VERSION ""

NS_ :

BS_:

BU_: Turbocharger OnBoardDataLogger OffBoardDiagnosticTool2 OffBoardDiagnosticTool1 FileServer ParkingBrakeController SeatControl2 FanDriveController SteeringColumnUnit CommunicationUnitRadio CommunicationUnitSatellite CommunicationUnitCellular PropulsionBatteryCharger ChassisController2 ChassisController1 EngineValveControl AuxiliaryHeater2 AuxiliaryHeater1 ClutchUnit RampControl InformationSystem1 SuspensionSystemController2 OilSensor VehicleDynamicStability ExhaustEmissionController TransmissionDisplay2 TransmissionDisplay1 ClimateControl2 WaterPumpController RearAxleSteeringController LightingOperatorControl SeatController1 IgnitionController2 IgnitionController1 TirePressureController CabController2 CabController1 PneumaticSystemController SuspensionSystemController1 HydraulicPumpController EnduranceBrakingSystem RetarderExhaustEngine2 OnBoardDiagnosticUnit HeadwayController RetarderExhaustEngine1 CabDisplay1 ManagementComputer VirtualTerminal OffVehicleGateway PowerTakeOffFront HitchControl AuxiliaryValveControl BodyController TractorTrailerBridge1 StarterSystem ElectricalSystem VehicleSecurity VehicleNavigation AerodynamicControl ElectricalChargingSystem ClimateControl1 TripRecorder InstrumentCluster SuspensionDriveAxle2 SuspensionDriveAxle1 SuspensionSteerAxle SteeringController FuelSystem CruiseControl RetarderDriveline RetarderEngine BrakesDriveAxle2 BrakesDriveAxle1 BrakesSystemController BrakesSteerAxle AxleDrive2 AxleDrive1 AxleSteering PowerTakeOff ShiftConsoleSecondary ShiftConsolePrimary Transmission2 Transmission1 Engine2 Engine1

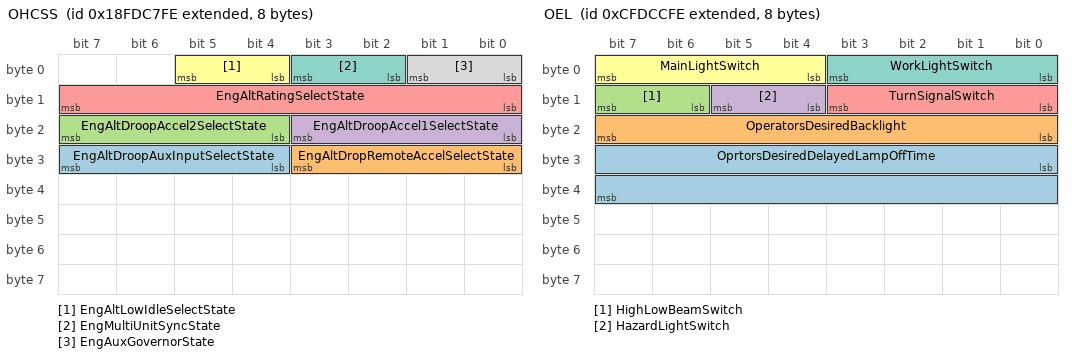
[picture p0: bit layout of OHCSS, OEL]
BO_ 2566768638 OHCSS: 8 Vector__XXX
 SG_ EngAltDroopAuxInputSelectState : 28|4@1+ (1,0) [0|15] "" Vector__XXX
 SG_ EngAltDropRemoteAccelSelectState : 24|4@1+ (1,0) [0|15] "" Vector__XXX
 SG_ EngAltDroopAccel2SelectState : 20|4@1+ (1,0) [0|15] "" Vector__XXX
 SG_ EngAltDroopAccel1SelectState : 16|4@1+ (1,0) [0|15] "" Vector__XXX
 SG_ EngAltRatingSelectState : 8|8@1+ (1,0) [0|255] "" Vector__XXX
 SG_ EngAltLowIdleSelectState : 4|2@1+ (1,0) [0|3] "" Vector__XXX
 SG_ EngMultiUnitSyncState : 2|2@1+ (1,0) [0|3] "" Vector__XXX
 SG_ EngAuxGovernorState : 0|2@1+ (1,0) [0|3] "" Vector__XXX

BO_ 2365443326 OEL: 8 Vector__XXX
 SG_ OprtorsDesiredDelayedLampOffTime : 24|16@1+ (1,0) [0|64255] "s" Vector__XXX
 SG_ OperatorsDesiredBacklight : 16|8@1+ (0.4,0) [0|100] "%" Vector__XXX
 SG_ HighLowBeamSwitch : 14|2@1+ (1,0) [0|3] "" Vector__XXX
 SG_ HazardLightSwitch : 12|2@1+ (1,0) [0|3] "" Vector__XXX
 SG_ TurnSignalSwitch : 8|4@1+ (1,0) [0|15] "" Vector__XXX
 SG_ MainLightSwitch : 4|4@1+ (1,0) [0|15] "" Vector__XXX
 SG_ WorkLightSwitch : 0|4@1+ (1,0) [0|15] "" Vector__XXX

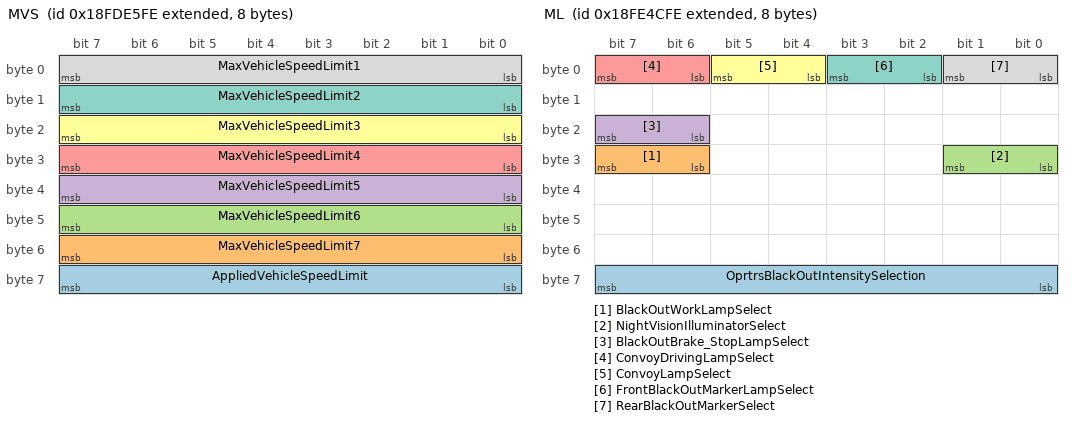
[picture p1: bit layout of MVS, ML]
BO_ 2566776318 MVS: 8 Vector__XXX
 SG_ AppliedVehicleSpeedLimit : 56|8@1+ (1,0) [0|250] "km/h" Vector__XXX
 SG_ MaxVehicleSpeedLimit7 : 48|8@1+ (1,0) [0|250] "km/h" Vector__XXX
 SG_ MaxVehicleSpeedLimit6 : 40|8@1+ (1,0) [0|250] "km/h" Vector__XXX
 SG_ MaxVehicleSpeedLimit5 : 32|8@1+ (1,0) [0|250] "km/h" Vector__XXX
 SG_ MaxVehicleSpeedLimit4 : 24|8@1+ (1,0) [0|250] "km/h" Vector__XXX
 SG_ MaxVehicleSpeedLimit3 : 16|8@1+ (1,0) [0|250] "km/h" Vector__XXX
 SG_ MaxVehicleSpeedLimit2 : 8|8@1+ (1,0) [0|250] "km/h" Vector__XXX
 SG_ MaxVehicleSpeedLimit1 : 0|8@1+ (1,0) [0|250] "km/h" Vector__XXX

BO_ 2566802686 ML: 8 Vector__XXX
 SG_ OprtrsBlackOutIntensitySelection : 56|8@1+ (1,0) [0|100] "%" Vector__XXX
 SG_ BlackOutWorkLampSelect : 30|2@1+ (1,0) [0|3] "" Vector__XXX
 SG_ NightVisionIlluminatorSelect : 24|2@1+ (1,0) [0|3] "" Vector__XXX
 SG_ BlackOutBrake_StopLampSelect : 22|2@1+ (1,0) [0|3] "" Vector__XXX
 SG_ ConvoyDrivingLampSelect : 6|2@1+ (1,0) [0|3] "" Vector__XXX
 SG_ ConvoyLampSelect : 4|2@1+ (1,0) [0|3] "" Vector__XXX
 SG_ FrontBlackOutMarkerLampSelect : 2|2@1+ (1,0) [0|3] "" Vector__XXX
 SG_ RearBlackOutMarkerSelect : 0|2@1+ (1,0) [0|3] "" Vector__XXX

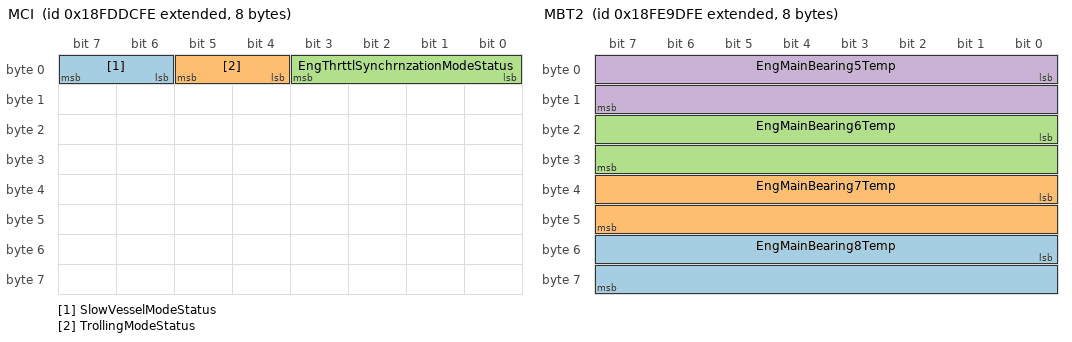
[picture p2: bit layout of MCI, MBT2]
BO_ 2566774014 MCI: 8 Vector__XXX
 SG_ SlowVesselModeStatus : 6|2@1+ (1,0) [0|3] "" Vector__XXX
 SG_ TrollingModeStatus : 4|2@1+ (1,0) [0|3] "" Vector__XXX
 SG_ EngThrttlSynchrnzationModeStatus : 0|4@1+ (1,0) [0|15] "" Vector__XXX

BO_ 2566823166 MBT3: 8 Vector__XXX
 SG_ EngMainBearing11Temp : 32|16@1+ (0.03125,-273) [-273|1734.96875] "deg C" Vector__XXX
 SG_ EngMainBearing10Temp : 16|16@1+ (0.03125,-273) [-273|1734.96875] "deg C" Vector__XXX
 SG_ EngMainBearing9Temp : 0|16@1+ (0.03125,-273) [-273|1734.96875] "deg C" Vector__XXX

BO_ 2566823422 MBT2: 8 Vector__XXX
 SG_ EngMainBearing8Temp : 48|16@1+ (0.03125,-273) [-273|1734.96875] "deg C" Vector__XXX
 SG_ EngMainBearing7Temp : 32|16@1+ (0.03125,-273) [-273|1734.96875] "deg C" Vector__XXX
 SG_ EngMainBearing6Temp : 16|16@1+ (0.03125,-273) [-273|1734.96875] "deg C" Vector__XXX
 SG_ EngMainBearing5Temp : 0|16@1+ (0.03125,-273) [-273|1734.96875] "deg C" Vector__XXX

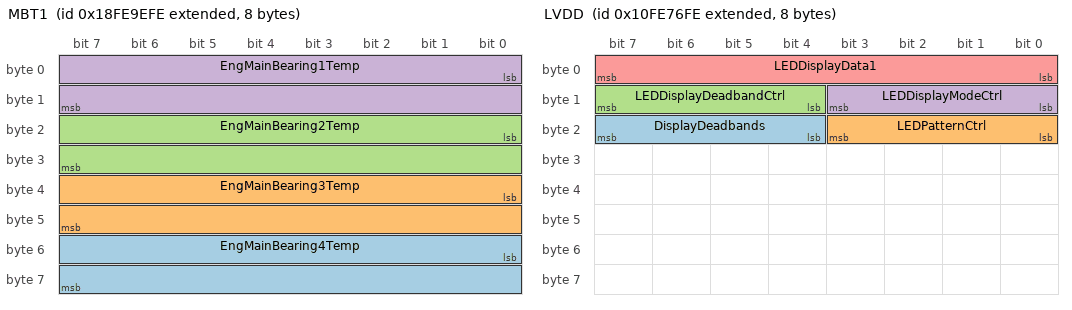
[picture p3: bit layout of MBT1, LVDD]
BO_ 2566823678 MBT1: 8 Vector__XXX
 SG_ EngMainBearing4Temp : 48|16@1+ (0.03125,-273) [-273|1734.96875] "deg C" Vector__XXX
 SG_ EngMainBearing3Temp : 32|16@1+ (0.03125,-273) [-273|1734.96875] "deg C" Vector__XXX
 SG_ EngMainBearing2Temp : 16|16@1+ (0.03125,-273) [-273|1734.96875] "deg C" Vector__XXX
 SG_ EngMainBearing1Temp : 0|16@1+ (0.03125,-273) [-273|1734.96875] "deg C" Vector__XXX

BO_ 2432595710 LVDD: 8 Vector__XXX
 SG_ DisplayDeadbands : 20|4@1+ (1,0) [0|15] "" Vector__XXX
 SG_ LEDPatternCtrl : 16|4@1+ (1,0) [0|15] "" Vector__XXX
 SG_ LEDDisplayDeadbandCtrl : 12|4@1+ (1,0) [0|15] "" Vector__XXX
 SG_ LEDDisplayModeCtrl : 8|4@1+ (1,0) [0|15] "" Vector__XXX
 SG_ LEDDisplayData1 : 0|8@1+ (1,0) [0|255] "" Vector__XXX

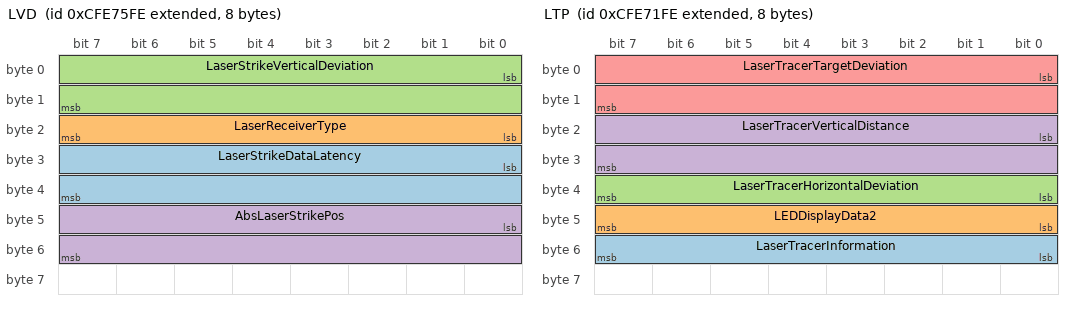
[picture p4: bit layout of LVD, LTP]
BO_ 2365486590 LVD: 8 Vector__XXX
 SG_ LaserStrikeDataLatency : 24|16@1+ (5.12E-005,0) [0|3.289856] "s" Vector__XXX
 SG_ LaserReceiverType : 16|8@1+ (1,0) [0|250] "" Vector__XXX
 SG_ LaserStrikeVerticalDeviation : 0|16@1+ (0.1,-3200) [-3200|3225.5] "mm" Vector__XXX
 SG_ AbsLaserStrikePos : 40|16@1+ (0.1,0) [0|6425.5] "mm" Vector__XXX

BO_ 2365485566 LTP: 8 Vector__XXX
 SG_ LaserTracerInformation : 48|8@1+ (1,0) [0|255] "" Vector__XXX
 SG_ LEDDisplayData2 : 40|8@1+ (1,0) [0|255] "" Vector__XXX
 SG_ LaserTracerHorizontalDeviation : 32|8@1+ (1,0) [0|250] "%" Vector__XXX
 SG_ LaserTracerVerticalDistance : 16|16@1+ (0.1,0) [0|6425.5] "mm" Vector__XXX
 SG_ LaserTracerTargetDeviation : 0|16@1+ (0.1,-3200) [-3200|3225.5] "mm" Vector__XXX

BO_ 2633939454 LTFI: 22 Vector__XXX
 SG_ TripCruiseFuelUsed : 128|32@1+ (0.5,0) [0|2105540607.5] "L" Vector__XXX
 SG_ TripVehicleIdleFuelUsed : 96|32@1+ (0.5,0) [0|2105540607.5] "L" Vector__XXX
 SG_ TripDriveFuelUsed : 0|32@1+ (0.5,0) [0|2105540607.5] "L" Vector__XXX
 SG_ TripPTOGovernorNonmovingFuelUsed : 64|32@1+ (0.5,0) [0|2105540607.5] "L" Vector__XXX
 SG_ TripPTOGovernorMovingFuelUsed : 32|32@1+ (0.5,0) [0|2105540607.5] "L" Vector__XXX
 SG_ TripDriveFuelEconomy : 160|16@1+ (0.0019531553964672,0) [0|125.5] "km/L" Vector__XXX

BO_ 2365486334 LSP: 8 Vector__XXX
 SG_ BldeHeightSetPointHighResolution : 16|32@1+ (1E-007,-209.7152) [-209.7152|211.3929215] "m" Vector__XXX
 SG_ ModifyLevelingSystemSetPoint : 0|16@1+ (0.1,-3200) [-3200|3225.5] "mm" Vector__XXX

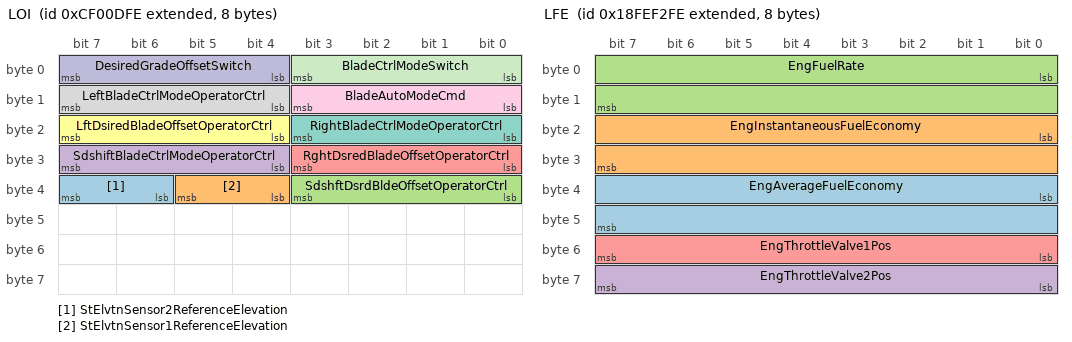
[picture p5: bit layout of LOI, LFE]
BO_ 2364542462 LOI: 8 Vector__XXX
 SG_ StElvtnSensor2ReferenceElevation : 38|2@1+ (1,0) [0|3] "" Vector__XXX
 SG_ StElvtnSensor1ReferenceElevation : 36|2@1+ (1,0) [0|3] "" Vector__XXX
 SG_ SdshftDsrdBldeOffsetOperatorCtrl : 32|4@1+ (1,0) [0|15] "" Vector__XXX
 SG_ SdshiftBladeCtrlModeOperatorCtrl : 28|4@1+ (1,0) [0|15] "" Vector__XXX
 SG_ RghtDsredBladeOffsetOperatorCtrl : 24|4@1+ (1,0) [0|15] "" Vector__XXX
 SG_ LftDsiredBladeOffsetOperatorCtrl : 20|4@1+ (1,0) [0|15] "" Vector__XXX
 SG_ RightBladeCtrlModeOperatorCtrl : 16|4@1+ (1,0) [0|15] "" Vector__XXX
 SG_ LeftBladeCtrlModeOperatorCtrl : 12|4@1+ (1,0) [0|15] "" Vector__XXX
 SG_ BladeAutoModeCmd : 8|4@1+ (1,0) [0|15] "" Vector__XXX
 SG_ DesiredGradeOffsetSwitch : 4|4@1+ (1,0) [0|15] "" Vector__XXX
 SG_ BladeCtrlModeSwitch : 0|4@1+ (1,0) [0|0] "" Vector__XXX

BO_ 2365486078 LMP: 8 Vector__XXX
 SG_ MastPos : 0|16@1+ (0.1,-3200) [-3200|3225.5] "mm" Vector__XXX

BO_ 2633937918 LFI: 8 Vector__XXX
 SG_ FlexibleFuelPercentage : 48|10@1+ (1,0) [0|102] "%" Vector__XXX
 SG_ TripAverageFuelRate : 32|16@1+ (0.05,0) [0|3212.75] "L/h" Vector__XXX
 SG_ TotalEngPTOGovernorFuelUsed : 0|32@1+ (0.5,0) [0|2105540607.5] "L" Vector__XXX

BO_ 2566845182 LFE: 8 Vector__XXX
 SG_ EngAverageFuelEconomy : 32|16@1+ (0.0019531553964672,0) [0|125.5] "km/L" Vector__XXX
 SG_ EngInstantaneousFuelEconomy : 16|16@1+ (0.0019531553964672,0) [0|125.5] "km/L" Vector__XXX
 SG_ EngFuelRate : 0|16@1+ (0.05,0) [0|3212.75] "L/h" Vector__XXX
 SG_ EngThrottleValve2Pos : 56|8@1+ (0.4,0) [0|100] "%" Vector__XXX
 SG_ EngThrottleValve1Pos : 48|8@1+ (0.4,0) [0|100] "%" Vector__XXX

BO_ 2566842878 LFC: 8 Vector__XXX
 SG_ EngTotalFuelUsed : 32|32@1+ (0.5,0) [0|2105540607.5] "L" Vector__XXX
 SG_ EngTripFuel : 0|32@1+ (0.5,0) [0|2105540607.5] "L" Vector__XXX

BO_ 2633883646 FWD: 8 Vector__XXX
 SG_ FrontWheelDriveActuatorStatus : 0|2@1+ (1,0) [0|3] "" Vector__XXX

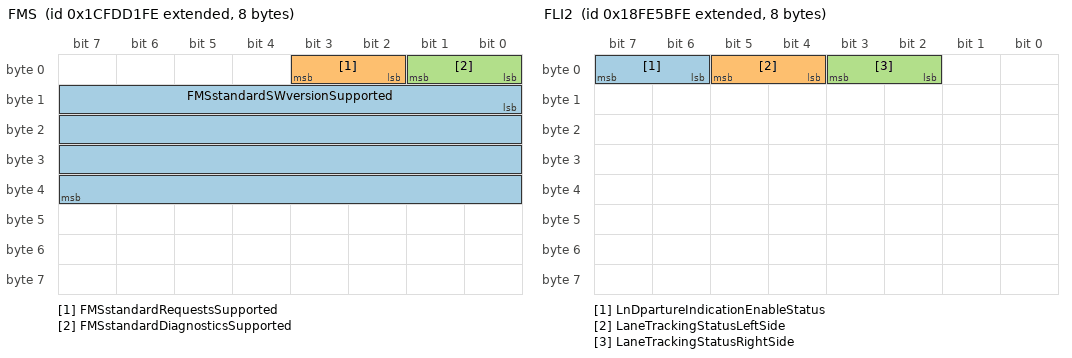
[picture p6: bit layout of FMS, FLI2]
BO_ 2633880062 FMS: 8 Vector__XXX
 SG_ FMSstandardSWversionSupported : 8|32@1+ (6.0554519606908E-008,0) [0|255] "per byte" Vector__XXX
 SG_ FMSstandardRequestsSupported : 2|2@1+ (1,0) [0|3] "" Vector__XXX
 SG_ FMSstandardDiagnosticsSupported : 0|2@1+ (1,0) [0|3] "" Vector__XXX

BO_ 2566806526 FLI2: 8 Vector__XXX
 SG_ LnDpartureIndicationEnableStatus : 6|2@1+ (1,0) [0|3] "" Vector__XXX
 SG_ LaneTrackingStatusLeftSide : 4|2@1+ (1,0) [0|3] "" Vector__XXX
 SG_ LaneTrackingStatusRightSide : 2|2@1+ (1,0) [0|3] "" Vector__XXX

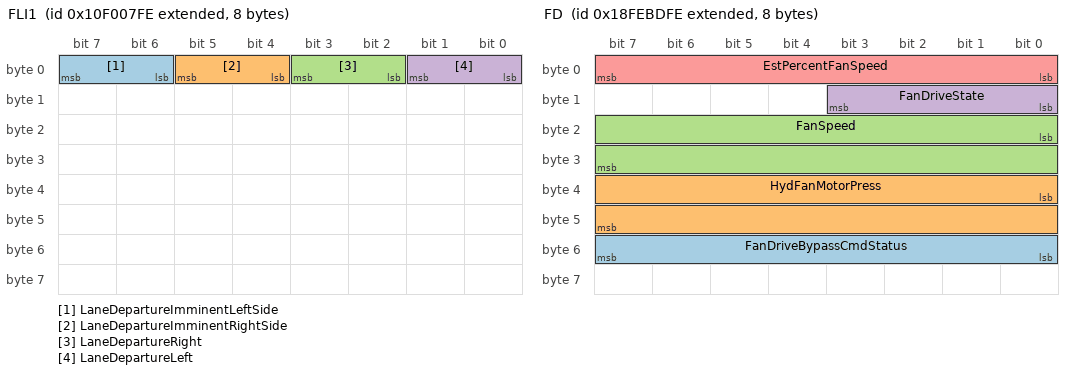
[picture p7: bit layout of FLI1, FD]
BO_ 2431649790 FLI1: 8 Vector__XXX
 SG_ LaneDepartureImminentLeftSide : 6|2@1+ (1,0) [0|3] "" Vector__XXX
 SG_ LaneDepartureImminentRightSide : 4|2@1+ (1,0) [0|3] "" Vector__XXX
 SG_ LaneDepartureRight : 2|2@1+ (1,0) [0|3] "" Vector__XXX
 SG_ LaneDepartureLeft : 0|2@1+ (1,0) [0|3] "" Vector__XXX

BO_ 2633929214 FL: 8 Vector__XXX
 SG_ EngFuelLeakage2 : 2|2@1+ (1,0) [0|3] "" Vector__XXX
 SG_ EngFuelLeakage1 : 0|2@1+ (1,0) [0|3] "" Vector__XXX

BO_ 2566831614 FD: 8 Vector__XXX
 SG_ FanDriveBypassCmdStatus : 48|8@1+ (1,0) [0|100] "%" Vector__XXX
 SG_ HydFanMotorPress : 32|16@1+ (0.5,0) [0|32127.5] "kPa" Vector__XXX
 SG_ FanSpeed : 16|16@1+ (0.125,0) [0|8031.875] "rpm" Vector__XXX
 SG_ FanDriveState : 8|4@1+ (1,0) [0|15] "" Vector__XXX
 SG_ EstPercentFanSpeed : 0|8@1+ (1,0) [0|100] "%" Vector__XXX

BO_ 2566820094 ETH: 8 Vector__XXX
 SG_ EngTorqueLimit6AxleInput : 248|16@1+ (2,0) [0|128510] "Nm" Vector__XXX
 SG_ EngTorqueLimit5Switch : 232|16@1+ (1,0) [0|64255] "Nm" Vector__XXX
 SG_ EngTorqueLimit4Trans : 216|16@1+ (1,0) [0|64255] "Nm" Vector__XXX
 SG_ EngTorqueLimit3Trans : 200|16@1+ (1,0) [0|64255] "Nm" Vector__XXX
 SG_ TransGearRatio3 : 184|16@1+ (0.01,0) [0|642.55] "" Vector__XXX
 SG_ EngTorqueLimit2Trans : 168|16@1+ (1,0) [0|64255] "Nm" Vector__XXX
 SG_ TransGearRatio2 : 152|16@1+ (0.01,0) [0|642.55] "" Vector__XXX
 SG_ EngTorqueLimit1Trans : 136|16@1+ (1,0) [0|64255] "Nm" Vector__XXX
 SG_ TransGearRatio1 : 120|16@1+ (0.01,0) [0|642.55] "" Vector__XXX
 SG_ EngTorqueLimitFeature : 114|3@1+ (1,0) [0|7] "" Vector__XXX
 SG_ TorqueLimitingFeatureStatus : 112|2@1+ (1,0) [0|3] "" Vector__XXX
 SG_ CalibRecordDurationTime : 80|32@1+ (0.05,0) [0|210554060.75] "hr" Vector__XXX
 SG_ CalibRecordStartYear : 72|8@1+ (1,1985) [1985|2235] "years" Vector__XXX
 SG_ CalibRecordStartDay : 64|8@1+ (0.25,0) [0|62.5] "days" Vector__XXX
 SG_ CalibRecordStartMonth : 56|8@1+ (1,0) [0|250] "months" Vector__XXX
 SG_ EngPeakTorque2 : 40|16@1+ (1,0) [0|64255] "Nm" Vector__XXX
 SG_ EngPeakTorque1 : 24|16@1+ (1,0) [0|64255] "Nm" Vector__XXX
 SG_ EngPower : 8|16@1+ (0.5,0) [0|32127.5] "kW" Vector__XXX
 SG_ NumberOfEngTorqueHistoryRecords : 0|8@1+ (1,0) [0|250] "records" Vector__XXX

BO_ 2364542206 ETC8: 8 Vector__XXX
 SG_ TransClutch_ConverterInputSpeed : 16|16@1+ (0.125,0) [0|8031.875] "rpm" Vector__XXX
 SG_ TransTorqueConverterRatio : 0|16@1+ (0.001,0) [0|64.255] "" Vector__XXX

BO_ 2566802174 ETC7: 8 Vector__XXX
 SG_ TrnsRverseGearShiftInhibitStatus : 40|2@1+ (1,0) [0|3] "" Vector__XXX
 SG_ TrnsCrrentRangeDisplayBlankState : 0|2@1+ (1,0) [0|3] "" Vector__XXX
 SG_ TransWarningIndicator : 42|2@1+ (1,0) [0|3] "" Vector__XXX
 SG_ TransMode8Indicator : 38|2@1+ (1,0) [0|3] "" Vector__XXX
 SG_ TransMode7Indicator : 36|2@1+ (1,0) [0|3] "" Vector__XXX
 SG_ TransMode6Indicator : 34|2@1+ (1,0) [0|3] "" Vector__XXX
 SG_ TransMode5Indicator : 32|2@1+ (1,0) [0|3] "" Vector__XXX
 SG_ TransRequestedGearFeedback : 24|8@1+ (1,-125) [-125|125] "" Vector__XXX
 SG_ TransMode1Indicator : 22|2@1+ (1,0) [0|3] "" Vector__XXX
 SG_ TransMode2Indicator : 20|2@1+ (1,0) [0|3] "" Vector__XXX
 SG_ TransMode3Indicator : 18|2@1+ (1,0) [0|3] "" Vector__XXX
 SG_ TransMode4Indicator : 16|2@1+ (1,0) [0|3] "" Vector__XXX
 SG_ TransShiftInhibitIndicator : 14|2@1+ (1,0) [0|3] "" Vector__XXX
 SG_ TransEngCrankEnable : 12|2@1+ (1,0) [0|3] "" Vector__XXX
 SG_ ActiveShiftConsoleIndicator : 10|2@1+ (1,0) [0|3] "" Vector__XXX
 SG_ TransReadyForBrakeRelease : 8|2@1+ (1,0) [0|3] "" Vector__XXX
 SG_ TrnsRqstedRangeDisplayFlashState : 6|2@1+ (1,0) [0|3] "" Vector__XXX
 SG_ TrnsRqstedRangeDisplayBlankState : 4|2@1+ (1,0) [0|3] "" Vector__XXX
 SG_ TransServiceIndicator : 2|2@1+ (1,0) [0|3] "" Vector__XXX

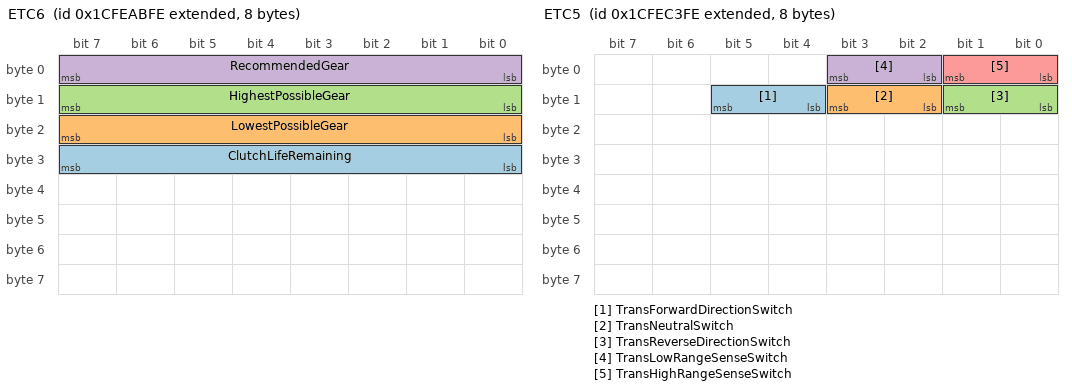
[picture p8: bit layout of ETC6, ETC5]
BO_ 2633935870 ETC6: 8 Vector__XXX
 SG_ ClutchLifeRemaining : 24|8@1+ (0.4,0) [0|100] "%" Vector__XXX
 SG_ LowestPossibleGear : 16|8@1+ (1,-125) [-125|125] "" Vector__XXX
 SG_ HighestPossibleGear : 8|8@1+ (1,-125) [-125|125] "" Vector__XXX
 SG_ RecommendedGear : 0|8@1+ (1,-125) [-125|125] "" Vector__XXX

BO_ 2633942014 ETC5: 8 Vector__XXX
 SG_ TransForwardDirectionSwitch : 12|2@1+ (1,0) [0|3] "" Vector__XXX
 SG_ TransNeutralSwitch : 10|2@1+ (1,0) [0|3] "" Vector__XXX
 SG_ TransReverseDirectionSwitch : 8|2@1+ (1,0) [0|3] "" Vector__XXX
 SG_ TransLowRangeSenseSwitch : 2|2@1+ (1,0) [0|3] "" Vector__XXX
 SG_ TransHighRangeSenseSwitch : 0|2@1+ (1,0) [0|3] "" Vector__XXX

BO_ 2633942526 ETC4: 8 Vector__XXX
 SG_ TransSynchronizerBrakeValue : 8|8@1+ (0.4,0) [0|100] "%" Vector__XXX
 SG_ TransSynchronizerClutchValue : 0|8@1+ (0.4,0) [0|100] "%" Vector__XXX

BO_ 2633943038 ETC3: 8 Vector__XXX
 SG_ TransInertiaBrakeActuator : 46|2@1+ (1,0) [0|3] "" Vector__XXX
 SG_ TransDefuelActuator : 44|2@1+ (1,0) [0|3] "" Vector__XXX
 SG_ TransLockupClutchActuator : 42|2@1+ (1,0) [0|3] "" Vector__XXX
 SG_ TransClutchActuator : 40|2@1+ (1,0) [0|3] "" Vector__XXX
 SG_ TransSplitterIndirectActuator : 38|2@1+ (1,0) [0|3] "" Vector__XXX
 SG_ TransSplitterDirectActuator : 36|2@1+ (1,0) [0|3] "" Vector__XXX
 SG_ TransRangeLowActuator : 34|2@1+ (1,0) [0|3] "" Vector__XXX
 SG_ TransRangeHighActuator : 32|2@1+ (1,0) [0|3] "" Vector__XXX
 SG_ TransShiftFingerGearActuator2 : 30|2@1+ (1,0) [0|3] "" Vector__XXX
 SG_ TransShiftFingerRailActuator2 : 28|2@1+ (1,0) [0|3] "" Vector__XXX
 SG_ TransShiftFingerGearActuator1 : 26|2@1+ (1,0) [0|3] "" Vector__XXX
 SG_ TransShiftFingerRailActuator1 : 24|2@1+ (1,0) [0|3] "" Vector__XXX
 SG_ TrnsShftFngerCenterRailIndicator : 20|2@1+ (1,0) [0|3] "" Vector__XXX
 SG_ TrnsShftFngerEngagementIndicator : 18|2@1+ (1,0) [0|3] "" Vector__XXX
 SG_ TransShiftFingerNeutralIndicator : 16|2@1+ (1,0) [0|3] "" Vector__XXX
 SG_ TransShiftFingerRailPos : 8|8@1+ (0.4,0) [0|100] "%" Vector__XXX
 SG_ TransShiftFingerGearPos : 0|8@1+ (0.4,0) [0|100] "%" Vector__XXX

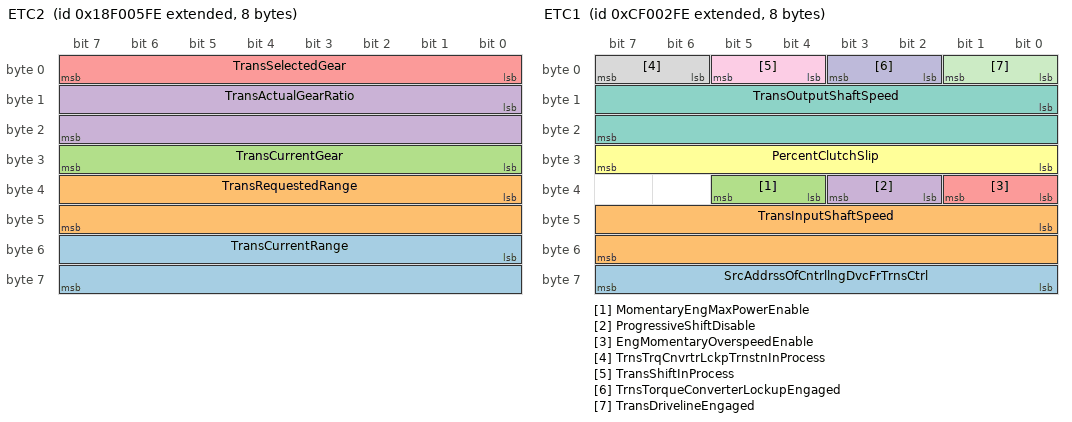
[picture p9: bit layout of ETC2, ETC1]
BO_ 2565867006 ETC2: 8 Vector__XXX
 SG_ TransCurrentRange : 48|16@1+ (1,0) [0|255] "per byte" Vector__XXX
 SG_ TransRequestedRange : 32|16@1+ (1,0) [0|255] "per byte" Vector__XXX
 SG_ TransCurrentGear : 24|8@1+ (1,-125) [-125|125] "" Vector__XXX
 SG_ TransActualGearRatio : 8|16@1+ (0.001,0) [0|64.255] "" Vector__XXX
 SG_ TransSelectedGear : 0|8@1+ (1,-125) [-125|125] "" Vector__XXX

BO_ 2364539646 ETC1: 8 Vector__XXX
 SG_ SrcAddrssOfCntrllngDvcFrTrnsCtrl : 56|8@1+ (1,0) [0|255] "" Vector__XXX
 SG_ TransInputShaftSpeed : 40|16@1+ (0.125,0) [0|8031.875] "rpm" Vector__XXX
 SG_ MomentaryEngMaxPowerEnable : 36|2@1+ (1,0) [0|3] "" Vector__XXX
 SG_ ProgressiveShiftDisable : 34|2@1+ (1,0) [0|3] "" Vector__XXX
 SG_ EngMomentaryOverspeedEnable : 32|2@1+ (1,0) [0|3] "" Vector__XXX
 SG_ PercentClutchSlip : 24|8@1+ (0.4,0) [0|100] "%" Vector__XXX
 SG_ TransOutputShaftSpeed : 8|16@1+ (0.125,0) [0|8031.875] "rpm" Vector__XXX
 SG_ TrnsTrqCnvrtrLckpTrnstnInProcess : 6|2@1+ (1,0) [0|3] "" Vector__XXX
 SG_ TransShiftInProcess : 4|2@1+ (1,0) [0|3] "" Vector__XXX
 SG_ TrnsTorqueConverterLockupEngaged : 2|2@1+ (1,0) [0|3] "" Vector__XXX
 SG_ TransDrivelineEngaged : 0|2@1+ (1,0) [0|3] "" Vector__XXX

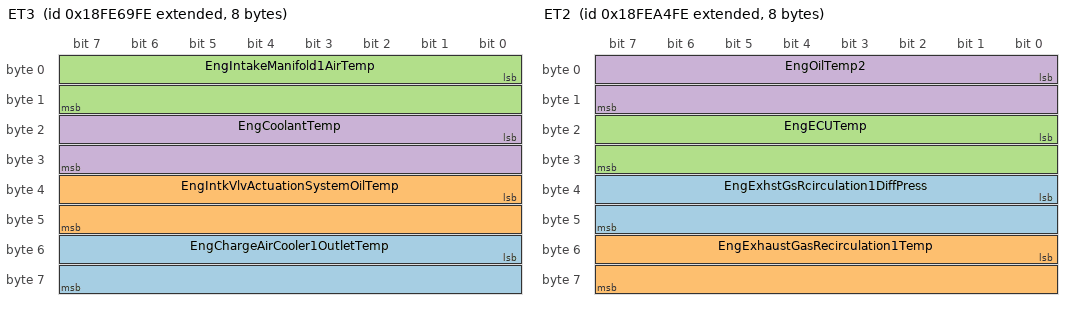
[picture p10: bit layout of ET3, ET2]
BO_ 2566810110 ET3: 8 Vector__XXX
 SG_ EngChargeAirCooler1OutletTemp : 48|16@1+ (0.03125,-273) [-273|1734.96875] "deg C" Vector__XXX
 SG_ EngIntkVlvActuationSystemOilTemp : 32|16@1+ (0.03125,-273) [-273|1734.96875] "deg C" Vector__XXX
 SG_ EngIntakeManifold1AirTemp : 0|16@1+ (0.03125,-273) [-273|1734.96875] "deg C" Vector__XXX
 SG_ EngCoolantTemp : 16|16@1+ (0.03125,-273) [-273|1734.96875] "deg C" Vector__XXX

BO_ 2566825214 ET2: 8 Vector__XXX
 SG_ EngExhstGsRcirculation1DiffPress : 32|16@1+ (0.0078124659559567,-250) [-250|251.99] "kPa" Vector__XXX
 SG_ EngExhaustGasRecirculation1Temp : 48|16@1+ (0.03125,-273) [-273|1734.96875] "deg C" Vector__XXX
 SG_ EngECUTemp : 16|16@1+ (0.03125,-273) [-273|1734.96875] "deg C" Vector__XXX
 SG_ EngOilTemp2 : 0|16@1+ (0.03125,-273) [-273|1734.96875] "deg C" Vector__XXX

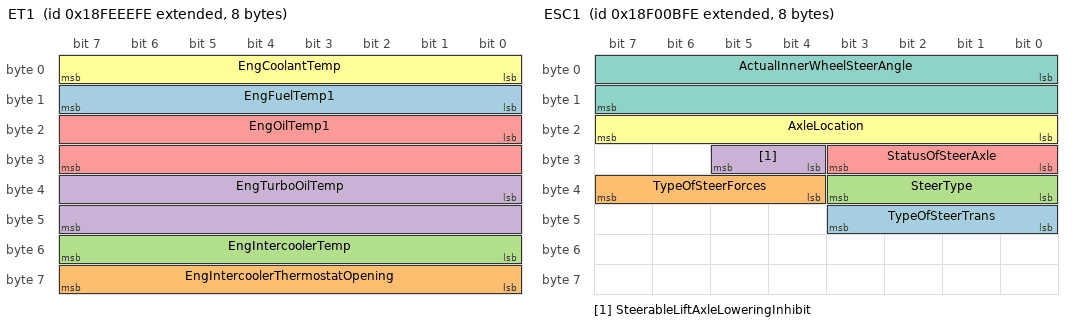
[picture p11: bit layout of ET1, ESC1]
BO_ 2566844158 ET1: 8 Vector__XXX
 SG_ EngFuelTemp1 : 8|8@1+ (1,-40) [-40|210] "deg C" Vector__XXX
 SG_ EngIntercoolerThermostatOpening : 56|8@1+ (0.4,0) [0|100] "%" Vector__XXX
 SG_ EngIntercoolerTemp : 48|8@1+ (1,-40) [-40|210] "deg C" Vector__XXX
 SG_ EngTurboOilTemp : 32|16@1+ (0.03125,-273) [-273|1734.96875] "deg C" Vector__XXX
 SG_ EngOilTemp1 : 16|16@1+ (0.03125,-273) [-273|1734.96875] "deg C" Vector__XXX
 SG_ EngCoolantTemp : 0|8@1+ (1,-40) [-40|210] "deg C" Vector__XXX

BO_ 2566785022 ET: 8 Vector__XXX
 SG_ EngExhaustGasTempLeftManifold : 16|16@1+ (0.03125,-273) [-273|1734.96875] "deg C" Vector__XXX
 SG_ EngExhaustGasTempRightManifold : 0|16@1+ (0.03125,-273) [-273|1734.96875] "deg C" Vector__XXX

BO_ 2565868542 ESC1: 8 Vector__XXX
 SG_ TypeOfSteerTrans : 40|4@1+ (1,0) [0|15] "" Vector__XXX
 SG_ TypeOfSteerForces : 36|4@1+ (1,0) [0|15] "" Vector__XXX
 SG_ SteerType : 32|4@1+ (1,0) [0|15] "" Vector__XXX
 SG_ SteerableLiftAxleLoweringInhibit : 28|2@1+ (1,0) [0|3] "" Vector__XXX
 SG_ StatusOfSteerAxle : 24|4@1+ (1,0) [0|15] "" Vector__XXX
 SG_ AxleLocation : 16|8@1+ (1.02,0) [0|255] "" Vector__XXX
 SG_ ActualInnerWheelSteerAngle : 0|16@1+ (0.0038907478017275,-125) [-125|125] "deg" Vector__XXX

BO_ 2633941758 ERC2: 8 Vector__XXX
 SG_ TransOutputRetarder : 0|2@1+ (1,0) [0|3] "" Vector__XXX

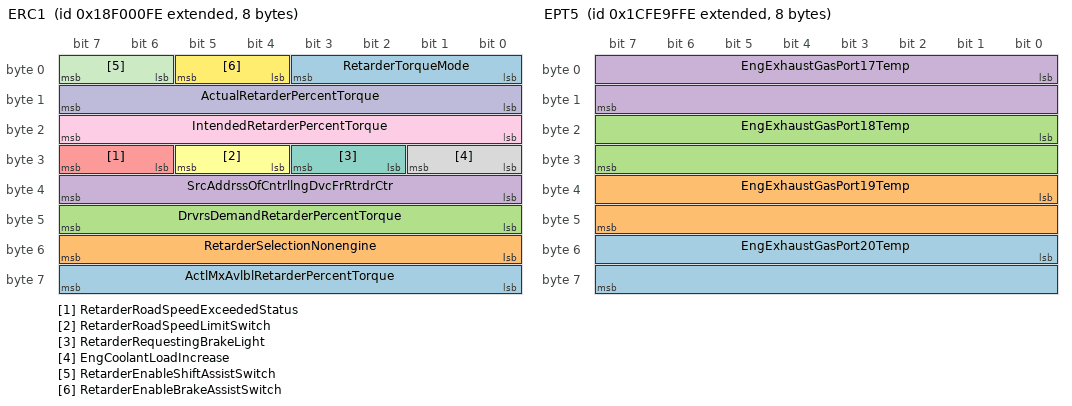
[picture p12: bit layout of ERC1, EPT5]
BO_ 2565865726 ERC1: 8 Vector__XXX
 SG_ ActlMxAvlblRetarderPercentTorque : 56|8@1+ (1,-125) [-125|125] "%" Vector__XXX
 SG_ RetarderSelectionNonengine : 48|8@1+ (0.4,0) [0|100] "%" Vector__XXX
 SG_ DrvrsDemandRetarderPercentTorque : 40|8@1+ (1,-125) [-125|125] "%" Vector__XXX
 SG_ SrcAddrssOfCntrllngDvcFrRtrdrCtr : 32|8@1+ (1,0) [0|255] "" Vector__XXX
 SG_ RetarderRoadSpeedExceededStatus : 30|2@1+ (1,0) [0|3] "" Vector__XXX
 SG_ RetarderRoadSpeedLimitSwitch : 28|2@1+ (1,0) [0|3] "" Vector__XXX
 SG_ RetarderRequestingBrakeLight : 26|2@1+ (1,0) [0|3] "" Vector__XXX
 SG_ EngCoolantLoadIncrease : 24|2@1+ (1,0) [0|3] "" Vector__XXX
 SG_ IntendedRetarderPercentTorque : 16|8@1+ (1,-125) [-125|125] "%" Vector__XXX
 SG_ ActualRetarderPercentTorque : 8|8@1+ (1,-125) [-125|125] "%" Vector__XXX
 SG_ RetarderEnableShiftAssistSwitch : 6|2@1+ (1,0) [0|3] "" Vector__XXX
 SG_ RetarderEnableBrakeAssistSwitch : 4|2@1+ (1,0) [0|3] "" Vector__XXX
 SG_ RetarderTorqueMode : 0|4@1+ (1,0) [0|15] "" Vector__XXX

BO_ 2633932798 EPT5: 8 Vector__XXX
 SG_ EngExhaustGasPort20Temp : 48|16@1+ (0.03125,-273) [-273|1734.96875] "deg C" Vector__XXX
 SG_ EngExhaustGasPort19Temp : 32|16@1+ (0.03125,-273) [-273|1734.96875] "deg C" Vector__XXX
 SG_ EngExhaustGasPort18Temp : 16|16@1+ (0.03125,-273) [-273|1734.96875] "deg C" Vector__XXX
 SG_ EngExhaustGasPort17Temp : 0|16@1+ (0.03125,-273) [-273|1734.96875] "deg C" Vector__XXX

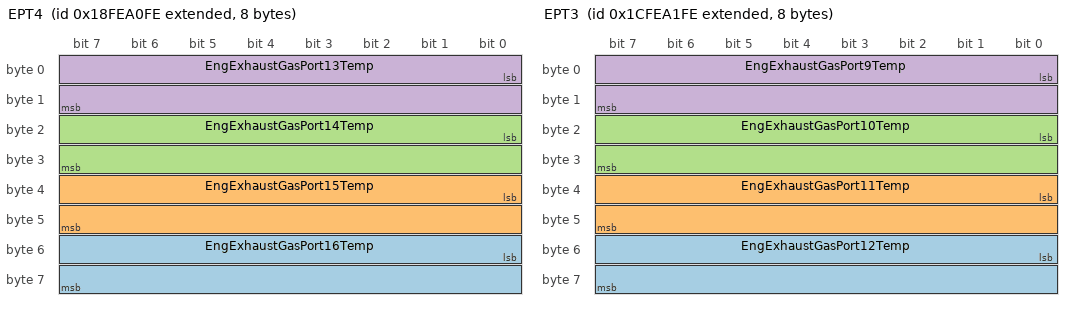
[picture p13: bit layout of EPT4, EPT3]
BO_ 2566824190 EPT4: 8 Vector__XXX
 SG_ EngExhaustGasPort16Temp : 48|16@1+ (0.03125,-273) [-273|1734.96875] "deg C" Vector__XXX
 SG_ EngExhaustGasPort15Temp : 32|16@1+ (0.03125,-273) [-273|1734.96875] "deg C" Vector__XXX
 SG_ EngExhaustGasPort14Temp : 16|16@1+ (0.03125,-273) [-273|1734.96875] "deg C" Vector__XXX
 SG_ EngExhaustGasPort13Temp : 0|16@1+ (0.03125,-273) [-273|1734.96875] "deg C" Vector__XXX

BO_ 2633933310 EPT3: 8 Vector__XXX
 SG_ EngExhaustGasPort12Temp : 48|16@1+ (0.03125,-273) [-273|1734.96875] "deg C" Vector__XXX
 SG_ EngExhaustGasPort11Temp : 32|16@1+ (0.03125,-273) [-273|1734.96875] "deg C" Vector__XXX
 SG_ EngExhaustGasPort10Temp : 16|16@1+ (0.03125,-273) [-273|1734.96875] "deg C" Vector__XXX
 SG_ EngExhaustGasPort9Temp : 0|16@1+ (0.03125,-273) [-273|1734.96875] "deg C" Vector__XXX

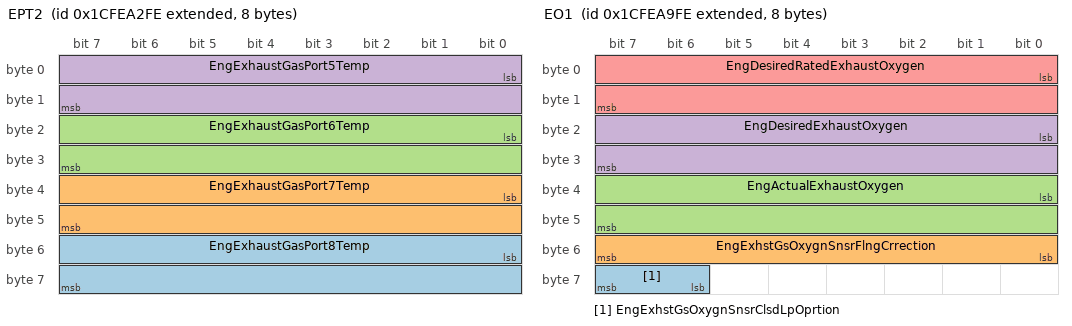
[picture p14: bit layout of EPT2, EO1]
BO_ 2633933566 EPT2: 8 Vector__XXX
 SG_ EngExhaustGasPort8Temp : 48|16@1+ (0.03125,-273) [-273|1734.96875] "deg C" Vector__XXX
 SG_ EngExhaustGasPort7Temp : 32|16@1+ (0.03125,-273) [-273|1734.96875] "deg C" Vector__XXX
 SG_ EngExhaustGasPort6Temp : 16|16@1+ (0.03125,-273) [-273|1734.96875] "deg C" Vector__XXX
 SG_ EngExhaustGasPort5Temp : 0|16@1+ (0.03125,-273) [-273|1734.96875] "deg C" Vector__XXX

BO_ 2633933822 EPT1: 8 Vector__XXX
 SG_ EngExhaustGasPort4Temp : 48|16@1+ (0.03125,-273) [-273|1734.96875] "deg C" Vector__XXX
 SG_ EngExhaustGasPort3Temp : 32|16@1+ (0.03125,-273) [-273|1734.96875] "deg C" Vector__XXX
 SG_ EngExhaustGasPort2Temp : 16|16@1+ (0.03125,-273) [-273|1734.96875] "deg C" Vector__XXX
 SG_ EngExhaustGasPort1Temp : 0|16@1+ (0.03125,-273) [-273|1734.96875] "deg C" Vector__XXX

BO_ 2566776062 EPD: 8 Vector__XXX
 SG_ PayloadPercentage : 0|8@1+ (1,0) [0|250] "%" Vector__XXX

BO_ 2566771454 EP: 8 Vector__XXX
 SG_ DataMemoryUsage : 16|8@1+ (0.4,0) [0|100] "%" Vector__XXX
 SG_ KeepAliveBatteryConsumption : 0|16@1+ (1,0) [0|64255] "mAhr" Vector__XXX

BO_ 2566775806 EOAC: 8 Vector__XXX
 SG_ TravelVelocityCtrlPos : 0|8@1+ (1,-125) [-125|125] "%" Vector__XXX

BO_ 2633935358 EO1: 8 Vector__XXX
 SG_ EngExhstGsOxygnSnsrClsdLpOprtion : 62|2@1+ (1,0) [0|3] "" Vector__XXX
 SG_ EngExhstGsOxygnSnsrFlngCrrection : 48|8@1+ (1,-125) [-125|125] "%" Vector__XXX
 SG_ EngActualExhaustOxygen : 32|16@1+ (0.0025,0) [0|160.6375] "%" Vector__XXX
 SG_ EngDesiredExhaustOxygen : 16|16@1+ (0.0025,0) [0|160.6375] "%" Vector__XXX
 SG_ EngDesiredRatedExhaustOxygen : 0|16@1+ (0.0025,0) [0|160.6375] "%" Vector__XXX

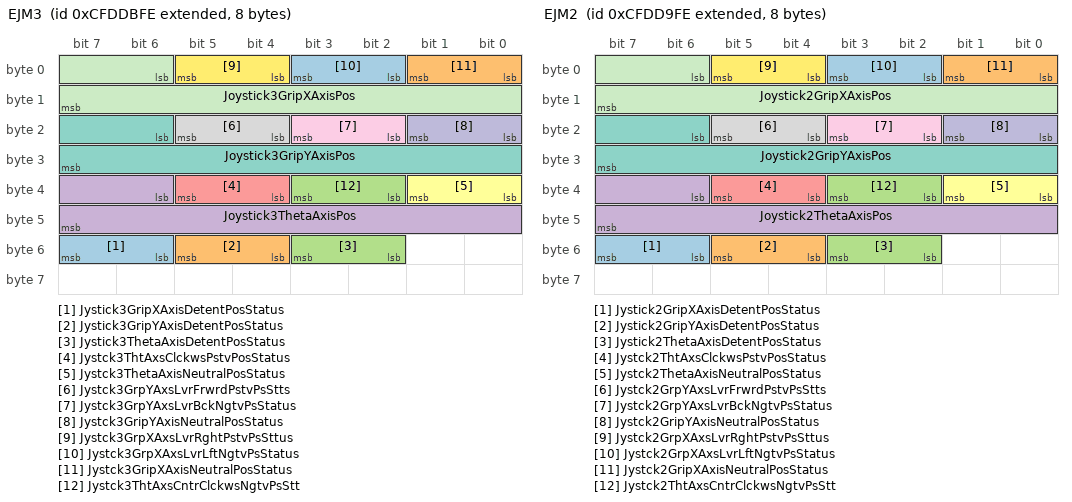
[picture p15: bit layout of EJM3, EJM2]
BO_ 2365447166 EJM3: 8 Vector__XXX
 SG_ Jystick3GripXAxisDetentPosStatus : 54|2@1+ (1,0) [0|3] "" Vector__XXX
 SG_ Jystick3GripYAxisDetentPosStatus : 52|2@1+ (1,0) [0|3] "" Vector__XXX
 SG_ Jystick3ThetaAxisDetentPosStatus : 50|2@1+ (1,0) [0|3] "" Vector__XXX
 SG_ Joystick3ThetaAxisPos : 38|10@1+ (1,0) [0|102] "%" Vector__XXX
 SG_ Jystck3ThtAxsClckwsPstvPosStatus : 36|2@1+ (1,0) [0|3] "" Vector__XXX
 SG_ Jystck3ThetaAxisNeutralPosStatus : 32|2@1+ (1,0) [0|3] "" Vector__XXX
 SG_ Joystick3GripYAxisPos : 22|10@1+ (1,0) [0|102] "%" Vector__XXX
 SG_ Jystck3GrpYAxsLvrFrwrdPstvPsStts : 20|2@1+ (1,0) [0|3] "" Vector__XXX
 SG_ Jystck3GrpYAxsLvrBckNgtvPsStatus : 18|2@1+ (1,0) [0|3] "" Vector__XXX
 SG_ Jystck3GripYAxisNeutralPosStatus : 16|2@1+ (1,0) [0|3] "" Vector__XXX
 SG_ Joystick3GripXAxisPos : 6|10@1+ (1,0) [0|102] "%" Vector__XXX
 SG_ Jystck3GrpXAxsLvrRghtPstvPsSttus : 4|2@1+ (1,0) [0|3] "" Vector__XXX
 SG_ Jystck3GrpXAxsLvrLftNgtvPsStatus : 2|2@1+ (1,0) [0|3] "" Vector__XXX
 SG_ Jystck3GripXAxisNeutralPosStatus : 0|2@1+ (1,0) [0|3] "" Vector__XXX
 SG_ Jystck3ThtAxsCntrClckwsNgtvPsStt : 34|2@1+ (1,0) [0|3] "" Vector__XXX

BO_ 2365446654 EJM2: 8 Vector__XXX
 SG_ Jystick2GripXAxisDetentPosStatus : 54|2@1+ (1,0) [0|3] "" Vector__XXX
 SG_ Jystick2GripYAxisDetentPosStatus : 52|2@1+ (1,0) [0|3] "" Vector__XXX
 SG_ Jystick2ThetaAxisDetentPosStatus : 50|2@1+ (1,0) [0|3] "" Vector__XXX
 SG_ Joystick2ThetaAxisPos : 38|10@1+ (1,0) [0|102] "%" Vector__XXX
 SG_ Jystck2ThtAxsClckwsPstvPosStatus : 36|2@1+ (1,0) [0|3] "" Vector__XXX
 SG_ Jystck2ThetaAxisNeutralPosStatus : 32|2@1+ (1,0) [0|3] "" Vector__XXX
 SG_ Joystick2GripYAxisPos : 22|10@1+ (1,0) [0|102] "%" Vector__XXX
 SG_ Jystck2GrpYAxsLvrFrwrdPstvPsStts : 20|2@1+ (1,0) [0|3] "" Vector__XXX
 SG_ Jystck2GrpYAxsLvrBckNgtvPsStatus : 18|2@1+ (1,0) [0|3] "" Vector__XXX
 SG_ Jystck2GripYAxisNeutralPosStatus : 16|2@1+ (1,0) [0|3] "" Vector__XXX
 SG_ Joystick2GripXAxisPos : 6|10@1+ (1,0) [0|102] "%" Vector__XXX
 SG_ Jystck2GrpXAxsLvrRghtPstvPsSttus : 4|2@1+ (1,0) [0|3] "" Vector__XXX
 SG_ Jystck2GrpXAxsLvrLftNgtvPsStatus : 2|2@1+ (1,0) [0|3] "" Vector__XXX
 SG_ Jystck2GripXAxisNeutralPosStatus : 0|2@1+ (1,0) [0|3] "" Vector__XXX
 SG_ Jystck2ThtAxsCntrClckwsNgtvPsStt : 34|2@1+ (1,0) [0|3] "" Vector__XXX

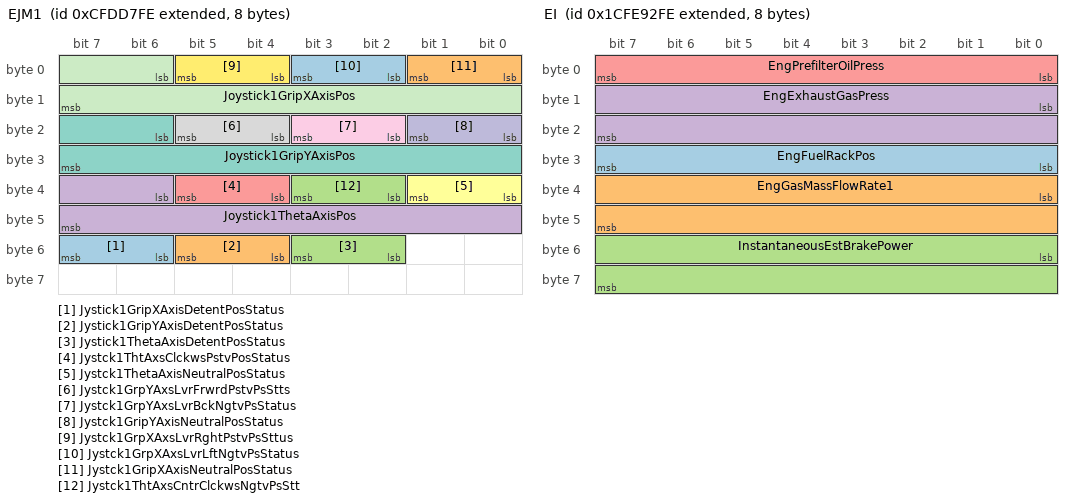
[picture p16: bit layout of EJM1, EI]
BO_ 2365446142 EJM1: 8 Vector__XXX
 SG_ Jystick1GripXAxisDetentPosStatus : 54|2@1+ (1,0) [0|3] "" Vector__XXX
 SG_ Jystick1GripYAxisDetentPosStatus : 52|2@1+ (1,0) [0|3] "" Vector__XXX
 SG_ Jystick1ThetaAxisDetentPosStatus : 50|2@1+ (1,0) [0|3] "" Vector__XXX
 SG_ Joystick1ThetaAxisPos : 38|10@1+ (1,0) [0|102] "%" Vector__XXX
 SG_ Jystck1ThtAxsClckwsPstvPosStatus : 36|2@1+ (1,0) [0|3] "" Vector__XXX
 SG_ Jystck1ThetaAxisNeutralPosStatus : 32|2@1+ (1,0) [0|3] "" Vector__XXX
 SG_ Joystick1GripYAxisPos : 22|10@1+ (1,0) [0|102] "%" Vector__XXX
 SG_ Jystck1GrpYAxsLvrFrwrdPstvPsStts : 20|2@1+ (1,0) [0|3] "" Vector__XXX
 SG_ Jystck1GrpYAxsLvrBckNgtvPsStatus : 18|2@1+ (1,0) [0|3] "" Vector__XXX
 SG_ Jystck1GripYAxisNeutralPosStatus : 16|2@1+ (1,0) [0|3] "" Vector__XXX
 SG_ Joystick1GripXAxisPos : 6|10@1+ (1,0) [0|102] "%" Vector__XXX
 SG_ Jystck1GrpXAxsLvrRghtPstvPsSttus : 4|2@1+ (1,0) [0|3] "" Vector__XXX
 SG_ Jystck1GrpXAxsLvrLftNgtvPsStatus : 2|2@1+ (1,0) [0|3] "" Vector__XXX
 SG_ Jystck1GripXAxisNeutralPosStatus : 0|2@1+ (1,0) [0|3] "" Vector__XXX
 SG_ Jystck1ThtAxsCntrClckwsNgtvPsStt : 34|2@1+ (1,0) [0|3] "" Vector__XXX

BO_ 2633929470 EI: 8 Vector__XXX
 SG_ EngFuelRackPos : 24|8@1+ (0.4,0) [0|100] "%" Vector__XXX
 SG_ EngGasMassFlowRate1 : 32|16@1+ (0.05,0) [0|3212.75] "kg/h" Vector__XXX
 SG_ InstantaneousEstBrakePower : 48|16@1+ (0.5,0) [0|32127.5] "kW" Vector__XXX
 SG_ EngExhaustGasPress : 8|16@1+ (0.0078124659559567,-250) [-250|251.99] "kPa" Vector__XXX
 SG_ EngPrefilterOilPress : 0|8@1+ (4,0) [0|1000] "kPa" Vector__XXX

BO_ 2633937406 EH: 8 Vector__XXX
 SG_ TotalECURunTime : 32|32@1+ (0.05,0) [0|210554060.75] "hr" Vector__XXX
 SG_ TotalECUDistance : 0|32@1+ (0.12500000000594,0) [0|526385151.9] "km" Vector__XXX

BO_ 2364541694 EGF1: 8 Vector__XXX
 SG_ EngExhstGsRcrcltion2MassFlowRate : 32|16@1+ (0.05,0) [0|3212.75] "kg/h" Vector__XXX
 SG_ EngIntakeAirMassFlowRate : 16|16@1+ (0.05,0) [0|3212.75] "kg/h" Vector__XXX
 SG_ EngExhstGsRcrcltion1MassFlowRate : 0|16@1+ (0.05,0) [0|3212.75] "kg/h" Vector__XXX

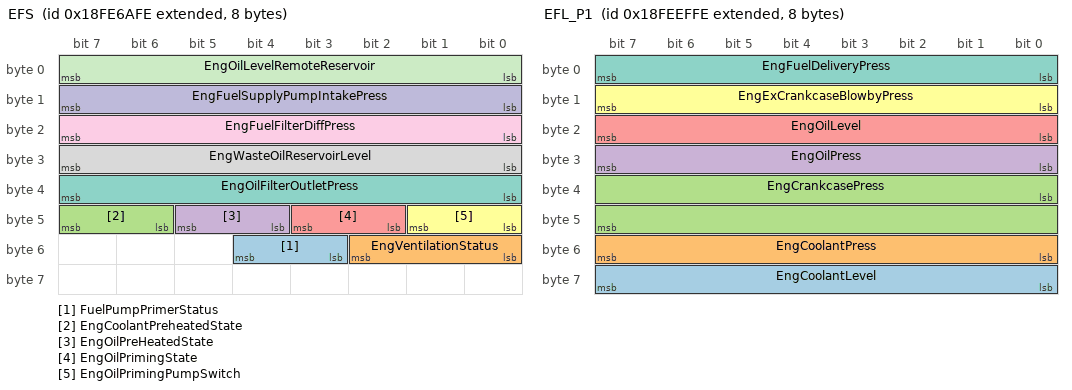
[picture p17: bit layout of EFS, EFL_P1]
BO_ 2566810366 EFS: 8 Vector__XXX
 SG_ FuelPumpPrimerStatus : 51|2@1+ (1,0) [0|3] "" Vector__XXX
 SG_ EngVentilationStatus : 48|3@1+ (1,0) [0|7] "" Vector__XXX
 SG_ EngCoolantPreheatedState : 46|2@1+ (1,0) [0|3] "" Vector__XXX
 SG_ EngOilPreHeatedState : 44|2@1+ (1,0) [0|3] "" Vector__XXX
 SG_ EngOilPrimingState : 42|2@1+ (1,0) [0|3] "" Vector__XXX
 SG_ EngOilPrimingPumpSwitch : 40|2@1+ (1,0) [0|3] "" Vector__XXX
 SG_ EngOilFilterOutletPress : 32|8@1+ (4,0) [0|1000] "kPa" Vector__XXX
 SG_ EngWasteOilReservoirLevel : 24|8@1+ (0.4,0) [0|100] "%" Vector__XXX
 SG_ EngFuelFilterDiffPress : 16|8@1+ (2,0) [0|500] "kPa" Vector__XXX
 SG_ EngFuelSupplyPumpIntakePress : 8|8@1+ (2,0) [0|500] "kPa" Vector__XXX
 SG_ EngOilLevelRemoteReservoir : 0|8@1+ (0.4,0) [0|100] "%" Vector__XXX

BO_ 2566767102 EFL_P3: 8 Vector__XXX
 SG_ EngExhstGsRcrclation1OutletPress : 40|8@1+ (2,0) [0|500] "kPa" Vector__XXX
 SG_ EngExhstVlvActtionSystemOilPress : 24|16@1+ (0.0039063107929344,0) [0|251] "MPa" Vector__XXX
 SG_ EngExhstGsRcrclation1IntakePress : 16|8@1+ (2,0) [0|500] "kPa" Vector__XXX
 SG_ EngIntkVlvActationSystemOilPress : 0|16@1+ (0.0039063107929344,0) [0|251] "MPa" Vector__XXX

BO_ 2566839294 EFL_P2: 8 Vector__XXX
 SG_ EngInjectorMeteringRail2Press : 48|16@1+ (0.0039063107929344,0) [0|251] "MPa" Vector__XXX
 SG_ EngInjectorTimingRail1Press : 32|16@1+ (0.0039063107929344,0) [0|251] "MPa" Vector__XXX
 SG_ EngInjectorMeteringRail1Press : 16|16@1+ (0.0039063107929344,0) [0|251] "MPa" Vector__XXX
 SG_ EngInjectionCtrlPress : 0|16@1+ (0.0039063107929344,0) [0|251] "MPa" Vector__XXX

BO_ 2566844414 EFL_P1: 8 Vector__XXX
 SG_ EngCoolantLevel : 56|8@1+ (0.4,0) [0|100] "%" Vector__XXX
 SG_ EngCoolantPress : 48|8@1+ (2,0) [0|500] "kPa" Vector__XXX
 SG_ EngCrankcasePress : 32|16@1+ (0.0078124659559567,-250) [-250|251.99] "kPa" Vector__XXX
 SG_ EngOilPress : 24|8@1+ (4,0) [0|1000] "kPa" Vector__XXX
 SG_ EngOilLevel : 16|8@1+ (0.4,0) [0|100] "%" Vector__XXX
 SG_ EngExCrankcaseBlowbyPress : 8|8@1+ (0.05,0) [0|12.5] "kPa" Vector__XXX
 SG_ EngFuelDeliveryPress : 0|8@1+ (4,0) [0|1000] "kPa" Vector__XXX

BO_ 2633929726 EES: 8 Vector__XXX
 SG_ SafetyWireStatus : 16|2@1+ (1,0) [0|3] "" Vector__XXX
 SG_ ElectricalLoad : 0|16@1+ (0.5,0) [0|32127.5] "kW" Vector__XXX

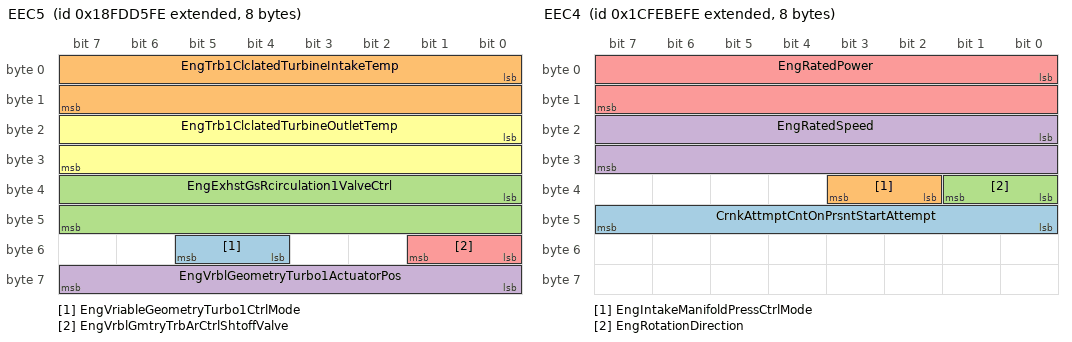
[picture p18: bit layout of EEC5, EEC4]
BO_ 2566772222 EEC5: 8 Vector__XXX
 SG_ EngVriableGeometryTurbo1CtrlMode : 52|2@1+ (1,0) [0|3] "" Vector__XXX
 SG_ EngTrb1ClclatedTurbineIntakeTemp : 0|16@1+ (1,-273) [-273|1734.96875] "deg C" Vector__XXX
 SG_ EngExhstGsRcirculation1ValveCtrl : 32|16@1+ (1,0) [0|160.6375] "%" Vector__XXX
 SG_ EngVrblGeometryTurbo1ActuatorPos : 56|8@1+ (0.4,0) [0|100] "%" Vector__XXX
 SG_ EngVrblGmtryTrbArCtrlShtoffValve : 48|2@1+ (1,0) [0|3] "" Vector__XXX
 SG_ EngTrb1ClclatedTurbineOutletTemp : 16|16@1+ (1,-273) [-273|1734.96875] "deg C" Vector__XXX

BO_ 2633940734 EEC4: 8 Vector__XXX
 SG_ CrnkAttmptCntOnPrsntStartAttempt : 40|8@1+ (1,0) [0|250] "" Vector__XXX
 SG_ EngIntakeManifoldPressCtrlMode : 34|2@1+ (1,0) [0|3] "" Vector__XXX
 SG_ EngRotationDirection : 32|2@1+ (1,0) [0|3] "" Vector__XXX
 SG_ EngRatedSpeed : 16|16@1+ (0.125,0) [0|8031.875] "rpm" Vector__XXX
 SG_ EngRatedPower : 0|16@1+ (0.5,0) [0|32127.5] "kW" Vector__XXX

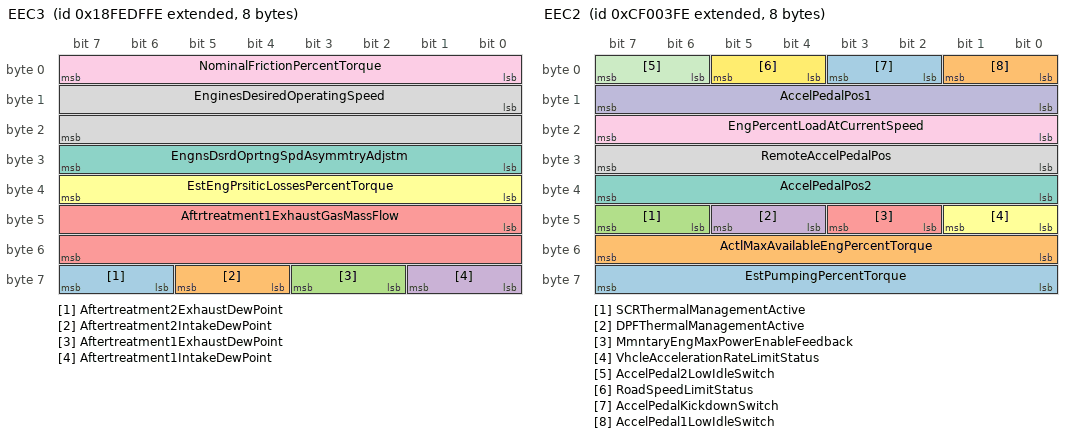
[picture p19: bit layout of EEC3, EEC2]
BO_ 2566840318 EEC3: 8 Vector__XXX
 SG_ Aftertreatment2ExhaustDewPoint : 62|2@1+ (1,0) [0|3] "" Vector__XXX
 SG_ Aftertreatment2IntakeDewPoint : 60|2@1+ (1,0) [0|3] "" Vector__XXX
 SG_ Aftertreatment1ExhaustDewPoint : 58|2@1+ (1,0) [0|3] "" Vector__XXX
 SG_ Aftertreatment1IntakeDewPoint : 56|2@1+ (1,0) [0|3] "" Vector__XXX
 SG_ Aftrtreatment1ExhaustGasMassFlow : 40|16@1+ (0.2,0) [0|12851] "kg/h per bit" Vector__XXX
 SG_ EstEngPrsiticLossesPercentTorque : 32|8@1+ (1,-125) [-125|125] "%" Vector__XXX
 SG_ EngnsDsrdOprtngSpdAsymmtryAdjstm : 24|8@1+ (1,0) [0|250] "" Vector__XXX
 SG_ EnginesDesiredOperatingSpeed : 8|16@1+ (1,0) [0|8031.875] "rpm" Vector__XXX
 SG_ NominalFrictionPercentTorque : 0|8@1+ (1,-125) [-125|125] "%" Vector__XXX

BO_ 2364539902 EEC2: 8 Vector__XXX
 SG_ EstPumpingPercentTorque : 56|8@1+ (1,-125) [-125|125] "%" Vector__XXX
 SG_ ActlMaxAvailableEngPercentTorque : 48|8@1+ (0.4,0) [0|100] "%" Vector__XXX
 SG_ SCRThermalManagementActive : 46|2@1+ (1,0) [0|3] "" Vector__XXX
 SG_ DPFThermalManagementActive : 44|2@1+ (1,0) [0|3] "" Vector__XXX
 SG_ MmntaryEngMaxPowerEnableFeedback : 42|2@1+ (1,0) [0|3] "" Vector__XXX
 SG_ VhcleAccelerationRateLimitStatus : 40|2@1+ (1,0) [0|3] "" Vector__XXX
 SG_ AccelPedalPos2 : 32|8@1+ (0.4,0) [0|100] "%" Vector__XXX
 SG_ RemoteAccelPedalPos : 24|8@1+ (0.4,0) [0|100] "%" Vector__XXX
 SG_ EngPercentLoadAtCurrentSpeed : 16|8@1+ (1,0) [0|250] "%" Vector__XXX
 SG_ AccelPedalPos1 : 8|8@1+ (0.4,0) [0|100] "%" Vector__XXX
 SG_ AccelPedal2LowIdleSwitch : 6|2@1+ (1,0) [0|3] "" Vector__XXX
 SG_ RoadSpeedLimitStatus : 4|2@1+ (1,0) [0|3] "" Vector__XXX
 SG_ AccelPedalKickdownSwitch : 2|2@1+ (1,0) [0|3] "" Vector__XXX
 SG_ AccelPedal1LowIdleSwitch : 0|2@1+ (1,0) [0|3] "" Vector__XXX

CM_ BO_ 2566768638 "Reports the states of off-highway engine control modes, as they apply to different modes of engine operation which may";
CM_ SG_ 2566768638 EngAltDroopAuxInputSelectState "In some off-highway applications it may be desirable to have multiple droop settings available across the range of engine";
CM_ SG_ 2566768638 EngAltDropRemoteAccelSelectState "In some off-highway applications it may be desirable to have multiple droop settings available across the range of engine";
CM_ SG_ 2566768638 EngAltDroopAccel2SelectState "In some off-highway applications it may be desirable to have multiple droop settings available across the range of engine";
CM_ SG_ 2566768638 EngAltDroopAccel1SelectState "In some off-highway applications it may be desirable to have multiple droop settings available across the range of engine";
CM_ SG_ 2566768638 EngAltRatingSelectState "In some off-highway applications it may be desirable to have multiple engine ratings available for selection by the";
CM_ SG_ 2566768638 EngAltLowIdleSelectState "In many applications, it is desirable that an alternate low idle speed setting be made available via switch input. The normal";
CM_ SG_ 2566768638 EngMultiUnitSyncState "This feature is widely used in Industry to operate multiple engines from a single command source. A master engine will";
CM_ SG_ 2566768638 EngAuxGovernorState "This is the Engine Auxiliary Governor feature. This feature is used to allow engine speed to be controlled by an auxiliary";
CM_ BO_ 2365443326 "The message containing the information about the position of the operator's external light control switch(s). Including";
CM_ SG_ 2365443326 OprtorsDesiredDelayedLampOffTime "A 16 bit parameter to be associated with Delayed Off position (1000 binary) of the Main Light Switch. This parameter";
CM_ SG_ 2365443326 OperatorsDesiredBacklight "A 8 bit parameter to indicate the level of back lighting the operator has selected for displays. This is to be differentiated";
CM_ SG_ 2365443326 HighLowBeamSwitch "A 2 bit parameter to indicate the selected position of the operator's high/low beam select switch.";
CM_ SG_ 2365443326 HazardLightSwitch "A 2 bit parameter to indicate the selected position of the operator's hazard light switch.";
CM_ SG_ 2365443326 TurnSignalSwitch "A 4 bit parameter to indicate the selected position of the operator's turn signal switch.";
CM_ SG_ 2365443326 MainLightSwitch "A 4 bit parameter to indicate the selected position of the operator's main light switch.";
CM_ SG_ 2365443326 WorkLightSwitch "A 4 bit parameter to indicate the selected position of the operator's work light switch. In Ag applications the work lights are";
CM_ BO_ 2566776318 "Reports the possible maximum vehicle speed limits, one through seven, and the applied maximum vehicle speed limit.";
CM_ SG_ 2566776318 AppliedVehicleSpeedLimit "The vehicle speed limit in effect.";
CM_ SG_ 2566776318 MaxVehicleSpeedLimit7 "The highest of the seven lowest vehicle speed limits";
CM_ SG_ 2566776318 MaxVehicleSpeedLimit6 "The highest of the six lowest vehicle speed limits";
CM_ SG_ 2566776318 MaxVehicleSpeedLimit5 "The highest of the five lowest vehicle speed limits";
CM_ SG_ 2566776318 MaxVehicleSpeedLimit4 "The highest of the four lowest vehicle speed limits";
CM_ SG_ 2566776318 MaxVehicleSpeedLimit3 "The highest of the three lowest vehicle speed limits";
CM_ SG_ 2566776318 MaxVehicleSpeedLimit2 "The highest of the two lowest vehicle speed limits";
CM_ SG_ 2566776318 MaxVehicleSpeedLimit1 "The lowest Maximum Vehicle Speed Limit. This value is the similar to SPN 74. However, SPN 74 was not specifically";
CM_ BO_ 2566802686 "The message contains parameters that control military specific lights.";
CM_ SG_ 2566802686 OprtrsBlackOutIntensitySelection "Operators Selection of lamp intensity in black out mode. This parameter provides the operators selected illumination";
CM_ SG_ 2566802686 BlackOutWorkLampSelect "Black Out Work Lamp Selection";
CM_ SG_ 2566802686 NightVisionIlluminatorSelect "Night Vision Illuminator Selection";
CM_ SG_ 2566802686 BlackOutBrake_StopLampSelect "Black Out Brake/Stop Lamp Selection";
CM_ SG_ 2566802686 ConvoyDrivingLampSelect "Black Out Convoy Driving Lamp Selection";
CM_ SG_ 2566802686 ConvoyLampSelect "Black Out Convoy Lamp Selection";
CM_ SG_ 2566802686 FrontBlackOutMarkerLampSelect "Front Black Out Marker Lamp Selection";
CM_ SG_ 2566802686 RearBlackOutMarkerSelect "Rear Black Out Marker Selection";
CM_ BO_ 2566774014 "This messages contains marine vessel control information for the engine";
CM_ SG_ 2566774014 SlowVesselModeStatus "The status of the Slow Vessel Mode. Slow Vessel Mode puts the engine in a lower-than-normal low idle speed during";
CM_ SG_ 2566774014 TrollingModeStatus "The status of the Trolling Mode. Trolling mode limits the top speed. Full range travel of the throttle level spans from low";
CM_ SG_ 2566774014 EngThrttlSynchrnzationModeStatus "The status of the Throttle Synchronization Mode. Throttle Synchronization Mode is used to indicate which throttle, if any,";
CM_ BO_ 2566823166 "Main Bearing Temperature 3";
CM_ SG_ 2566823166 EngMainBearing11Temp "Temperature of the main bearing which supports the crankshaft of the engine.";
CM_ SG_ 2566823166 EngMainBearing10Temp "Temperature of the main bearing which supports the crankshaft of the engine.";
CM_ SG_ 2566823166 EngMainBearing9Temp "Temperature of the main bearing which supports the crankshaft of the engine.";
CM_ BO_ 2566823422 "Main Bearing Temperature 2";
CM_ SG_ 2566823422 EngMainBearing8Temp "Temperature of the main bearing which supports the crankshaft of the engine.";
CM_ SG_ 2566823422 EngMainBearing7Temp "Temperature of the main bearing which supports the crankshaft of the engine.";
CM_ SG_ 2566823422 EngMainBearing6Temp "Temperature of the main bearing which supports the crankshaft of the engine.";
CM_ SG_ 2566823422 EngMainBearing5Temp "Temperature of the main bearing which supports the crankshaft of the engine.";
CM_ BO_ 2566823678 "Main Bearing Temperature 1";
CM_ SG_ 2566823678 EngMainBearing4Temp "Temperature of the main bearing which supports the crankshaft of the engine.";
CM_ SG_ 2566823678 EngMainBearing3Temp "Temperature of the main bearing which supports the crankshaft of the engine.";
CM_ SG_ 2566823678 EngMainBearing2Temp "Temperature of the main bearing which supports the crankshaft of the engine.";
CM_ SG_ 2566823678 EngMainBearing1Temp "Temperature of the main bearing which supports the crankshaft of the engine.";
CM_ SG_ 2432595710 DisplayDeadbands "Sets Display Deadbands mode.";
CM_ SG_ 2432595710 LEDPatternCtrl "Sets LED Pattern control mode on laser leveling systems.";
CM_ SG_ 2432595710 LEDDisplayDeadbandCtrl "This parameter informs the system what the selected Display deadband will be.";
CM_ SG_ 2432595710 LEDDisplayModeCtrl "This parameter informs the system what the selected Display mode will be.";
CM_ SG_ 2432595710 LEDDisplayData1 "Informs display devices how to display the current vertical position.";
CM_ SG_ 2365486590 LaserStrikeDataLatency "Time from laser strike to CAN message transmission. This parameter will be reported by survey receiver type devices";
CM_ SG_ 2365486590 LaserReceiverType "Identifies which type of Laser Receiver transmitted the message.";
CM_ SG_ 2365486590 LaserStrikeVerticalDeviation "The calculated distance from the laser strike position to the current land leveling system reference point.";
CM_ SG_ 2365486590 AbsLaserStrikePos "Laser Strike location on the survey type laser receiver.";
CM_ SG_ 2365485566 LaserTracerInformation "Provides the status of the laser tracer to the operator.";
CM_ SG_ 2365485566 LEDDisplayData2 "Informs display devices how to display the current position of the laser tracer.";
CM_ SG_ 2365485566 LaserTracerHorizontalDeviation "The calculated percent deviation between the target distance and the center of the laser tracer.";
CM_ SG_ 2365485566 LaserTracerVerticalDistance "The elevation of the laser tracer sensor in a laser leveling system.";
CM_ SG_ 2365485566 LaserTracerTargetDeviation "The calculated distance for the laser target to the current laser tracer reference point.";
CM_ BO_ 2633939454 "Trip Fuel Information (Liquid)";
CM_ SG_ 2633939454 TripCruiseFuelUsed "Total fuel consumed while the engine is in the cruise hold state since the last trip reset. If both cruise control and VSL";
CM_ SG_ 2633939454 TripVehicleIdleFuelUsed "Total fuel consumed while neither the PTO or remote PTO governor is in the hold state, the engine speed is greater than";
CM_ SG_ 2633939454 TripDriveFuelUsed "Total fuel consumed while the engine speed is greater than zero, vehicle speed is greater than or equal to 2 km/h, and";
CM_ SG_ 2633939454 TripPTOGovernorNonmovingFuelUsed "Total fuel consumed while either the PTO or remote PTO governors are in the hold state, the engine speed is greater";
CM_ SG_ 2633939454 TripPTOGovernorMovingFuelUsed "Total fuel consumed while either the PTO or remote PTO governors are in the hold state, the engine speed is greater";
CM_ SG_ 2633939454 TripDriveFuelEconomy "Trip drive fuel economy is equal to the distance traveled by vehicle in the drive state (engine speed greater than zero,";
CM_ SG_ 2365486334 BldeHeightSetPointHighResolution "High resolution for the laser guided blade set point. The high resolution required for more accurate control and 'accurate'";
CM_ SG_ 2365486334 ModifyLevelingSystemSetPoint "Used to control and coordinate the set point for the leveling system.";
CM_ BO_ 2364542462 "Group of operational parameters associated with the Land Leveling System, such as switch states. This is provided to";
CM_ SG_ 2364542462 StElvtnSensor2ReferenceElevation "Command from a display or other external device (i.e. remote switch) to the land leveling system controller instructing the";
CM_ SG_ 2364542462 StElvtnSensor1ReferenceElevation "Command from a display or other external device (i.e. remote switch) to the land leveling system controller instructing the";
CM_ SG_ 2364542462 SdshftDsrdBldeOffsetOperatorCtrl "This parameter indicates the side-shift blade control mode operator control state the user has set for the land leveling";
CM_ SG_ 2364542462 SdshiftBladeCtrlModeOperatorCtrl "This parameter indicates the side-shift offset operator control state the user has set for the land leveling system. When an";
CM_ SG_ 2364542462 RghtDsredBladeOffsetOperatorCtrl "This parameter indicates the right blade offset operator control state the user has set for the land leveling system. The";
CM_ SG_ 2364542462 LftDsiredBladeOffsetOperatorCtrl "This parameter indicates the left blade offset operator control state the user has set for the land leveling system. The left";
CM_ SG_ 2364542462 RightBladeCtrlModeOperatorCtrl "This parameter indicates the right blade control mode operator control state the user has set for the land leveling system.";
CM_ SG_ 2364542462 LeftBladeCtrlModeOperatorCtrl "This parameter indicates the left blade control mode operator control state the user has set for the land leveling system.";
CM_ SG_ 2364542462 BladeAutoModeCmd "Allows other controllers to command to the primary control system what they think is the appropriate auto control mode to";
CM_ SG_ 2364542462 DesiredGradeOffsetSwitch "This parameter indicates the grade offset switch state the user has set for the land leveling system. The desired grade";
CM_ SG_ 2364542462 BladeCtrlModeSwitch "This parameter indicates the blade control mode switch state the user has set for the land leveling system. The switch";
CM_ SG_ 2365486078 MastPos "Used to monitor the position of the sensor attached to the land leveling mast.";
CM_ SG_ 2633937918 FlexibleFuelPercentage "Measured signal that indicates the percentage of alcohol in the fuel currently being used. 0% means no alcohol in fuel,";
CM_ SG_ 2633937918 TripAverageFuelRate "Average fuel rate, equal to trip fuel divided by trip time while the engine speed is above zero, since the last trip reset. This";
CM_ SG_ 2633937918 TotalEngPTOGovernorFuelUsed "Total fuel used while the PTO or remote PTO governors are in the hold state and engine speed is above zero, over the";
CM_ SG_ 2566845182 EngAverageFuelEconomy "Average of instantaneous fuel economy for that segment of vehicle operation of interest.";
CM_ SG_ 2566845182 EngInstantaneousFuelEconomy "Current fuel economy at current vehicle velocity.";
CM_ SG_ 2566845182 EngFuelRate "Amount of fuel consumed by engine per unit of time.";
CM_ SG_ 2566845182 EngThrottleValve2Pos "The sensed position feedback of the valve, coming from a second electrical actuator for a second throttle plate, used to";
CM_ SG_ 2566845182 EngThrottleValve1Pos "The position of the valve used to regulate the supply of a fluid, usually air or fuel/air mixture, to an engine. 0% represents";
CM_ BO_ 2566842878 "Engine fuel consumption accumulators. See PGN 64777 for alternate resolution.";
CM_ SG_ 2566842878 EngTotalFuelUsed "Accumulated amount of fuel used during vehicle operation. See SPN 5054 for alternate resolution.";
CM_ SG_ 2566842878 EngTripFuel "Fuel consumed during all or part of a journey. See SPN 5053 for alternate resolution.";
CM_ BO_ 2633883646 "Front wheel drive ECU information";
CM_ SG_ 2633883646 FrontWheelDriveActuatorStatus "Feedback on the front wheel drive actuator.";
CM_ BO_ 2633880062 "Information which specifies the capabilities of the Fleet Management System (FMS) - standard interface device. This";
CM_ SG_ 2633880062 FMSstandardSWversionSupported "Information that identifies which issue level of the FMS-standard document the software included in the FMS gateway";
CM_ SG_ 2633880062 FMSstandardRequestsSupported "Status signal which indicates if the FMS Vehicle Interface (FMS Gateway) will respond to requests from the FMS device";
CM_ SG_ 2633880062 FMSstandardDiagnosticsSupported "Status signal which indicates if the FMS Vehicle Interface (FMS Gateway) supports the handling of diagnostic messages";
CM_ SG_ 2566806526 LnDpartureIndicationEnableStatus "Indicates whether lane departure indication is active.";
CM_ SG_ 2566806526 LaneTrackingStatusLeftSide "Indicates whether the left side is tracking lane.";
CM_ SG_ 2566806526 LaneTrackingStatusRightSide "Indicates whether right side is tracking lane.";
CM_ BO_ 2431649790 "Tr";
CM_ SG_ 2431649790 LaneDepartureImminentLeftSide "Indicates departure imminent on left side of lane.";
CM_ SG_ 2431649790 LaneDepartureImminentRightSide "Indicates departure imminent on right side of lane.";
CM_ SG_ 2431649790 LaneDepartureRight "Indicates that the middle of vehicle departs the lane on the right side. The parameter indicates that the vehicle is changing";
CM_ SG_ 2431649790 LaneDepartureLeft "Indicates that the middle of vehicle departs the lane on the left side. The parameter indicates that the vehicle is changing";
CM_ SG_ 2633929214 EngFuelLeakage2 "Status signal which indicates fuel leakage in the fuel rail of the engine. Location can be either before or after the fuel";
CM_ SG_ 2633929214 EngFuelLeakage1 "Status signal which indicates fuel leakage in the fuel rail of the engine. Location can be either before or after the fuel";
CM_ SG_ 2566831614 FanDriveBypassCmdStatus "Status of the Fan Drive Bypass Command as being commanded by the ECU. The fan drive bypass diverts pump";
CM_ SG_ 2566831614 HydFanMotorPress "The hydraulic pressure used to drive the fan system, sensed before the hydraulic fan motor.";
CM_ SG_ 2566831614 FanSpeed "The speed of the fan associated with engine coolant system.";
CM_ SG_ 2566831614 FanDriveState "This parameter is used to indicate the current state or mode of operation by the fan drive.";
CM_ SG_ 2566831614 EstPercentFanSpeed "Estimated fan speed as a ratio of the fan drive (current speed) to the fully engaged fan drive (maximum fan speed). A two";
CM_ BO_ 2566820094 "NOTE -The torque history PGN is variable in length and may contain up to 125 torque history records. Each torque";
CM_ SG_ 2566820094 EngTorqueLimit6AxleInput "Limit applied to the engine output torque based on the maximum allowable axle input torque. Axle input torque is";
CM_ SG_ 2566820094 EngTorqueLimit5Switch "Limit applied to the engine output torque based on activation of an ECU switch input.";
CM_ SG_ 2566820094 EngTorqueLimit4Trans "Limit applied to the engine output torque during vehicle operation in transmission gear ratios numerically less than or";
CM_ SG_ 2566820094 EngTorqueLimit3Trans "Limit applied to the engine output torque during vehicle operation in transmission gear ratios numerically less than or";
CM_ SG_ 2566820094 TransGearRatio3 "Gear ratio value stored in the ECU that is used to define a range of transmission gears for which a limit is applied to the";
CM_ SG_ 2566820094 EngTorqueLimit2Trans "Limit applied to the engine output torque during vehicle operation in transmission gear ratios numerically less than or";
CM_ SG_ 2566820094 TransGearRatio2 "Gear ratio value stored in the ECU that is used to define a range of transmission gears for which a limit is applied to the";
CM_ SG_ 2566820094 EngTorqueLimit1Trans "Limit applied to the engine output torque during vehicle operation in transmission gear ratios numerically greater than";
CM_ SG_ 2566820094 TransGearRatio1 "Gear ratio value stored in the ECU that is used to define a range of transmission gears for which a limit is applied to the";
CM_ SG_ 2566820094 EngTorqueLimitFeature "Torque limit rating described in the current record.";
CM_ SG_ 2566820094 TorqueLimitingFeatureStatus "Status of an ECU feature which limits the torque output of the engine.";
CM_ SG_ 2566820094 CalibRecordDurationTime "Duration in hours for which the engine operated in the conditions captured in the current record.";
CM_ SG_ 2566820094 CalibRecordStartYear "Calendar year timestamp when an ECU record was established.";
CM_ SG_ 2566820094 CalibRecordStartDay "Calendar day timestamp when an ECU record was established.";
CM_ SG_ 2566820094 CalibRecordStartMonth "Calendar month timestamp when an ECU record was established.";
CM_ SG_ 2566820094 EngPeakTorque2 "Maximum torque output of the current ECU calibration when the engine operates on torque curve 2. For calibrations that";
CM_ SG_ 2566820094 EngPeakTorque1 "Maximum torque output of the current ECU calibration when the engine operates on torque curve 1. For calibrations that";
CM_ SG_ 2566820094 EngPower "Advertised engine power capability. Advertised power is what a customer will find on a sales sheet for an engine with a";
CM_ SG_ 2566820094 NumberOfEngTorqueHistoryRecords "Number of torque history records contained in the engine torque history PGN. A value of 0 is broadcast if no torque";
CM_ BO_ 2364542206 "Electronic Transmission Controller #8";
CM_ SG_ 2364542206 TransClutch_ConverterInputSpeed "Rotational velocity of the input to a transmission's master clutch or torque converter. In most cases the rotational velocity";
CM_ SG_ 2364542206 TransTorqueConverterRatio "Ratio of the transmissions torque converter output torque to torque converter input torque at current speed.";
CM_ BO_ 2566802174 "Electronic Transmission Controller 7";
CM_ SG_ 2566802174 TrnsRverseGearShiftInhibitStatus "Reflects the status of transmission reverse inhibit activity in response to requests via SPN 4242 - Transmission Reverse";
CM_ SG_ 2566802174 TrnsCrrentRangeDisplayBlankState "State signal indicating a transmission request for the display of the Transmission Current Range parameter (SPN 163) to";
CM_ SG_ 2566802174 TransWarningIndicator "Signal from transmission indicating that some aspect of its operation is not functioning correctly, and as a result,";
CM_ SG_ 2566802174 TransMode8Indicator "Indicates whether transmission mode 8 is enabled. Modes are manufacturer specific and are not necessarily mutually";
CM_ SG_ 2566802174 TransMode7Indicator "Indicates whether transmission mode 7 is enabled. Modes are manufacturer specific and are not necessarily mutually";
CM_ SG_ 2566802174 TransMode6Indicator "Indicates whether transmission mode 6 is enabled. Modes are manufacturer specific and are not necessarily mutually";
CM_ SG_ 2566802174 TransMode5Indicator "Indicates whether transmission mode 5 is enabled. Modes are manufacturer specific and are not necessarily mutually";
CM_ SG_ 2566802174 TransRequestedGearFeedback "Feedback of the SPN 525 Transmission Requested Gear input as received from the shift selector, ABS or engine via";
CM_ SG_ 2566802174 TransMode1Indicator "This state signal is the transmission’s indication that it is operating under transmission mode 1 (SPN 1852) as";
CM_ SG_ 2566802174 TransMode2Indicator "This state signal is the transmission’s indication that it is operating under transmission mode 2 (SPN 1853) as";
CM_ SG_ 2566802174 TransMode3Indicator "This state signal is the transmission’s indication that it is operating under transmission mode 3 (SPN 1854) as";
CM_ SG_ 2566802174 TransMode4Indicator "This state signal is the transmission’s indication that it is operating under transmission mode 4 (SPN 1855) as";
CM_ SG_ 2566802174 TransShiftInhibitIndicator "State signal indicating a transmission request for the Shift Inhibit Indicator to be active or inactive. The shift inhibit";
CM_ SG_ 2566802174 TransEngCrankEnable "State signal from the transmission indicating if the transmission’s status is such that engine cranking is allowed (i.e. at a";
CM_ SG_ 2566802174 ActiveShiftConsoleIndicator "Signal from transmission control unit indicating which shift console (primary or secondary) it currently considers as the";
CM_ SG_ 2566802174 TransReadyForBrakeRelease "This parameter indicates that enough torque / motive force is available at the transmission output shaft to release all the";
CM_ SG_ 2566802174 TrnsRqstedRangeDisplayFlashState "State signal indicating a transmission request for the display of the Transmission Requested Range parameter (SPN 162)";
CM_ SG_ 2566802174 TrnsRqstedRangeDisplayBlankState "State signal indicating a transmission request for the display of the Transmission Requested Range parameter (SPN162)";
CM_ SG_ 2566802174 TransServiceIndicator "Signal from transmission indicating that some aspect of the gearbox requires servicing, such as the oil, filter, clutch(es) or";
CM_ SG_ 2633935870 ClutchLifeRemaining "Signal which indicates the actual clutch life remaining in percent. One hundred percent means the clutch is brand new";
CM_ SG_ 2633935870 LowestPossibleGear "The transmission calculates this gear continuously. Together with the highest possible gear (see SPN 1115), it enables a";
CM_ SG_ 2633935870 HighestPossibleGear "The transmission calculates this gear continuously. Together with the lowest possible gear (see SPN 1114), it enables a";
CM_ SG_ 2633935870 RecommendedGear "The transmission calculates this gear continuously. In dangerous situations this gear may be selected to gain back";
CM_ BO_ 2633942014 "Electronic Transmission Controller 5";
CM_ SG_ 2633942014 TransForwardDirectionSwitch "Identifies the status of the switch that indicates forward direction.";
CM_ SG_ 2633942014 TransNeutralSwitch "Identifies the status of the switch that indicates neutral.";
CM_ SG_ 2633942014 TransReverseDirectionSwitch "Identifies the status of the switch that indicates reverse direction.";
CM_ SG_ 2633942014 TransLowRangeSenseSwitch "Identifies the status of the switch that represents low range.";
CM_ SG_ 2633942014 TransHighRangeSenseSwitch "Identifies the status of the switch that represents high range.";
CM_ SG_ 2633942526 TransSynchronizerBrakeValue "The current modulated value for the air supply to the synchronizer brake.";
CM_ SG_ 2633942526 TransSynchronizerClutchValue "The current modulated value for the air supply to the synchronizer clutch.";
CM_ SG_ 2633943038 TransInertiaBrakeActuator "Identifies the status of the actuator that controls the inertia brake.";
CM_ SG_ 2633943038 TransDefuelActuator "Identifies the status of the actuator that controls the engine defuel mechanism.";
CM_ SG_ 2633943038 TransLockupClutchActuator "Identifies the status of the actuator that controls the lockup clutch.";
CM_ SG_ 2633943038 TransClutchActuator "Identifies the status of the actuator that controls the clutch.";
CM_ SG_ 2633943038 TransSplitterIndirectActuator "Identifies the status of the splitter indirect actuator in the auxiliary unit.";
CM_ SG_ 2633943038 TransSplitterDirectActuator "Identifies the status of the splitter direct actuator in the auxiliary unit.";
CM_ SG_ 2633943038 TransRangeLowActuator "Identifies the status of the range low actuator in the auxiliary unit.";
CM_ SG_ 2633943038 TransRangeHighActuator "Identifies the status of the range high actuator in the auxiliary unit.";
CM_ SG_ 2633943038 TransShiftFingerGearActuator2 "Identifies the status of the actuator that moves the shift finger identified as gear actuator #2.";
CM_ SG_ 2633943038 TransShiftFingerRailActuator2 "Identifies the status of the actuator that moves the shift finger identified as rail actuator #2.";
CM_ SG_ 2633943038 TransShiftFingerGearActuator1 "Identifies the status of the actuator that moves the shift finger identified as gear actuator #1.";
CM_ SG_ 2633943038 TransShiftFingerRailActuator1 "Identifies the status of the actuator that moves the shift finger identified as rail actuator #1.";
CM_ SG_ 2633943038 TrnsShftFngerCenterRailIndicator "Identifies the status of the shift finger in the center rail position.";
CM_ SG_ 2633943038 TrnsShftFngerEngagementIndicator "Identifies the status of the shift finger in the engagement position.";
CM_ SG_ 2633943038 TransShiftFingerNeutralIndicator "Indicates the status of the shift finger in the neutral position.";
CM_ SG_ 2633943038 TransShiftFingerRailPos "The current position of the shift finger in the rail direction.";
CM_ SG_ 2633943038 TransShiftFingerGearPos "The current position of the shift finger in the gear direction.";
CM_ SG_ 2565867006 TransCurrentRange "Range currently being commanded by the transmission control system. Characters may include P, Rx, Rx-1...R2, R1, R,";
CM_ SG_ 2565867006 TransRequestedRange "Range selected by the operator. Characters may include P, Rx, Rx-1...R2, R1, R, Nx, Nx-1...N2, N1, N, D, D1, D2..., Dx,";
CM_ SG_ 2565867006 TransCurrentGear "The gear currently engaged in the transmission or the last gear engaged while the transmission is in the process of";
CM_ SG_ 2565867006 TransActualGearRatio "Actual ratio of input shaft speed to output shaft speed.";
CM_ SG_ 2565867006 TransSelectedGear "The gear that the transmission will attempt to achieve during the current shift if a shift is in progress, or the next shift if one";
CM_ SG_ 2364539646 SrcAddrssOfCntrllngDvcFrTrnsCtrl "The source address of the SAE J1939 device currently controlling the transmission. Its value may be the source address";
CM_ SG_ 2364539646 TransInputShaftSpeed "Rotational velocity of the primary shaft transferring power into the transmission. When a torque converter is present, it is";
CM_ SG_ 2364539646 MomentaryEngMaxPowerEnable "Momentarily Requesting highest torque map from the engine control";
CM_ SG_ 2364539646 ProgressiveShiftDisable "Command signal used to indicate that progressive shifting by the engine should be disallowed.";
CM_ SG_ 2364539646 EngMomentaryOverspeedEnable "Command signal used to indicate that the engine speed may be boosted up to the maximum engine overspeed value to";
CM_ SG_ 2364539646 PercentClutchSlip "Parameter which represents the ratio of input shaft speed to current engine speed (in percent).";
CM_ SG_ 2364539646 TransOutputShaftSpeed "Calculated speed of the transmission output shaft.";
CM_ SG_ 2364539646 TrnsTrqCnvrtrLckpTrnstnInProcess "State signal indicating whether or not the transmission torque converter lock up clutch is transitioning between being";
CM_ SG_ 2364539646 TransShiftInProcess "Indicates that the transmission is in process of shifting from the current gear to the selected gear. This state is generally";
CM_ SG_ 2364539646 TrnsTorqueConverterLockupEngaged "State signal which indicates whether the torque converter lockup is engaged.";
CM_ SG_ 2364539646 TransDrivelineEngaged "Driveline engaged indicates the transmission controlled portion of the driveline is engaged sufficiently to allow a transfer";
CM_ BO_ 2566810110 "This parameter group is used to transmit high resolution engine temperatures for control purposes.";
CM_ SG_ 2566810110 EngChargeAirCooler1OutletTemp "Temperature of combustion air after it exits from the Charge Air Cooler 1 but before any mixing of recirculated exhaust";
CM_ SG_ 2566810110 EngIntkVlvActuationSystemOilTemp "The temperature of the oil in the hydraulic system that powers the intake valve actuation system.";
CM_ SG_ 2566810110 EngIntakeManifold1AirTemp "Temperature of pre-combustion air found in intake manifold of engine air supply system. The higher resolution is required";
CM_ SG_ 2566810110 EngCoolantTemp "Temperature of liquid found in engine cooling system. The higher resolution is required for control purposes.";
CM_ BO_ 2566825214 "Engine Temperature 2";
CM_ SG_ 2566825214 EngExhstGsRcirculation1DiffPress "Differential pressure across the Exhaust Gas Recirculation (EGR) system";
CM_ SG_ 2566825214 EngExhaustGasRecirculation1Temp "Temperature of Recirculated Exhaust Gas. This should not be used for Exhaust Gas Recirculation Mixer Intake";
CM_ SG_ 2566825214 EngECUTemp "Temperature of the engine electronic control unit.";
CM_ SG_ 2566825214 EngOilTemp2 "Temperature of the engine lubricant.";
CM_ BO_ 2566844158 "Engine Temperature 1";
CM_ SG_ 2566844158 EngFuelTemp1 "Temperature of fuel (or gas) passing through the first fuel control system. See SPN 3468 for the second control system";
CM_ SG_ 2566844158 EngIntercoolerThermostatOpening "The current position of the thermostat used to regulate the temperature of the engine intercooler. A value of 0%";
CM_ SG_ 2566844158 EngIntercoolerTemp "Temperature of liquid found in the intercooler located after the turbocharger.";
CM_ SG_ 2566844158 EngTurboOilTemp "Temperature of the turbocharger lubricant.";
CM_ SG_ 2566844158 EngOilTemp1 "Temperature of the engine lubricant.";
CM_ SG_ 2566844158 EngCoolantTemp "Temperature of liquid found in engine cooling system.";
CM_ SG_ 2566785022 EngExhaustGasTempLeftManifold "Temperature of combustion byproducts within the left engine exhaust manifold. Single manifold engines should use";
CM_ SG_ 2566785022 EngExhaustGasTempRightManifold "Temperature of combustion byproducts within the right engine exhaust manifold. Single manifold engines should use";
CM_ BO_ 2565868542 "PGN which indicates the actual angle and the status of a steerable axle";
CM_ SG_ 2565868542 TypeOfSteerTrans "Type of Steering Transmission (Ref. ECE Regulation 79 paragraph 2.6)";
CM_ SG_ 2565868542 TypeOfSteerForces "Type of Steering Forces (Ref. ECE Regulation 79 paragraph 2.5)";
CM_ SG_ 2565868542 SteerType "Indicates the different types of steering systems (ref. ECE Regulation 79 paragraph 2.5)";
CM_ SG_ 2565868542 SteerableLiftAxleLoweringInhibit "A signal which indicates if lowering of lifted axle is allowed or inhibited.";
CM_ SG_ 2565868542 StatusOfSteerAxle "A signal which indicates different states of the steering axle";
CM_ SG_ 2565868542 AxleLocation "To identify to which of several similar devices (such as tires or fuel tanks) the information applies.";
CM_ SG_ 2565868542 ActualInnerWheelSteerAngle "Signal which indicates the actual inner wheel steering angle. See Figure SPN2927_A for explanation of positive and";
CM_ BO_ 2633941758 "Electronic Retarder Controller 2";
CM_ SG_ 2633941758 TransOutputRetarder "Identifies the status of the transmission output retarder.";
CM_ BO_ 2565865726 "NOTE- This message will be transmitted by several types of retarding devices such as engine compression release";
CM_ SG_ 2565865726 ActlMxAvlblRetarderPercentTorque "This is the maximum amount of torque that the retarder can immediately deliver. It is the same as the maximum torque";
CM_ SG_ 2565865726 RetarderSelectionNonengine "The “Retarder Selection, non-engine” is the position of the driver’s selector for retarders that are not part of the engine";
CM_ SG_ 2565865726 DrvrsDemandRetarderPercentTorque "The Drivers demand retarder – percent torque is the maximum torque selected by the driver when one or more modes";
CM_ SG_ 2565865726 SrcAddrssOfCntrllngDvcFrRtrdrCtr "The source address of the SAE J1939 device currently controlling the retarder. It is used to expand the torque mode";
CM_ SG_ 2565865726 RetarderRoadSpeedExceededStatus "Retarder Road Speed Exceeded Status:";
CM_ SG_ 2565865726 RetarderRoadSpeedLimitSwitch "Retarder road speed limit switch states:";
CM_ SG_ 2565865726 RetarderRequestingBrakeLight "Indicates that whether the retarder is requesting that the brake lights are illuminated.";
CM_ SG_ 2565865726 EngCoolantLoadIncrease "Status of an event, external to the engine, that may increase the nominal temperature of the engine coolant liquid.";
CM_ SG_ 2565865726 IntendedRetarderPercentTorque "Braking torque of retarder that the retarder is currently trying to achieve. This value takes into account all static";
CM_ SG_ 2565865726 ActualRetarderPercentTorque "Actual braking torque of the retarder as a percent of retarder configuration reference torque SPN 556.";
CM_ SG_ 2565865726 RetarderEnableShiftAssistSwitch "Switch signal which indicates whether the operator wishes the retarder to be enabled for transmission shift assist. The";
CM_ SG_ 2565865726 RetarderEnableBrakeAssistSwitch "Switch signal which indicates whether the operator wishes the retarder to be enabled for vehicle braking assist. The";
CM_ SG_ 2565865726 RetarderTorqueMode "State signal which indicates which retarder torque mode is currently generating, limiting, or controlling the torque. Note";
CM_ BO_ 2633932798 "Exhaust Port Temperature 5";
CM_ SG_ 2633932798 EngExhaustGasPort20Temp "Temperature at the cylinder exhaust port of the engine.";
CM_ SG_ 2633932798 EngExhaustGasPort19Temp "Temperature at the cylinder exhaust port of the engine.";
CM_ SG_ 2633932798 EngExhaustGasPort18Temp "Temperature at the cylinder exhaust port of the engine.";
CM_ SG_ 2633932798 EngExhaustGasPort17Temp "Temperature at the cylinder exhaust port of the engine.";
CM_ BO_ 2566824190 "Exhaust Port Temperature 4";
CM_ SG_ 2566824190 EngExhaustGasPort16Temp "Temperature at the cylinder exhaust port of the engine.";
CM_ SG_ 2566824190 EngExhaustGasPort15Temp "Temperature at the cylinder exhaust port of the engine.";
CM_ SG_ 2566824190 EngExhaustGasPort14Temp "Temperature at the cylinder exhaust port of the engine.";
CM_ SG_ 2566824190 EngExhaustGasPort13Temp "Temperature at the cylinder exhaust port of the engine.";
CM_ BO_ 2633933310 "Exhaust Port Temperature 3";
CM_ SG_ 2633933310 EngExhaustGasPort12Temp "Temperature at the cylinder exhaust port of the engine.";
CM_ SG_ 2633933310 EngExhaustGasPort11Temp "Temperature at the cylinder exhaust port of the engine.";
CM_ SG_ 2633933310 EngExhaustGasPort10Temp "Temperature at the cylinder exhaust port of the engine.";
CM_ SG_ 2633933310 EngExhaustGasPort9Temp "Temperature at the cylinder exhaust port of the engine.";
CM_ BO_ 2633933566 "Exhaust Port Temperature 2";
CM_ SG_ 2633933566 EngExhaustGasPort8Temp "Temperature at the cylinder exhaust port of the engine.";
CM_ SG_ 2633933566 EngExhaustGasPort7Temp "Temperature at the cylinder exhaust port of the engine.";
CM_ SG_ 2633933566 EngExhaustGasPort6Temp "Temperature at the cylinder exhaust port of the engine.";
CM_ SG_ 2633933566 EngExhaustGasPort5Temp "Temperature at the cylinder exhaust port of the engine.";
CM_ BO_ 2633933822 "Exhaust Port Temperature 1";
CM_ SG_ 2633933822 EngExhaustGasPort4Temp "Temperature at the cylinder exhaust port of the engine.";
CM_ SG_ 2633933822 EngExhaustGasPort3Temp "Temperature at the cylinder exhaust port of the engine.";
CM_ SG_ 2633933822 EngExhaustGasPort2Temp "Temperature at the cylinder exhaust port of the engine.";
CM_ SG_ 2633933822 EngExhaustGasPort1Temp "Temperature at the cylinder exhaust port of the engine.";
CM_ BO_ 2566776062 "Equipment Performance Data";
CM_ SG_ 2566776062 PayloadPercentage "The current payload of the equipment, reported as a percentage of the equipment's rated payload limit.";
CM_ BO_ 2566771454 "Message used to transfer ECU performance parameters.";
CM_ SG_ 2566771454 DataMemoryUsage "The used storage capacity of the data buffer memory internal to an ECU, such as a data logger.";
CM_ SG_ 2566771454 KeepAliveBatteryConsumption "The capacity consumed from the direct battery connection since the key was last turned off. This value is maintained and";
CM_ BO_ 2566775806 "Parameters related to the operation and controls for equipment";
CM_ SG_ 2566775806 TravelVelocityCtrlPos "The position of the travel velocity control component reported as a percentage of the control's full displacement in each";
CM_ SG_ 2633935358 EngExhstGsOxygnSnsrClsdLpOprtion "Indicates whether the engine is using the Exhaust Gas Oxygen sensor to control the air/fuel ratio.";
CM_ SG_ 2633935358 EngExhstGsOxygnSnsrFlngCrrection "The amount of fueling change required by the system based on the measured Exhaust Oxygen value compared to the";
CM_ SG_ 2633935358 EngActualExhaustOxygen "The actual amount of oxygen in the exhaust represented as a percentage by volume with respect to the total volume of";
CM_ SG_ 2633935358 EngDesiredExhaustOxygen "The desired amount of oxygen in the exhaust represented as a percentage by volume with respect to the total volume of";
CM_ SG_ 2633935358 EngDesiredRatedExhaustOxygen "The desired amount of oxygen in the exhaust at rated conditions represented as a percentage by volume with respect to";
CM_ BO_ 2365447166 "Extended Joystick Message 3";
CM_ SG_ 2365447166 Jystick3GripXAxisDetentPosStatus "Reports when the current joystick grip position is in the detent position for that axis of travel.";
CM_ SG_ 2365447166 Jystick3GripYAxisDetentPosStatus "Reports when the current joystick grip position is in the detent position for that axis of travel.";
CM_ SG_ 2365447166 Jystick3ThetaAxisDetentPosStatus "Reports when the current joystick position is in the detent position for that axis of travel.";
CM_ SG_ 2365447166 Joystick3ThetaAxisPos "The position of the joystick in the relative motion of travel from the neutral position. Position value of 0 is Neutral and";
CM_ SG_ 2365447166 Jystck3ThtAxsClckwsPstvPosStatus "Reports when the current joystick position is on the positive travel side (forward, right, clockwise, up) relative to the";
CM_ SG_ 2365447166 Jystck3ThetaAxisNeutralPosStatus "Reports when the current joystick position is in the neutral position for that axis of travel. The neutral position";
CM_ SG_ 2365447166 Joystick3GripYAxisPos "The position of the joystick grip in the relative motion of travel from the neutral position. Position value of 0 is Neutral and";
CM_ SG_ 2365447166 Jystck3GrpYAxsLvrFrwrdPstvPsStts "Reports when the current joystick grip position is on the positive travel side (forward, right, clockwise, up) relative to the";
CM_ SG_ 2365447166 Jystck3GrpYAxsLvrBckNgtvPsStatus "Reports when the current joystick grip position is on the negative travel side (back, left, counterclockwise, down) relative";
CM_ SG_ 2365447166 Jystck3GripYAxisNeutralPosStatus "Reports when the current joystick grip position is in the neutral position for that axis of travel. The neutral position";
CM_ SG_ 2365447166 Joystick3GripXAxisPos "The position of the joystick grip in the relative motion of travel from the neutral position. Position value of 0 is Neutral and";
CM_ SG_ 2365447166 Jystck3GrpXAxsLvrRghtPstvPsSttus "Reports when the current joystick grip position is on the positive travel side (forward, right, clockwise, up) relative to the";
CM_ SG_ 2365447166 Jystck3GrpXAxsLvrLftNgtvPsStatus "Reports when the current joystick grip position is on the negative travel side (back, left, counterclockwise, down) relative";
CM_ SG_ 2365447166 Jystck3GripXAxisNeutralPosStatus "Reports when the current joystick grip position is in the neutral position for that axis of travel. The neutral position";
CM_ SG_ 2365447166 Jystck3ThtAxsCntrClckwsNgtvPsStt "Reports when the current joystick position is on the negative travel side (back, left, counterclockwise, down) relative to the";
CM_ BO_ 2365446654 "Extended Joystick Message 2";
CM_ SG_ 2365446654 Jystick2GripXAxisDetentPosStatus "Reports when the current joystick grip position is in the detent position for that axis of travel.";
CM_ SG_ 2365446654 Jystick2GripYAxisDetentPosStatus "Reports when the current joystick grip position is in the detent position for that axis of travel.";
CM_ SG_ 2365446654 Jystick2ThetaAxisDetentPosStatus "Reports when the current joystick position is in the detent position for that axis of travel.";
CM_ SG_ 2365446654 Joystick2ThetaAxisPos "The position of the joystick in the relative motion of travel from the neutral position. Position value of 0 is Neutral and";
CM_ SG_ 2365446654 Jystck2ThtAxsClckwsPstvPosStatus "Reports when the current joystick position is on the positive travel side (forward, right, clockwise, up) relative to the";
CM_ SG_ 2365446654 Jystck2ThetaAxisNeutralPosStatus "Reports when the current joystick position is in the neutral position for that axis of travel. The neutral position";
CM_ SG_ 2365446654 Joystick2GripYAxisPos "The position of the joystick grip in the relative motion of travel from the neutral position. Position value of 0 is Neutral and";
CM_ SG_ 2365446654 Jystck2GrpYAxsLvrFrwrdPstvPsStts "Reports when the current joystick grip position is on the positive travel side (forward, right, clockwise, up) relative to the";
CM_ SG_ 2365446654 Jystck2GrpYAxsLvrBckNgtvPsStatus "Reports when the current joystick grip position is on the negative travel side (back, left, counterclockwise, down) relative";
CM_ SG_ 2365446654 Jystck2GripYAxisNeutralPosStatus "Reports when the current joystick grip position is in the neutral position for that axis of travel. The neutral position";
CM_ SG_ 2365446654 Joystick2GripXAxisPos "The position of the joystick grip in the relative motion of travel from the neutral position. Position value of 0 is Neutral and";
CM_ SG_ 2365446654 Jystck2GrpXAxsLvrRghtPstvPsSttus "Reports when the current joystick grip position is on the positive travel side (forward, right, clockwise, up) relative to the";
CM_ SG_ 2365446654 Jystck2GrpXAxsLvrLftNgtvPsStatus "Reports when the current joystick grip position is on the negative travel side (back, left, counterclockwise, down) relative";
CM_ SG_ 2365446654 Jystck2GripXAxisNeutralPosStatus "Reports when the current joystick grip position is in the neutral position for that axis of travel. The neutral position";
CM_ SG_ 2365446654 Jystck2ThtAxsCntrClckwsNgtvPsStt "Reports when the current joystick position is on the negative travel side (back, left, counterclockwise, down) relative to the";
CM_ BO_ 2365446142 "Extended Joystick Message 1";
CM_ SG_ 2365446142 Jystick1GripXAxisDetentPosStatus "Reports when the current joystick grip position is in the detent position for that axis of travel.";
CM_ SG_ 2365446142 Jystick1GripYAxisDetentPosStatus "Reports when the current joystick grip position is in the detent position for that axis of travel.";
CM_ SG_ 2365446142 Jystick1ThetaAxisDetentPosStatus "Reports when the current joystick position is in the detent position for that axis of travel.";
CM_ SG_ 2365446142 Joystick1ThetaAxisPos "The position of the joystick in the relative motion of travel from the neutral position. Position value of 0 is Neutral and";
CM_ SG_ 2365446142 Jystck1ThtAxsClckwsPstvPosStatus "Reports when the current joystick position is on the positive travel side (forward, right, clockwise, up) relative to the";
CM_ SG_ 2365446142 Jystck1ThetaAxisNeutralPosStatus "Reports when the current joystick position is in the neutral position for that axis of travel. The neutral position";
CM_ SG_ 2365446142 Joystick1GripYAxisPos "The position of the joystick grip in the relative motion of travel from the neutral position. Position value of 0 is Neutral and";
CM_ SG_ 2365446142 Jystck1GrpYAxsLvrFrwrdPstvPsStts "Reports when the current joystick grip position is on the positive travel side (forward, right, clockwise, up) relative to the";
CM_ SG_ 2365446142 Jystck1GrpYAxsLvrBckNgtvPsStatus "Reports when the current joystick grip position is on the negative travel side (back, left, counterclockwise, down) relative";
CM_ SG_ 2365446142 Jystck1GripYAxisNeutralPosStatus "Reports when the current joystick grip position is in the neutral position for that axis of travel. The neutral position";
CM_ SG_ 2365446142 Joystick1GripXAxisPos "The position of the joystick grip in the relative motion of travel from the neutral position. Position value of 0 is Neutral and";
CM_ SG_ 2365446142 Jystck1GrpXAxsLvrRghtPstvPsSttus "Reports when the current joystick grip position is on the positive travel side (forward, right, clockwise, up) relative to the";
CM_ SG_ 2365446142 Jystck1GrpXAxsLvrLftNgtvPsStatus "Reports when the current joystick grip position is on the negative travel side (back, left, counterclockwise, down) relative";
CM_ SG_ 2365446142 Jystck1GripXAxisNeutralPosStatus "Reports when the current joystick grip position is in the neutral position for that axis of travel. The neutral position";
CM_ SG_ 2365446142 Jystck1ThtAxsCntrClckwsNgtvPsStt "Reports when the current joystick position is on the negative travel side (back, left, counterclockwise, down) relative to the";
CM_ SG_ 2633929470 EngFuelRackPos "Measured position of the engine fuel rack. A value of 0% rack represents no fueling and a value of 100% rack represents";
CM_ SG_ 2633929470 EngGasMassFlowRate1 "Gas mass flow rate delivered to an engine through its first fuel control system. See SPN 3467 for the second fuel control";
CM_ SG_ 2633929470 InstantaneousEstBrakePower "Estimate of the power developed by the engine.";
CM_ SG_ 2633929470 EngExhaustGasPress "Gage pressure of the exhaust gasses as measured at the turbine intake of the turbocharger.";
CM_ SG_ 2633929470 EngPrefilterOilPress "Gage pressure of the engine oil before the oil reaches the oil filter.";
CM_ SG_ 2633937406 TotalECURunTime "Total time accumulated over the life of the ECU, from ignition switch ON to ignition switch OFF. When the ECU is";
CM_ SG_ 2633937406 TotalECUDistance "Total distance accumulated over the life of the ECU. When the ECU is replaced this value shall be reset.";
CM_ BO_ 2364541694 "Flow rates of Air and mixed gasses into the engine cylinders.";
CM_ SG_ 2364541694 EngExhstGsRcrcltion2MassFlowRate "Flow rate of gas through the second EGR system. Flow rate of the exhaust gas being recirculated from the 2nd EGR";
CM_ SG_ 2364541694 EngIntakeAirMassFlowRate "Mass flow rate of fresh air entering the engine air intake, before any EGR mixer, if used. Flow rate of fresh air conducted";
CM_ SG_ 2364541694 EngExhstGsRcrcltion1MassFlowRate "Flow rate of gas through the EGR system. Flow rate of the exhaust gas being recirculated into the combustion air.";
CM_ SG_ 2566810366 FuelPumpPrimerStatus "Parameter used to transmit the actual status of the fuel priming system. The fuel priming system is a system that purges";
CM_ SG_ 2566810366 EngVentilationStatus "Engine ventilation control states.";
CM_ SG_ 2566810366 EngCoolantPreheatedState "Indicates whether the engine coolant is pre-heated sufficiently for starting purposes.";
CM_ SG_ 2566810366 EngOilPreHeatedState "Indicates whether the engine oil pre-heated sufficiently for starting purposes.";
CM_ SG_ 2566810366 EngOilPrimingState "Determination of whether or not the engine is (or has recently been) sufficiently lubricated for starting purposes.";
CM_ SG_ 2566810366 EngOilPrimingPumpSwitch "Switch input for activating the engine oil priming pump.";
CM_ SG_ 2566810366 EngOilFilterOutletPress "Oil pressure (gauge) measured just downstream of oil filter.Used in conjunction with SPN1208 (pre-filter oil pressure) to";
CM_ SG_ 2566810366 EngWasteOilReservoirLevel "Level of crankcase blowby emulsion collected by a container. Normalized to percent, 0% represents completely empty";
CM_ SG_ 2566810366 EngFuelFilterDiffPress "Differential pressure measured across the fuel filter located between the fuel tank and the supply pump. See Figures";
CM_ SG_ 2566810366 EngFuelSupplyPumpIntakePress "Absolute pressure of fuel at the fuel supply pump intake. See Figures SPN16_A & SPN16_B";
CM_ SG_ 2566810366 EngOilLevelRemoteReservoir "Ratio of current volume of engine oil in a remote reservoir to the maximum required volume. If a single switch (on/off) is";
CM_ BO_ 2566767102 "3rd PGN which identifies parameters that are either measuring various pressures within the engine or identifying engine";
CM_ SG_ 2566767102 EngExhstGsRcrclation1OutletPress "EGR outlet pressure is measured immediately after the EGR valve.";
CM_ SG_ 2566767102 EngExhstVlvActtionSystemOilPress "The absolute pressure of the oil in the hydraulic system that powers the engine exhaust valve actuation system";
CM_ SG_ 2566767102 EngExhstGsRcrclation1IntakePress "EGR intake gage pressure is measured after the EGR cooler and before the EGR valve.";
CM_ SG_ 2566767102 EngIntkVlvActationSystemOilPress "The gage pressure of the oil in the hydraulic system that powers the engine intake valve actuation system";
CM_ SG_ 2566839294 EngInjectorMeteringRail2Press "The gage pressure of fuel in the metering rail #2 as delivered from the supply pump to the injector metering intake. See";
CM_ SG_ 2566839294 EngInjectorTimingRail1Press "The gage pressure of fuel in the timing rail delivered from the supply pump to the injector timing intake.";
CM_ SG_ 2566839294 EngInjectorMeteringRail1Press "The gage pressure of fuel in the primary, or first, metering rail as delivered from the supply pump to the injector metering";
CM_ SG_ 2566839294 EngInjectionCtrlPress "The gage pressure of the engine oil in the hydraulic accumulator that powers an intensifier used for fuel injection.";
CM_ BO_ 2566844414 "Engine Fluid Level/Pressure 1";
CM_ SG_ 2566844414 EngCoolantLevel "Ratio of volume of liquid found in engine cooling system to total cooling system volume. Typical monitoring location is in";
CM_ SG_ 2566844414 EngCoolantPress "Gage pressure of liquid found in engine cooling system.";
CM_ SG_ 2566844414 EngCrankcasePress "Gage pressure inside engine crankcase.";
CM_ SG_ 2566844414 EngOilPress "Gage pressure of oil in engine lubrication system as provided by oil pump.";
CM_ SG_ 2566844414 EngOilLevel "Ratio of current volume of engine sump oil to maximum required volume.";
CM_ SG_ 2566844414 EngExCrankcaseBlowbyPress "Differential crankcase blow-by pressure as measured through a tube with a venturi.";
CM_ SG_ 2566844414 EngFuelDeliveryPress "Gage pressure of fuel in system as delivered from supply pump to the injection pump. See Figures SPN16_A &";
CM_ SG_ 2633929726 SafetyWireStatus "Status signal which indicates that the safety wire has been activated. When the safety wire is activated, the engine will";
CM_ SG_ 2633929726 ElectricalLoad "Electrical power delivered by the engine to the electrical system connected to the generator.";
CM_ BO_ 2566772222 "Electronic Engine Controller 5";
CM_ SG_ 2566772222 EngVriableGeometryTurbo1CtrlMode "Indicates if the variable geometry turbocharger control status is either open loop or closed loop.";
CM_ SG_ 2566772222 EngTrb1ClclatedTurbineIntakeTemp "Calculated value of turbine intake temperature based on engine operating conditions, such as intake manifold";
CM_ SG_ 2566772222 EngExhstGsRcirculation1ValveCtrl "Desired percentage of maximum Exhaust Gas Recirculation (EGR) valve opening. 0% means valve is closed. 100%";
CM_ SG_ 2566772222 EngVrblGeometryTurbo1ActuatorPos "Sensor that measures the position of the variable geometry turbocharger actuator. A position of 0% indicates the";
CM_ SG_ 2566772222 EngVrblGmtryTrbArCtrlShtoffValve "Isolates vehicle brake air from the Variable Geometry Turbocharger (VGT) system when engine is not running. This valve";
CM_ SG_ 2566772222 EngTrb1ClclatedTurbineOutletTemp "Calculated value of turbocharger compressor outlet air temperature. Temperature of air exiting the turbocharger";
CM_ SG_ 2633940734 CrnkAttmptCntOnPrsntStartAttempt "Reports the number of cranking cycles undergone during the present start attempt.";
CM_ SG_ 2633940734 EngIntakeManifoldPressCtrlMode "Indicates that the Boost Pressure Closed Loop Control status either open loop or closed loop.";
CM_ SG_ 2633940734 EngRotationDirection "Direction of engine rotation, as reported by the engine. Direction convention as viewed by an observer standing at the";
CM_ SG_ 2633940734 EngRatedSpeed "The maximum governed rotational velocity of the engine crankshaft under full load conditions. Note that the engine";
CM_ SG_ 2633940734 EngRatedPower "Net brake power that the engine will deliver continuously, specified for a given application at a rated speed.";
CM_ SG_ 2566840318 Aftertreatment2ExhaustDewPoint "Indicates that the temperature on the exhaust side of the aftertreatment has exceeded the dew point, as estimated by the";
CM_ SG_ 2566840318 Aftertreatment2IntakeDewPoint "Indicates that the temperature on the intake side of the aftertreatment system has exceeded the dew point, as estimated";
CM_ SG_ 2566840318 Aftertreatment1ExhaustDewPoint "Indicates that the temperature on the exhaust side of the aftertreatment has exceeded the dew point, as estimated by the";
CM_ SG_ 2566840318 Aftertreatment1IntakeDewPoint "Indicates that the temperature on the intake side of the aftertreatment system has exceeded the dew point, as estimated";
CM_ SG_ 2566840318 Aftrtreatment1ExhaustGasMassFlow "Measured/calculated exhaust gas mass upstream of the aftertreatment system in exhaust bank 1 and 2.";
CM_ SG_ 2566840318 EstEngPrsiticLossesPercentTorque "The calculated torque that indicates the estimated amount of torque loss due to engine parasitics, such as cooling fan, air";
CM_ SG_ 2566840318 EngnsDsrdOprtngSpdAsymmtryAdjstm "This byte is utilized in transmission gear selection routines and indicates the engine's preference of lower versus higher";
CM_ SG_ 2566840318 EnginesDesiredOperatingSpeed "An indication by the engine of the optimal operating speed of the engine for the current existing conditions. These";
CM_ SG_ 2566840318 NominalFrictionPercentTorque "The calculated torque that indicates the amount of torque required by the basic engine itself added by the loss torque of";
CM_ BO_ 2364539902 "Identifies electronic engine control related parameters.";
CM_ SG_ 2364539902 EstPumpingPercentTorque "The calculated torque that indicates the estimated amount of torque loss due to the engine air handling system. The value";
CM_ SG_ 2364539902 ActlMaxAvailableEngPercentTorque "This is the maximum amount of torque that the engine can immediately deliver as a percentage of the reference engine";
CM_ SG_ 2364539902 SCRThermalManagementActive "Indicates that the exhaust temperatures have been elevated for regeneration of the SCR aftertreatment system or in";
CM_ SG_ 2364539902 DPFThermalManagementActive "Indicates that the exhaust temperatures have been elevated for regeneration of the diesel particulate filter aftertreatment";
CM_ SG_ 2364539902 MmntaryEngMaxPowerEnableFeedback "Momentarily requesting Engine Maximum Power Enable - feature support feedback";
CM_ SG_ 2364539902 VhcleAccelerationRateLimitStatus "Status (active or not active) of the system used to limit maximum forward vehicle acceleration.";
CM_ SG_ 2364539902 AccelPedalPos2 "The ratio of actual position of the second analog engine speed/torque request input device (such as an accelerator pedal";
CM_ SG_ 2364539902 RemoteAccelPedalPos "The ratio of actual position of the remote analog engine speed/torque request input device (such as an accelerator pedal";
CM_ SG_ 2364539902 EngPercentLoadAtCurrentSpeed "The ratio of actual engine percent torque (indicated) to maximum indicated torque available at the current engine speed,";
CM_ SG_ 2364539902 AccelPedalPos1 "The ratio of actual position of the analog engine speed/torque request input device (such as an accelerator pedal or";
CM_ SG_ 2364539902 AccelPedal2LowIdleSwitch "Switch signal which indicates the state of the accelerator pedal 2 low idle switch. The low idle switch is defined in SAE";
CM_ SG_ 2364539902 RoadSpeedLimitStatus "Status (active or not active) of the system used to limit maximum vehicle velocity.";
CM_ SG_ 2364539902 AccelPedalKickdownSwitch "Switch signal which indicates whether the accelerator pedal kickdown switch is opened or closed. The kickdown switch is";
CM_ SG_ 2364539902 AccelPedal1LowIdleSwitch "Switch signal which indicates the state of the accelerator pedal 1 low idle switch. The low idle switch is defined in SAE";
BA_DEF_ SG_  "SigType" ENUM  "Default","Range","RangeSigned","ASCII","Discrete","Control","ReferencePGN","DTC","StringDelimiter","StringLength","StringLengthControl";
BA_DEF_ SG_  "GenSigStartValue" INT 0 10000;
BA_DEF_ SG_  "GenSigSendType" ENUM  "Cyclic","OnWrite","OnWriteWithRepetition","OnChange","OnChangeWithRepetition","IfActive","IfActiveWithRepetition","NoSigSendType";
BA_DEF_ SG_  "GenSigILSupport" ENUM  "No","Yes";
BA_DEF_ SG_  "GenSigEVName" STRING ;
BA_DEF_ SG_  "SPN" INT 0 524287;
BA_DEF_ SG_  "SAEDocument" STRING ;
BA_DEF_ BO_  "GenMsgStartDelayTime" INT 0 100000;
BA_DEF_ BO_  "GenMsgILSupport" ENUM  "No","Yes";
BA_DEF_ BO_  "GenMsgRequestable" INT 0 1;
BA_DEF_ BO_  "GenMsgSendType" ENUM  "cyclic","NotUsed","NotUsed","NotUsed","NotUsed","NotUsed","NotUsed","IfActive","noMsgSendType";
BA_DEF_ BO_  "VFrameFormat" ENUM  "StandardCAN","ExtendedCAN","reserved","J1939PG";
BA_DEF_ BO_  "SingleFrame" INT 0 1;
BA_DEF_ BO_  "GenMsgCycleTime" INT 0 3600000;
BA_DEF_ BO_  "SAE_Document" STRING ;
BA_DEF_ SG_  "SystemSignalLongSymbol" STRING ;
BA_DEF_DEF_  "SigType" "Default";
BA_DEF_DEF_  "GenSigStartValue" 0;
BA_DEF_DEF_  "GenSigSendType" "NoSigSendType";
BA_DEF_DEF_  "GenSigILSupport" "Yes";
BA_DEF_DEF_  "GenSigEVName" "Env@Nodename_@Signame";
BA_DEF_DEF_  "SPN" 0;
BA_DEF_DEF_  "SAEDocument" "";
BA_DEF_DEF_  "GenMsgStartDelayTime" 0;
BA_DEF_DEF_  "GenMsgILSupport" "Yes";
BA_DEF_DEF_  "GenMsgRequestable" 1;
BA_DEF_DEF_  "GenMsgSendType" "noMsgSendType";
BA_DEF_DEF_  "VFrameFormat" "J1939PG";
BA_DEF_DEF_  "SingleFrame" 1;
BA_DEF_DEF_  "GenMsgCycleTime" 0;
BA_DEF_DEF_  "SAE_Document" "";
BA_DEF_DEF_  "SystemSignalLongSymbol" "";
BA_ "GenMsgSendType" BO_ 2566768638 0;
BA_ "GenMsgCycleTime" BO_ 2566768638 5000;
BA_ "SAE_Document" BO_ 2566768638 "J1939-71";
BA_ "GenMsgSendType" BO_ 2365443326 0;
BA_ "GenMsgCycleTime" BO_ 2365443326 1000;
BA_ "SAE_Document" BO_ 2365443326 "J1939-71";
BA_ "GenMsgSendType" BO_ 2566776318 0;
BA_ "GenMsgCycleTime" BO_ 2566776318 1000;
BA_ "SAE_Document" BO_ 2566776318 "J1939-71";
BA_ "GenMsgSendType" BO_ 2566802686 0;
BA_ "GenMsgCycleTime" BO_ 2566802686 100;
BA_ "SAE_Document" BO_ 2566802686 "J1939-71";
BA_ "GenMsgSendType" BO_ 2566774014 0;
BA_ "GenMsgCycleTime" BO_ 2566774014 1000;
BA_ "SAE_Document" BO_ 2566774014 "J1939-71";
BA_ "GenMsgSendType" BO_ 2566823166 0;
BA_ "GenMsgCycleTime" BO_ 2566823166 1000;
BA_ "SAE_Document" BO_ 2566823166 "J1939-71";
BA_ "GenMsgSendType" BO_ 2566823422 0;
BA_ "GenMsgCycleTime" BO_ 2566823422 1000;
BA_ "SAE_Document" BO_ 2566823422 "J1939-71";
BA_ "GenMsgSendType" BO_ 2566823678 0;
BA_ "GenMsgCycleTime" BO_ 2566823678 1000;
BA_ "SAE_Document" BO_ 2566823678 "J1939-71";
BA_ "GenMsgSendType" BO_ 2432595710 0;
BA_ "GenMsgCycleTime" BO_ 2432595710 100;
BA_ "SAE_Document" BO_ 2432595710 "J1939-71";
BA_ "GenMsgSendType" BO_ 2365486590 0;
BA_ "GenMsgCycleTime" BO_ 2365486590 50;
BA_ "SAE_Document" BO_ 2365486590 "J1939-71";
BA_ "GenMsgSendType" BO_ 2365485566 0;
BA_ "GenMsgCycleTime" BO_ 2365485566 50;
BA_ "SAE_Document" BO_ 2365485566 "J1939-71";
BA_ "SAE_Document" BO_ 2633939454 "J1939-71";
BA_ "GenMsgSendType" BO_ 2365486334 0;
BA_ "GenMsgCycleTime" BO_ 2365486334 50;
BA_ "SAE_Document" BO_ 2365486334 "J1939-71";
BA_ "GenMsgSendType" BO_ 2364542462 0;
BA_ "GenMsgCycleTime" BO_ 2364542462 100;
BA_ "SAE_Document" BO_ 2364542462 "J1939-71";
BA_ "GenMsgSendType" BO_ 2365486078 0;
BA_ "GenMsgCycleTime" BO_ 2365486078 50;
BA_ "SAE_Document" BO_ 2365486078 "J1939-71";
BA_ "SAE_Document" BO_ 2633937918 "J1939-71";
BA_ "GenMsgSendType" BO_ 2566845182 0;
BA_ "GenMsgCycleTime" BO_ 2566845182 100;
BA_ "SAE_Document" BO_ 2566845182 "J1939-71";
BA_ "SAE_Document" BO_ 2566842878 "J1939-71";
BA_ "GenMsgSendType" BO_ 2633883646 0;
BA_ "GenMsgCycleTime" BO_ 2633883646 5000;
BA_ "SAE_Document" BO_ 2633883646 "J1939-71";
BA_ "GenMsgSendType" BO_ 2633880062 0;
BA_ "GenMsgCycleTime" BO_ 2633880062 10000;
BA_ "SAE_Document" BO_ 2633880062 "J1939-71";
BA_ "GenMsgSendType" BO_ 2566806526 0;
BA_ "GenMsgCycleTime" BO_ 2566806526 100;
BA_ "SAE_Document" BO_ 2566806526 "J1939-71";
BA_ "GenMsgSendType" BO_ 2431649790 2;
BA_ "GenMsgCycleTime" BO_ 2431649790 50;
BA_ "SAE_Document" BO_ 2431649790 "J1939-71";
BA_ "GenMsgSendType" BO_ 2633929214 0;
BA_ "GenMsgCycleTime" BO_ 2633929214 1000;
BA_ "SAE_Document" BO_ 2633929214 "J1939-71";
BA_ "GenMsgSendType" BO_ 2566831614 0;
BA_ "GenMsgCycleTime" BO_ 2566831614 1000;
BA_ "SAE_Document" BO_ 2566831614 "J1939-71";
BA_ "SAE_Document" BO_ 2566820094 "J1939-71";
BA_ "GenMsgSendType" BO_ 2364542206 0;
BA_ "GenMsgCycleTime" BO_ 2364542206 20;
BA_ "SAE_Document" BO_ 2364542206 "J1939-71";
BA_ "GenMsgSendType" BO_ 2566802174 0;
BA_ "GenMsgCycleTime" BO_ 2566802174 100;
BA_ "SAE_Document" BO_ 2566802174 "J1939-71";
BA_ "SAE_Document" BO_ 2633935870 "J1939-71";
BA_ "SAE_Document" BO_ 2633942014 "J1939-71";
BA_ "SAE_Document" BO_ 2633942526 "J1939-71";
BA_ "SAE_Document" BO_ 2633943038 "J1939-71";
BA_ "GenMsgSendType" BO_ 2565867006 0;
BA_ "GenMsgCycleTime" BO_ 2565867006 100;
BA_ "SAE_Document" BO_ 2565867006 "J1939-71";
BA_ "GenMsgSendType" BO_ 2364539646 0;
BA_ "GenMsgCycleTime" BO_ 2364539646 10;
BA_ "SAE_Document" BO_ 2364539646 "J1939-71";
BA_ "GenMsgSendType" BO_ 2566810110 0;
BA_ "GenMsgCycleTime" BO_ 2566810110 1000;
BA_ "SAE_Document" BO_ 2566810110 "J1939-71";
BA_ "GenMsgSendType" BO_ 2566825214 0;
BA_ "GenMsgCycleTime" BO_ 2566825214 1000;
BA_ "SAE_Document" BO_ 2566825214 "J1939-71";
BA_ "GenMsgSendType" BO_ 2566844158 0;
BA_ "GenMsgCycleTime" BO_ 2566844158 1000;
BA_ "SAE_Document" BO_ 2566844158 "J1939-71";
BA_ "GenMsgSendType" BO_ 2566785022 0;
BA_ "GenMsgCycleTime" BO_ 2566785022 5000;
BA_ "SAE_Document" BO_ 2566785022 "J1939-71";
BA_ "GenMsgSendType" BO_ 2565868542 0;
BA_ "GenMsgCycleTime" BO_ 2565868542 20;
BA_ "SAE_Document" BO_ 2565868542 "J1939-71";
BA_ "GenMsgSendType" BO_ 2633941758 2;
BA_ "GenMsgCycleTime" BO_ 2633941758 1000;
BA_ "SAE_Document" BO_ 2633941758 "J1939-71";
BA_ "GenMsgSendType" BO_ 2565865726 0;
BA_ "GenMsgCycleTime" BO_ 2565865726 100;
BA_ "SAE_Document" BO_ 2565865726 "J1939-71";
BA_ "GenMsgSendType" BO_ 2633932798 0;
BA_ "GenMsgCycleTime" BO_ 2633932798 1000;
BA_ "SAE_Document" BO_ 2633932798 "J1939-71";
BA_ "GenMsgSendType" BO_ 2566824190 0;
BA_ "GenMsgCycleTime" BO_ 2566824190 1000;
BA_ "SAE_Document" BO_ 2566824190 "J1939-71";
BA_ "GenMsgSendType" BO_ 2633933310 0;
BA_ "GenMsgCycleTime" BO_ 2633933310 1000;
BA_ "SAE_Document" BO_ 2633933310 "J1939-71";
BA_ "GenMsgSendType" BO_ 2633933566 0;
BA_ "GenMsgCycleTime" BO_ 2633933566 1000;
BA_ "SAE_Document" BO_ 2633933566 "J1939-71";
BA_ "GenMsgSendType" BO_ 2633933822 0;
BA_ "GenMsgCycleTime" BO_ 2633933822 1000;
BA_ "SAE_Document" BO_ 2633933822 "J1939-71";
BA_ "GenMsgSendType" BO_ 2566776062 0;
BA_ "GenMsgCycleTime" BO_ 2566776062 500;
BA_ "SAE_Document" BO_ 2566776062 "J1939-71";
BA_ "SAE_Document" BO_ 2566771454 "J1939-71";
BA_ "SAE_Document" BO_ 2566775806 "J1939-71";
BA_ "SAE_Document" BO_ 2633935358 "J1939-71";
BA_ "GenMsgSendType" BO_ 2365447166 0;
BA_ "GenMsgCycleTime" BO_ 2365447166 100;
BA_ "SAE_Document" BO_ 2365447166 "J1939-71";
BA_ "GenMsgSendType" BO_ 2365446654 0;
BA_ "GenMsgCycleTime" BO_ 2365446654 100;
BA_ "SAE_Document" BO_ 2365446654 "J1939-71";
BA_ "GenMsgSendType" BO_ 2365446142 0;
BA_ "GenMsgCycleTime" BO_ 2365446142 100;
BA_ "SAE_Document" BO_ 2365446142 "J1939-71";
BA_ "GenMsgSendType" BO_ 2633929470 0;
BA_ "GenMsgCycleTime" BO_ 2633929470 100;
BA_ "SAE_Document" BO_ 2633929470 "J1939-71";
BA_ "SAE_Document" BO_ 2633937406 "J1939-71";
BA_ "GenMsgSendType" BO_ 2364541694 0;
BA_ "GenMsgCycleTime" BO_ 2364541694 50;
BA_ "SAE_Document" BO_ 2364541694 "J1939-71";
BA_ "GenMsgSendType" BO_ 2566810366 0;
BA_ "GenMsgCycleTime" BO_ 2566810366 5000;
BA_ "SAE_Document" BO_ 2566810366 "J1939-71";
BA_ "GenMsgSendType" BO_ 2566767102 0;
BA_ "GenMsgCycleTime" BO_ 2566767102 500;
BA_ "SAE_Document" BO_ 2566767102 "J1939-71";
BA_ "GenMsgSendType" BO_ 2566839294 0;
BA_ "GenMsgCycleTime" BO_ 2566839294 5000;
BA_ "SAE_Document" BO_ 2566839294 "J1939-71";
BA_ "GenMsgSendType" BO_ 2566844414 0;
BA_ "GenMsgCycleTime" BO_ 2566844414 500;
BA_ "SAE_Document" BO_ 2566844414 "J1939-71";
BA_ "GenMsgSendType" BO_ 2633929726 0;
BA_ "GenMsgCycleTime" BO_ 2633929726 100;
BA_ "SAE_Document" BO_ 2633929726 "J1939-71";
BA_ "SAE_Document" BO_ 2566772222 "J1939-71";
BA_ "SAE_Document" BO_ 2633940734 "J1939-71";
BA_ "GenMsgSendType" BO_ 2566840318 0;
BA_ "GenMsgCycleTime" BO_ 2566840318 250;
BA_ "SAE_Document" BO_ 2566840318 "J1939-71";
BA_ "GenMsgSendType" BO_ 2364539902 0;
BA_ "GenMsgCycleTime" BO_ 2364539902 50;
BA_ "SAE_Document" BO_ 2364539902 "J1939-71";
BA_ "SPN" SG_ 2566768638 EngAltDroopAuxInputSelectState 2895;
BA_ "SAEDocument" SG_ 2566768638 EngAltDroopAuxInputSelectState "J1939-71";
BA_ "SPN" SG_ 2566768638 EngAltDropRemoteAccelSelectState 2894;
BA_ "SAEDocument" SG_ 2566768638 EngAltDropRemoteAccelSelectState "J1939-71";
BA_ "SPN" SG_ 2566768638 EngAltDroopAccel2SelectState 2893;
BA_ "SAEDocument" SG_ 2566768638 EngAltDroopAccel2SelectState "J1939-71";
BA_ "SPN" SG_ 2566768638 EngAltDroopAccel1SelectState 2889;
BA_ "SAEDocument" SG_ 2566768638 EngAltDroopAccel1SelectState "J1939-71";
BA_ "SPN" SG_ 2566768638 EngAltRatingSelectState 2888;
BA_ "SAEDocument" SG_ 2566768638 EngAltRatingSelectState "J1939-71";
BA_ "SigType" SG_ 2566768638 EngAltLowIdleSelectState 5;
BA_ "SPN" SG_ 2566768638 EngAltLowIdleSelectState 2891;
BA_ "SAEDocument" SG_ 2566768638 EngAltLowIdleSelectState "J1939-71";
BA_ "SigType" SG_ 2566768638 EngMultiUnitSyncState 5;
BA_ "SPN" SG_ 2566768638 EngMultiUnitSyncState 2890;
BA_ "SAEDocument" SG_ 2566768638 EngMultiUnitSyncState "J1939-71";
BA_ "SigType" SG_ 2566768638 EngAuxGovernorState 5;
BA_ "SPN" SG_ 2566768638 EngAuxGovernorState 2896;
BA_ "SAEDocument" SG_ 2566768638 EngAuxGovernorState "J1939-71";
BA_ "SigType" SG_ 2365443326 OprtorsDesiredDelayedLampOffTime 1;
BA_ "SPN" SG_ 2365443326 OprtorsDesiredDelayedLampOffTime 2877;
BA_ "SAEDocument" SG_ 2365443326 OprtorsDesiredDelayedLampOffTime "J1939-71";
BA_ "SigType" SG_ 2365443326 OperatorsDesiredBacklight 1;
BA_ "SPN" SG_ 2365443326 OperatorsDesiredBacklight 2878;
BA_ "SAEDocument" SG_ 2365443326 OperatorsDesiredBacklight "J1939-71";
BA_ "SigType" SG_ 2365443326 HighLowBeamSwitch 4;
BA_ "SPN" SG_ 2365443326 HighLowBeamSwitch 2874;
BA_ "SAEDocument" SG_ 2365443326 HighLowBeamSwitch "J1939-71";
BA_ "SigType" SG_ 2365443326 HazardLightSwitch 4;
BA_ "SPN" SG_ 2365443326 HazardLightSwitch 2875;
BA_ "SAEDocument" SG_ 2365443326 HazardLightSwitch "J1939-71";
BA_ "SPN" SG_ 2365443326 TurnSignalSwitch 2876;
BA_ "SAEDocument" SG_ 2365443326 TurnSignalSwitch "J1939-71";
BA_ "SPN" SG_ 2365443326 MainLightSwitch 2872;
BA_ "SAEDocument" SG_ 2365443326 MainLightSwitch "J1939-71";
BA_ "SPN" SG_ 2365443326 WorkLightSwitch 2873;
BA_ "SAEDocument" SG_ 2365443326 WorkLightSwitch "J1939-71";
BA_ "SPN" SG_ 2566776318 AppliedVehicleSpeedLimit 2595;
BA_ "SAEDocument" SG_ 2566776318 AppliedVehicleSpeedLimit "J1939-71";
BA_ "SPN" SG_ 2566776318 MaxVehicleSpeedLimit7 2594;
BA_ "SAEDocument" SG_ 2566776318 MaxVehicleSpeedLimit7 "J1939-71";
BA_ "SPN" SG_ 2566776318 MaxVehicleSpeedLimit6 2593;
BA_ "SAEDocument" SG_ 2566776318 MaxVehicleSpeedLimit6 "J1939-71";
BA_ "SPN" SG_ 2566776318 MaxVehicleSpeedLimit5 2592;
BA_ "SAEDocument" SG_ 2566776318 MaxVehicleSpeedLimit5 "J1939-71";
BA_ "SPN" SG_ 2566776318 MaxVehicleSpeedLimit4 2591;
BA_ "SAEDocument" SG_ 2566776318 MaxVehicleSpeedLimit4 "J1939-71";
BA_ "SPN" SG_ 2566776318 MaxVehicleSpeedLimit3 2590;
BA_ "SAEDocument" SG_ 2566776318 MaxVehicleSpeedLimit3 "J1939-71";
BA_ "SPN" SG_ 2566776318 MaxVehicleSpeedLimit2 2589;
BA_ "SAEDocument" SG_ 2566776318 MaxVehicleSpeedLimit2 "J1939-71";
BA_ "SPN" SG_ 2566776318 MaxVehicleSpeedLimit1 2588;
BA_ "SAEDocument" SG_ 2566776318 MaxVehicleSpeedLimit1 "J1939-71";
BA_ "SPN" SG_ 2566802686 OprtrsBlackOutIntensitySelection 1844;
BA_ "SAEDocument" SG_ 2566802686 OprtrsBlackOutIntensitySelection "J1939-71";
BA_ "SigType" SG_ 2566802686 BlackOutWorkLampSelect 5;
BA_ "SPN" SG_ 2566802686 BlackOutWorkLampSelect 1842;
BA_ "SAEDocument" SG_ 2566802686 BlackOutWorkLampSelect "J1939-71";
BA_ "SigType" SG_ 2566802686 NightVisionIlluminatorSelect 5;
BA_ "SPN" SG_ 2566802686 NightVisionIlluminatorSelect 1843;
BA_ "SAEDocument" SG_ 2566802686 NightVisionIlluminatorSelect "J1939-71";
BA_ "SigType" SG_ 2566802686 BlackOutBrake_StopLampSelect 5;
BA_ "SPN" SG_ 2566802686 BlackOutBrake_StopLampSelect 1841;
BA_ "SAEDocument" SG_ 2566802686 BlackOutBrake_StopLampSelect "J1939-71";
BA_ "SigType" SG_ 2566802686 ConvoyDrivingLampSelect 5;
BA_ "SPN" SG_ 2566802686 ConvoyDrivingLampSelect 1837;
BA_ "SAEDocument" SG_ 2566802686 ConvoyDrivingLampSelect "J1939-71";
BA_ "SigType" SG_ 2566802686 ConvoyLampSelect 5;
BA_ "SPN" SG_ 2566802686 ConvoyLampSelect 1838;
BA_ "SAEDocument" SG_ 2566802686 ConvoyLampSelect "J1939-71";
BA_ "SigType" SG_ 2566802686 FrontBlackOutMarkerLampSelect 5;
BA_ "SPN" SG_ 2566802686 FrontBlackOutMarkerLampSelect 1839;
BA_ "SAEDocument" SG_ 2566802686 FrontBlackOutMarkerLampSelect "J1939-71";
BA_ "SigType" SG_ 2566802686 RearBlackOutMarkerSelect 5;
BA_ "SPN" SG_ 2566802686 RearBlackOutMarkerSelect 1840;
BA_ "SAEDocument" SG_ 2566802686 RearBlackOutMarkerSelect "J1939-71";
BA_ "SigType" SG_ 2566774014 SlowVesselModeStatus 5;
BA_ "SPN" SG_ 2566774014 SlowVesselModeStatus 2617;
BA_ "SAEDocument" SG_ 2566774014 SlowVesselModeStatus "J1939-71";
BA_ "SigType" SG_ 2566774014 TrollingModeStatus 5;
BA_ "SPN" SG_ 2566774014 TrollingModeStatus 2616;
BA_ "SAEDocument" SG_ 2566774014 TrollingModeStatus "J1939-71";
BA_ "SPN" SG_ 2566774014 EngThrttlSynchrnzationModeStatus 2615;
BA_ "SAEDocument" SG_ 2566774014 EngThrttlSynchrnzationModeStatus "J1939-71";
BA_ "SigType" SG_ 2566823166 EngMainBearing11Temp 1;
BA_ "SPN" SG_ 2566823166 EngMainBearing11Temp 1167;
BA_ "SAEDocument" SG_ 2566823166 EngMainBearing11Temp "J1939-71";
BA_ "SigType" SG_ 2566823166 EngMainBearing10Temp 1;
BA_ "SPN" SG_ 2566823166 EngMainBearing10Temp 1166;
BA_ "SAEDocument" SG_ 2566823166 EngMainBearing10Temp "J1939-71";
BA_ "SigType" SG_ 2566823166 EngMainBearing9Temp 1;
BA_ "SPN" SG_ 2566823166 EngMainBearing9Temp 1165;
BA_ "SAEDocument" SG_ 2566823166 EngMainBearing9Temp "J1939-71";
BA_ "SigType" SG_ 2566823422 EngMainBearing8Temp 1;
BA_ "SPN" SG_ 2566823422 EngMainBearing8Temp 1164;
BA_ "SAEDocument" SG_ 2566823422 EngMainBearing8Temp "J1939-71";
BA_ "SigType" SG_ 2566823422 EngMainBearing7Temp 1;
BA_ "SPN" SG_ 2566823422 EngMainBearing7Temp 1163;
BA_ "SAEDocument" SG_ 2566823422 EngMainBearing7Temp "J1939-71";
BA_ "SigType" SG_ 2566823422 EngMainBearing6Temp 1;
BA_ "SPN" SG_ 2566823422 EngMainBearing6Temp 1162;
BA_ "SAEDocument" SG_ 2566823422 EngMainBearing6Temp "J1939-71";
BA_ "SigType" SG_ 2566823422 EngMainBearing5Temp 1;
BA_ "SPN" SG_ 2566823422 EngMainBearing5Temp 1161;
BA_ "SAEDocument" SG_ 2566823422 EngMainBearing5Temp "J1939-71";
BA_ "SigType" SG_ 2566823678 EngMainBearing4Temp 1;
BA_ "SPN" SG_ 2566823678 EngMainBearing4Temp 1160;
BA_ "SAEDocument" SG_ 2566823678 EngMainBearing4Temp "J1939-71";
BA_ "SigType" SG_ 2566823678 EngMainBearing3Temp 1;
BA_ "SPN" SG_ 2566823678 EngMainBearing3Temp 1159;
BA_ "SAEDocument" SG_ 2566823678 EngMainBearing3Temp "J1939-71";
BA_ "SigType" SG_ 2566823678 EngMainBearing2Temp 1;
BA_ "SPN" SG_ 2566823678 EngMainBearing2Temp 1158;
BA_ "SAEDocument" SG_ 2566823678 EngMainBearing2Temp "J1939-71";
BA_ "SigType" SG_ 2566823678 EngMainBearing1Temp 1;
BA_ "SPN" SG_ 2566823678 EngMainBearing1Temp 1157;
BA_ "SAEDocument" SG_ 2566823678 EngMainBearing1Temp "J1939-71";
BA_ "SPN" SG_ 2432595710 DisplayDeadbands 2577;
BA_ "SAEDocument" SG_ 2432595710 DisplayDeadbands "J1939-71";
BA_ "SPN" SG_ 2432595710 LEDPatternCtrl 2578;
BA_ "SAEDocument" SG_ 2432595710 LEDPatternCtrl "J1939-71";
BA_ "SPN" SG_ 2432595710 LEDDisplayDeadbandCtrl 1806;
BA_ "SAEDocument" SG_ 2432595710 LEDDisplayDeadbandCtrl "J1939-71";
BA_ "SPN" SG_ 2432595710 LEDDisplayModeCtrl 1805;
BA_ "SAEDocument" SG_ 2432595710 LEDDisplayModeCtrl "J1939-71";
BA_ "SPN" SG_ 2432595710 LEDDisplayData1 1573;
BA_ "SAEDocument" SG_ 2432595710 LEDDisplayData1 "J1939-71";
BA_ "SigType" SG_ 2365486590 LaserStrikeDataLatency 1;
BA_ "SPN" SG_ 2365486590 LaserStrikeDataLatency 2793;
BA_ "SAEDocument" SG_ 2365486590 LaserStrikeDataLatency "J1939-71";
BA_ "SPN" SG_ 2365486590 LaserReceiverType 2576;
BA_ "SAEDocument" SG_ 2365486590 LaserReceiverType "J1939-71";
BA_ "SigType" SG_ 2365486590 LaserStrikeVerticalDeviation 1;
BA_ "SPN" SG_ 2365486590 LaserStrikeVerticalDeviation 1574;
BA_ "SAEDocument" SG_ 2365486590 LaserStrikeVerticalDeviation "J1939-71";
BA_ "SigType" SG_ 2365486590 AbsLaserStrikePos 1;
BA_ "SPN" SG_ 2365486590 AbsLaserStrikePos 2794;
BA_ "SAEDocument" SG_ 2365486590 AbsLaserStrikePos "J1939-71";
BA_ "SPN" SG_ 2365485566 LaserTracerInformation 1583;
BA_ "SAEDocument" SG_ 2365485566 LaserTracerInformation "J1939-71";
BA_ "SPN" SG_ 2365485566 LEDDisplayData2 1582;
BA_ "SAEDocument" SG_ 2365485566 LEDDisplayData2 "J1939-71";
BA_ "SigType" SG_ 2365485566 LaserTracerHorizontalDeviation 1;
BA_ "SPN" SG_ 2365485566 LaserTracerHorizontalDeviation 1581;
BA_ "SAEDocument" SG_ 2365485566 LaserTracerHorizontalDeviation "J1939-71";
BA_ "SigType" SG_ 2365485566 LaserTracerVerticalDistance 1;
BA_ "SPN" SG_ 2365485566 LaserTracerVerticalDistance 1580;
BA_ "SAEDocument" SG_ 2365485566 LaserTracerVerticalDistance "J1939-71";
BA_ "SigType" SG_ 2365485566 LaserTracerTargetDeviation 1;
BA_ "SPN" SG_ 2365485566 LaserTracerTargetDeviation 1579;
BA_ "SAEDocument" SG_ 2365485566 LaserTracerTargetDeviation "J1939-71";
BA_ "SigType" SG_ 2633939454 TripCruiseFuelUsed 1;
BA_ "SPN" SG_ 2633939454 TripCruiseFuelUsed 1005;
BA_ "SAEDocument" SG_ 2633939454 TripCruiseFuelUsed "J1939-71";
BA_ "SigType" SG_ 2633939454 TripVehicleIdleFuelUsed 1;
BA_ "SPN" SG_ 2633939454 TripVehicleIdleFuelUsed 1004;
BA_ "SAEDocument" SG_ 2633939454 TripVehicleIdleFuelUsed "J1939-71";
BA_ "SigType" SG_ 2633939454 TripDriveFuelUsed 1;
BA_ "SPN" SG_ 2633939454 TripDriveFuelUsed 1001;
BA_ "SAEDocument" SG_ 2633939454 TripDriveFuelUsed "J1939-71";
BA_ "SigType" SG_ 2633939454 TripPTOGovernorNonmovingFuelUsed 1;
BA_ "SPN" SG_ 2633939454 TripPTOGovernorNonmovingFuelUsed 1003;
BA_ "SAEDocument" SG_ 2633939454 TripPTOGovernorNonmovingFuelUsed "J1939-71";
BA_ "SigType" SG_ 2633939454 TripPTOGovernorMovingFuelUsed 1;
BA_ "SPN" SG_ 2633939454 TripPTOGovernorMovingFuelUsed 1002;
BA_ "SAEDocument" SG_ 2633939454 TripPTOGovernorMovingFuelUsed "J1939-71";
BA_ "SigType" SG_ 2633939454 TripDriveFuelEconomy 1;
BA_ "SPN" SG_ 2633939454 TripDriveFuelEconomy 1006;
BA_ "SAEDocument" SG_ 2633939454 TripDriveFuelEconomy "J1939-71";
BA_ "SigType" SG_ 2365486334 BldeHeightSetPointHighResolution 1;
BA_ "SPN" SG_ 2365486334 BldeHeightSetPointHighResolution 1759;
BA_ "SAEDocument" SG_ 2365486334 BldeHeightSetPointHighResolution "J1939-71";
BA_ "SigType" SG_ 2365486334 ModifyLevelingSystemSetPoint 1;
BA_ "SPN" SG_ 2365486334 ModifyLevelingSystemSetPoint 1575;
BA_ "SAEDocument" SG_ 2365486334 ModifyLevelingSystemSetPoint "J1939-71";
BA_ "SigType" SG_ 2364542462 StElvtnSensor2ReferenceElevation 5;
BA_ "SPN" SG_ 2364542462 StElvtnSensor2ReferenceElevation 5406;
BA_ "SAEDocument" SG_ 2364542462 StElvtnSensor2ReferenceElevation "J1939-71";
BA_ "SigType" SG_ 2364542462 StElvtnSensor1ReferenceElevation 5;
BA_ "SPN" SG_ 2364542462 StElvtnSensor1ReferenceElevation 5405;
BA_ "SAEDocument" SG_ 2364542462 StElvtnSensor1ReferenceElevation "J1939-71";
BA_ "SPN" SG_ 2364542462 SdshftDsrdBldeOffsetOperatorCtrl 3339;
BA_ "SAEDocument" SG_ 2364542462 SdshftDsrdBldeOffsetOperatorCtrl "J1939-71";
BA_ "SPN" SG_ 2364542462 SdshiftBladeCtrlModeOperatorCtrl 3338;
BA_ "SAEDocument" SG_ 2364542462 SdshiftBladeCtrlModeOperatorCtrl "J1939-71";
BA_ "SPN" SG_ 2364542462 RghtDsredBladeOffsetOperatorCtrl 3337;
BA_ "SAEDocument" SG_ 2364542462 RghtDsredBladeOffsetOperatorCtrl "J1939-71";
BA_ "SPN" SG_ 2364542462 LftDsiredBladeOffsetOperatorCtrl 3336;
BA_ "SAEDocument" SG_ 2364542462 LftDsiredBladeOffsetOperatorCtrl "J1939-71";
BA_ "SPN" SG_ 2364542462 RightBladeCtrlModeOperatorCtrl 3335;
BA_ "SAEDocument" SG_ 2364542462 RightBladeCtrlModeOperatorCtrl "J1939-71";
BA_ "SPN" SG_ 2364542462 LeftBladeCtrlModeOperatorCtrl 3334;
BA_ "SAEDocument" SG_ 2364542462 LeftBladeCtrlModeOperatorCtrl "J1939-71";
BA_ "SPN" SG_ 2364542462 BladeAutoModeCmd 3158;
BA_ "SAEDocument" SG_ 2364542462 BladeAutoModeCmd "J1939-71";
BA_ "SPN" SG_ 2364542462 DesiredGradeOffsetSwitch 3157;
BA_ "SAEDocument" SG_ 2364542462 DesiredGradeOffsetSwitch "J1939-71";
BA_ "SPN" SG_ 2364542462 BladeCtrlModeSwitch 3156;
BA_ "SAEDocument" SG_ 2364542462 BladeCtrlModeSwitch "J1939-71";
BA_ "SigType" SG_ 2365486078 MastPos 1;
BA_ "SPN" SG_ 2365486078 MastPos 1576;
BA_ "SAEDocument" SG_ 2365486078 MastPos "J1939-71";
BA_ "SPN" SG_ 2633937918 FlexibleFuelPercentage 5458;
BA_ "SAEDocument" SG_ 2633937918 FlexibleFuelPercentage "J1939-71";
BA_ "SigType" SG_ 2633937918 TripAverageFuelRate 1;
BA_ "SPN" SG_ 2633937918 TripAverageFuelRate 1029;
BA_ "SAEDocument" SG_ 2633937918 TripAverageFuelRate "J1939-71";
BA_ "SigType" SG_ 2633937918 TotalEngPTOGovernorFuelUsed 1;
BA_ "SPN" SG_ 2633937918 TotalEngPTOGovernorFuelUsed 1028;
BA_ "SAEDocument" SG_ 2633937918 TotalEngPTOGovernorFuelUsed "J1939-71";
BA_ "SigType" SG_ 2566845182 EngAverageFuelEconomy 1;
BA_ "SPN" SG_ 2566845182 EngAverageFuelEconomy 185;
BA_ "SAEDocument" SG_ 2566845182 EngAverageFuelEconomy "J1939-71";
BA_ "SigType" SG_ 2566845182 EngInstantaneousFuelEconomy 1;
BA_ "SPN" SG_ 2566845182 EngInstantaneousFuelEconomy 184;
BA_ "SAEDocument" SG_ 2566845182 EngInstantaneousFuelEconomy "J1939-71";
BA_ "SigType" SG_ 2566845182 EngFuelRate 1;
BA_ "SPN" SG_ 2566845182 EngFuelRate 183;
BA_ "SAEDocument" SG_ 2566845182 EngFuelRate "J1939-71";
BA_ "SigType" SG_ 2566845182 EngThrottleValve2Pos 1;
BA_ "SPN" SG_ 2566845182 EngThrottleValve2Pos 3673;
BA_ "SAEDocument" SG_ 2566845182 EngThrottleValve2Pos "J1939-71";
BA_ "SigType" SG_ 2566845182 EngThrottleValve1Pos 1;
BA_ "SPN" SG_ 2566845182 EngThrottleValve1Pos 51;
BA_ "SAEDocument" SG_ 2566845182 EngThrottleValve1Pos "J1939-71";
BA_ "SigType" SG_ 2566842878 EngTotalFuelUsed 1;
BA_ "SPN" SG_ 2566842878 EngTotalFuelUsed 250;
BA_ "SAEDocument" SG_ 2566842878 EngTotalFuelUsed "J1939-71";
BA_ "SigType" SG_ 2566842878 EngTripFuel 1;
BA_ "SPN" SG_ 2566842878 EngTripFuel 182;
BA_ "SAEDocument" SG_ 2566842878 EngTripFuel "J1939-71";
BA_ "SigType" SG_ 2633883646 FrontWheelDriveActuatorStatus 4;
BA_ "SPN" SG_ 2633883646 FrontWheelDriveActuatorStatus 2612;
BA_ "SAEDocument" SG_ 2633883646 FrontWheelDriveActuatorStatus "J1939-71";
BA_ "SigType" SG_ 2633880062 FMSstandardSWversionSupported 1;
BA_ "SPN" SG_ 2633880062 FMSstandardSWversionSupported 2806;
BA_ "SAEDocument" SG_ 2633880062 FMSstandardSWversionSupported "J1939-71";
BA_ "SigType" SG_ 2633880062 FMSstandardRequestsSupported 5;
BA_ "SPN" SG_ 2633880062 FMSstandardRequestsSupported 2805;
BA_ "SAEDocument" SG_ 2633880062 FMSstandardRequestsSupported "J1939-71";
BA_ "SigType" SG_ 2633880062 FMSstandardDiagnosticsSupported 5;
BA_ "SPN" SG_ 2633880062 FMSstandardDiagnosticsSupported 2804;
BA_ "SAEDocument" SG_ 2633880062 FMSstandardDiagnosticsSupported "J1939-71";
BA_ "SigType" SG_ 2566806526 LnDpartureIndicationEnableStatus 5;
BA_ "SPN" SG_ 2566806526 LnDpartureIndicationEnableStatus 1702;
BA_ "SAEDocument" SG_ 2566806526 LnDpartureIndicationEnableStatus "J1939-71";
BA_ "SigType" SG_ 2566806526 LaneTrackingStatusLeftSide 5;
BA_ "SPN" SG_ 2566806526 LaneTrackingStatusLeftSide 1710;
BA_ "SAEDocument" SG_ 2566806526 LaneTrackingStatusLeftSide "J1939-71";
BA_ "SigType" SG_ 2566806526 LaneTrackingStatusRightSide 5;
BA_ "SPN" SG_ 2566806526 LaneTrackingStatusRightSide 1711;
BA_ "SAEDocument" SG_ 2566806526 LaneTrackingStatusRightSide "J1939-71";
BA_ "SigType" SG_ 2431649790 LaneDepartureImminentLeftSide 5;
BA_ "SPN" SG_ 2431649790 LaneDepartureImminentLeftSide 1700;
BA_ "SAEDocument" SG_ 2431649790 LaneDepartureImminentLeftSide "J1939-71";
BA_ "SigType" SG_ 2431649790 LaneDepartureImminentRightSide 5;
BA_ "SPN" SG_ 2431649790 LaneDepartureImminentRightSide 1701;
BA_ "SAEDocument" SG_ 2431649790 LaneDepartureImminentRightSide "J1939-71";
BA_ "SigType" SG_ 2431649790 LaneDepartureRight 5;
BA_ "SPN" SG_ 2431649790 LaneDepartureRight 3566;
BA_ "SAEDocument" SG_ 2431649790 LaneDepartureRight "J1939-71";
BA_ "SigType" SG_ 2431649790 LaneDepartureLeft 5;
BA_ "SPN" SG_ 2431649790 LaneDepartureLeft 3565;
BA_ "SAEDocument" SG_ 2431649790 LaneDepartureLeft "J1939-71";
BA_ "SigType" SG_ 2633929214 EngFuelLeakage2 5;
BA_ "SPN" SG_ 2633929214 EngFuelLeakage2 1240;
BA_ "SAEDocument" SG_ 2633929214 EngFuelLeakage2 "J1939-71";
BA_ "SigType" SG_ 2633929214 EngFuelLeakage1 5;
BA_ "SPN" SG_ 2633929214 EngFuelLeakage1 1239;
BA_ "SAEDocument" SG_ 2633929214 EngFuelLeakage1 "J1939-71";
BA_ "SPN" SG_ 2566831614 FanDriveBypassCmdStatus 4212;
BA_ "SAEDocument" SG_ 2566831614 FanDriveBypassCmdStatus "J1939-71";
BA_ "SigType" SG_ 2566831614 HydFanMotorPress 1;
BA_ "SPN" SG_ 2566831614 HydFanMotorPress 4211;
BA_ "SAEDocument" SG_ 2566831614 HydFanMotorPress "J1939-71";
BA_ "SigType" SG_ 2566831614 FanSpeed 1;
BA_ "SPN" SG_ 2566831614 FanSpeed 1639;
BA_ "SAEDocument" SG_ 2566831614 FanSpeed "J1939-71";
BA_ "SPN" SG_ 2566831614 FanDriveState 977;
BA_ "SAEDocument" SG_ 2566831614 FanDriveState "J1939-71";
BA_ "SPN" SG_ 2566831614 EstPercentFanSpeed 975;
BA_ "SAEDocument" SG_ 2566831614 EstPercentFanSpeed "J1939-71";
BA_ "SigType" SG_ 2566820094 EngTorqueLimit6AxleInput 1;
BA_ "SPN" SG_ 2566820094 EngTorqueLimit6AxleInput 1263;
BA_ "SAEDocument" SG_ 2566820094 EngTorqueLimit6AxleInput "J1939-71";
BA_ "SigType" SG_ 2566820094 EngTorqueLimit5Switch 1;
BA_ "SPN" SG_ 2566820094 EngTorqueLimit5Switch 1262;
BA_ "SAEDocument" SG_ 2566820094 EngTorqueLimit5Switch "J1939-71";
BA_ "SigType" SG_ 2566820094 EngTorqueLimit4Trans 1;
BA_ "SPN" SG_ 2566820094 EngTorqueLimit4Trans 1261;
BA_ "SAEDocument" SG_ 2566820094 EngTorqueLimit4Trans "J1939-71";
BA_ "SigType" SG_ 2566820094 EngTorqueLimit3Trans 1;
BA_ "SPN" SG_ 2566820094 EngTorqueLimit3Trans 1260;
BA_ "SAEDocument" SG_ 2566820094 EngTorqueLimit3Trans "J1939-71";
BA_ "SigType" SG_ 2566820094 TransGearRatio3 1;
BA_ "SPN" SG_ 2566820094 TransGearRatio3 1259;
BA_ "SAEDocument" SG_ 2566820094 TransGearRatio3 "J1939-71";
BA_ "SigType" SG_ 2566820094 EngTorqueLimit2Trans 1;
BA_ "SPN" SG_ 2566820094 EngTorqueLimit2Trans 1258;
BA_ "SAEDocument" SG_ 2566820094 EngTorqueLimit2Trans "J1939-71";
BA_ "SigType" SG_ 2566820094 TransGearRatio2 1;
BA_ "SPN" SG_ 2566820094 TransGearRatio2 1257;
BA_ "SAEDocument" SG_ 2566820094 TransGearRatio2 "J1939-71";
BA_ "SigType" SG_ 2566820094 EngTorqueLimit1Trans 1;
BA_ "SPN" SG_ 2566820094 EngTorqueLimit1Trans 1256;
BA_ "SAEDocument" SG_ 2566820094 EngTorqueLimit1Trans "J1939-71";
BA_ "SigType" SG_ 2566820094 TransGearRatio1 1;
BA_ "SPN" SG_ 2566820094 TransGearRatio1 1255;
BA_ "SAEDocument" SG_ 2566820094 TransGearRatio1 "J1939-71";
BA_ "SPN" SG_ 2566820094 EngTorqueLimitFeature 1632;
BA_ "SAEDocument" SG_ 2566820094 EngTorqueLimitFeature "J1939-71";
BA_ "SigType" SG_ 2566820094 TorqueLimitingFeatureStatus 5;
BA_ "SPN" SG_ 2566820094 TorqueLimitingFeatureStatus 1254;
BA_ "SAEDocument" SG_ 2566820094 TorqueLimitingFeatureStatus "J1939-71";
BA_ "SigType" SG_ 2566820094 CalibRecordDurationTime 1;
BA_ "SPN" SG_ 2566820094 CalibRecordDurationTime 1253;
BA_ "SAEDocument" SG_ 2566820094 CalibRecordDurationTime "J1939-71";
BA_ "SigType" SG_ 2566820094 CalibRecordStartYear 1;
BA_ "SPN" SG_ 2566820094 CalibRecordStartYear 1252;
BA_ "SAEDocument" SG_ 2566820094 CalibRecordStartYear "J1939-71";
BA_ "SigType" SG_ 2566820094 CalibRecordStartDay 1;
BA_ "SPN" SG_ 2566820094 CalibRecordStartDay 1251;
BA_ "SAEDocument" SG_ 2566820094 CalibRecordStartDay "J1939-71";
BA_ "SigType" SG_ 2566820094 CalibRecordStartMonth 1;
BA_ "SPN" SG_ 2566820094 CalibRecordStartMonth 1250;
BA_ "SAEDocument" SG_ 2566820094 CalibRecordStartMonth "J1939-71";
BA_ "SigType" SG_ 2566820094 EngPeakTorque2 1;
BA_ "SPN" SG_ 2566820094 EngPeakTorque2 1249;
BA_ "SAEDocument" SG_ 2566820094 EngPeakTorque2 "J1939-71";
BA_ "SigType" SG_ 2566820094 EngPeakTorque1 1;
BA_ "SPN" SG_ 2566820094 EngPeakTorque1 1248;
BA_ "SAEDocument" SG_ 2566820094 EngPeakTorque1 "J1939-71";
BA_ "SigType" SG_ 2566820094 EngPower 1;
BA_ "SPN" SG_ 2566820094 EngPower 1247;
BA_ "SAEDocument" SG_ 2566820094 EngPower "J1939-71";
BA_ "SigType" SG_ 2566820094 NumberOfEngTorqueHistoryRecords 1;
BA_ "SPN" SG_ 2566820094 NumberOfEngTorqueHistoryRecords 1246;
BA_ "SAEDocument" SG_ 2566820094 NumberOfEngTorqueHistoryRecords "J1939-71";
BA_ "SigType" SG_ 2364542206 TransClutch_ConverterInputSpeed 1;
BA_ "SPN" SG_ 2364542206 TransClutch_ConverterInputSpeed 5052;
BA_ "SAEDocument" SG_ 2364542206 TransClutch_ConverterInputSpeed "J1939-71";
BA_ "SigType" SG_ 2364542206 TransTorqueConverterRatio 1;
BA_ "SPN" SG_ 2364542206 TransTorqueConverterRatio 3030;
BA_ "SAEDocument" SG_ 2364542206 TransTorqueConverterRatio "J1939-71";
BA_ "SigType" SG_ 2566802174 TrnsRverseGearShiftInhibitStatus 4;
BA_ "SPN" SG_ 2566802174 TrnsRverseGearShiftInhibitStatus 4261;
BA_ "SAEDocument" SG_ 2566802174 TrnsRverseGearShiftInhibitStatus "J1939-71";
BA_ "SigType" SG_ 2566802174 TrnsCrrentRangeDisplayBlankState 5;
BA_ "SPN" SG_ 2566802174 TrnsCrrentRangeDisplayBlankState 4176;
BA_ "SAEDocument" SG_ 2566802174 TrnsCrrentRangeDisplayBlankState "J1939-71";
BA_ "SigType" SG_ 2566802174 TransWarningIndicator 5;
BA_ "SPN" SG_ 2566802174 TransWarningIndicator 5344;
BA_ "SAEDocument" SG_ 2566802174 TransWarningIndicator "J1939-71";
BA_ "SigType" SG_ 2566802174 TransMode8Indicator 5;
BA_ "SPN" SG_ 2566802174 TransMode8Indicator 4253;
BA_ "SAEDocument" SG_ 2566802174 TransMode8Indicator "J1939-71";
BA_ "SigType" SG_ 2566802174 TransMode7Indicator 5;
BA_ "SPN" SG_ 2566802174 TransMode7Indicator 4252;
BA_ "SAEDocument" SG_ 2566802174 TransMode7Indicator "J1939-71";
BA_ "SigType" SG_ 2566802174 TransMode6Indicator 5;
BA_ "SPN" SG_ 2566802174 TransMode6Indicator 4251;
BA_ "SAEDocument" SG_ 2566802174 TransMode6Indicator "J1939-71";
BA_ "SigType" SG_ 2566802174 TransMode5Indicator 5;
BA_ "SPN" SG_ 2566802174 TransMode5Indicator 4250;
BA_ "SAEDocument" SG_ 2566802174 TransMode5Indicator "J1939-71";
BA_ "SPN" SG_ 2566802174 TransRequestedGearFeedback 3289;
BA_ "SAEDocument" SG_ 2566802174 TransRequestedGearFeedback "J1939-71";
BA_ "SigType" SG_ 2566802174 TransMode1Indicator 5;
BA_ "SPN" SG_ 2566802174 TransMode1Indicator 2536;
BA_ "SAEDocument" SG_ 2566802174 TransMode1Indicator "J1939-71";
BA_ "SigType" SG_ 2566802174 TransMode2Indicator 5;
BA_ "SPN" SG_ 2566802174 TransMode2Indicator 2537;
BA_ "SAEDocument" SG_ 2566802174 TransMode2Indicator "J1939-71";
BA_ "SigType" SG_ 2566802174 TransMode3Indicator 5;
BA_ "SPN" SG_ 2566802174 TransMode3Indicator 2538;
BA_ "SAEDocument" SG_ 2566802174 TransMode3Indicator "J1939-71";
BA_ "SigType" SG_ 2566802174 TransMode4Indicator 5;
BA_ "SPN" SG_ 2566802174 TransMode4Indicator 2539;
BA_ "SAEDocument" SG_ 2566802174 TransMode4Indicator "J1939-71";
BA_ "SigType" SG_ 2566802174 TransShiftInhibitIndicator 5;
BA_ "SPN" SG_ 2566802174 TransShiftInhibitIndicator 1851;
BA_ "SAEDocument" SG_ 2566802174 TransShiftInhibitIndicator "J1939-71";
BA_ "SigType" SG_ 2566802174 TransEngCrankEnable 5;
BA_ "SPN" SG_ 2566802174 TransEngCrankEnable 2900;
BA_ "SAEDocument" SG_ 2566802174 TransEngCrankEnable "J1939-71";
BA_ "SigType" SG_ 2566802174 ActiveShiftConsoleIndicator 5;
BA_ "SPN" SG_ 2566802174 ActiveShiftConsoleIndicator 2945;
BA_ "SAEDocument" SG_ 2566802174 ActiveShiftConsoleIndicator "J1939-71";
BA_ "SigType" SG_ 2566802174 TransReadyForBrakeRelease 5;
BA_ "SPN" SG_ 2566802174 TransReadyForBrakeRelease 3086;
BA_ "SAEDocument" SG_ 2566802174 TransReadyForBrakeRelease "J1939-71";
BA_ "SigType" SG_ 2566802174 TrnsRqstedRangeDisplayFlashState 5;
BA_ "SPN" SG_ 2566802174 TrnsRqstedRangeDisplayFlashState 1849;
BA_ "SAEDocument" SG_ 2566802174 TrnsRqstedRangeDisplayFlashState "J1939-71";
BA_ "SigType" SG_ 2566802174 TrnsRqstedRangeDisplayBlankState 5;
BA_ "SPN" SG_ 2566802174 TrnsRqstedRangeDisplayBlankState 1850;
BA_ "SAEDocument" SG_ 2566802174 TrnsRqstedRangeDisplayBlankState "J1939-71";
BA_ "SigType" SG_ 2566802174 TransServiceIndicator 5;
BA_ "SPN" SG_ 2566802174 TransServiceIndicator 4178;
BA_ "SAEDocument" SG_ 2566802174 TransServiceIndicator "J1939-71";
BA_ "SigType" SG_ 2633935870 ClutchLifeRemaining 1;
BA_ "SPN" SG_ 2633935870 ClutchLifeRemaining 2983;
BA_ "SAEDocument" SG_ 2633935870 ClutchLifeRemaining "J1939-71";
BA_ "SPN" SG_ 2633935870 LowestPossibleGear 1114;
BA_ "SAEDocument" SG_ 2633935870 LowestPossibleGear "J1939-71";
BA_ "SPN" SG_ 2633935870 HighestPossibleGear 1115;
BA_ "SAEDocument" SG_ 2633935870 HighestPossibleGear "J1939-71";
BA_ "SPN" SG_ 2633935870 RecommendedGear 1113;
BA_ "SAEDocument" SG_ 2633935870 RecommendedGear "J1939-71";
BA_ "SigType" SG_ 2633942014 TransForwardDirectionSwitch 5;
BA_ "SPN" SG_ 2633942014 TransForwardDirectionSwitch 903;
BA_ "SAEDocument" SG_ 2633942014 TransForwardDirectionSwitch "J1939-71";
BA_ "SigType" SG_ 2633942014 TransNeutralSwitch 5;
BA_ "SPN" SG_ 2633942014 TransNeutralSwitch 604;
BA_ "SAEDocument" SG_ 2633942014 TransNeutralSwitch "J1939-71";
BA_ "SigType" SG_ 2633942014 TransReverseDirectionSwitch 5;
BA_ "SPN" SG_ 2633942014 TransReverseDirectionSwitch 767;
BA_ "SAEDocument" SG_ 2633942014 TransReverseDirectionSwitch "J1939-71";
BA_ "SigType" SG_ 2633942014 TransLowRangeSenseSwitch 5;
BA_ "SPN" SG_ 2633942014 TransLowRangeSenseSwitch 779;
BA_ "SAEDocument" SG_ 2633942014 TransLowRangeSenseSwitch "J1939-71";
BA_ "SigType" SG_ 2633942014 TransHighRangeSenseSwitch 5;
BA_ "SPN" SG_ 2633942014 TransHighRangeSenseSwitch 778;
BA_ "SAEDocument" SG_ 2633942014 TransHighRangeSenseSwitch "J1939-71";
BA_ "SigType" SG_ 2633942526 TransSynchronizerBrakeValue 1;
BA_ "SPN" SG_ 2633942526 TransSynchronizerBrakeValue 54;
BA_ "SAEDocument" SG_ 2633942526 TransSynchronizerBrakeValue "J1939-71";
BA_ "SigType" SG_ 2633942526 TransSynchronizerClutchValue 1;
BA_ "SPN" SG_ 2633942526 TransSynchronizerClutchValue 53;
BA_ "SAEDocument" SG_ 2633942526 TransSynchronizerClutchValue "J1939-71";
BA_ "SigType" SG_ 2633943038 TransInertiaBrakeActuator 5;
BA_ "SPN" SG_ 2633943038 TransInertiaBrakeActuator 787;
BA_ "SAEDocument" SG_ 2633943038 TransInertiaBrakeActuator "J1939-71";
BA_ "SigType" SG_ 2633943038 TransDefuelActuator 5;
BA_ "SPN" SG_ 2633943038 TransDefuelActuator 786;
BA_ "SAEDocument" SG_ 2633943038 TransDefuelActuator "J1939-71";
BA_ "SigType" SG_ 2633943038 TransLockupClutchActuator 5;
BA_ "SPN" SG_ 2633943038 TransLockupClutchActuator 740;
BA_ "SAEDocument" SG_ 2633943038 TransLockupClutchActuator "J1939-71";
BA_ "SigType" SG_ 2633943038 TransClutchActuator 5;
BA_ "SPN" SG_ 2633943038 TransClutchActuator 788;
BA_ "SAEDocument" SG_ 2633943038 TransClutchActuator "J1939-71";
BA_ "SigType" SG_ 2633943038 TransSplitterIndirectActuator 5;
BA_ "SPN" SG_ 2633943038 TransSplitterIndirectActuator 771;
BA_ "SAEDocument" SG_ 2633943038 TransSplitterIndirectActuator "J1939-71";
BA_ "SigType" SG_ 2633943038 TransSplitterDirectActuator 5;
BA_ "SPN" SG_ 2633943038 TransSplitterDirectActuator 770;
BA_ "SAEDocument" SG_ 2633943038 TransSplitterDirectActuator "J1939-71";
BA_ "SigType" SG_ 2633943038 TransRangeLowActuator 5;
BA_ "SPN" SG_ 2633943038 TransRangeLowActuator 769;
BA_ "SAEDocument" SG_ 2633943038 TransRangeLowActuator "J1939-71";
BA_ "SigType" SG_ 2633943038 TransRangeHighActuator 5;
BA_ "SPN" SG_ 2633943038 TransRangeHighActuator 768;
BA_ "SAEDocument" SG_ 2633943038 TransRangeHighActuator "J1939-71";
BA_ "SigType" SG_ 2633943038 TransShiftFingerGearActuator2 5;
BA_ "SPN" SG_ 2633943038 TransShiftFingerGearActuator2 784;
BA_ "SAEDocument" SG_ 2633943038 TransShiftFingerGearActuator2 "J1939-71";
BA_ "SigType" SG_ 2633943038 TransShiftFingerRailActuator2 5;
BA_ "SPN" SG_ 2633943038 TransShiftFingerRailActuator2 783;
BA_ "SAEDocument" SG_ 2633943038 TransShiftFingerRailActuator2 "J1939-71";
BA_ "SigType" SG_ 2633943038 TransShiftFingerGearActuator1 5;
BA_ "SPN" SG_ 2633943038 TransShiftFingerGearActuator1 773;
BA_ "SAEDocument" SG_ 2633943038 TransShiftFingerGearActuator1 "J1939-71";
BA_ "SigType" SG_ 2633943038 TransShiftFingerRailActuator1 5;
BA_ "SPN" SG_ 2633943038 TransShiftFingerRailActuator1 772;
BA_ "SAEDocument" SG_ 2633943038 TransShiftFingerRailActuator1 "J1939-71";
BA_ "SigType" SG_ 2633943038 TrnsShftFngerCenterRailIndicator 5;
BA_ "SPN" SG_ 2633943038 TrnsShftFngerCenterRailIndicator 782;
BA_ "SAEDocument" SG_ 2633943038 TrnsShftFngerCenterRailIndicator "J1939-71";
BA_ "SigType" SG_ 2633943038 TrnsShftFngerEngagementIndicator 5;
BA_ "SPN" SG_ 2633943038 TrnsShftFngerEngagementIndicator 781;
BA_ "SAEDocument" SG_ 2633943038 TrnsShftFngerEngagementIndicator "J1939-71";
BA_ "SigType" SG_ 2633943038 TransShiftFingerNeutralIndicator 5;
BA_ "SPN" SG_ 2633943038 TransShiftFingerNeutralIndicator 780;
BA_ "SAEDocument" SG_ 2633943038 TransShiftFingerNeutralIndicator "J1939-71";
BA_ "SigType" SG_ 2633943038 TransShiftFingerRailPos 1;
BA_ "SPN" SG_ 2633943038 TransShiftFingerRailPos 60;
BA_ "SAEDocument" SG_ 2633943038 TransShiftFingerRailPos "J1939-71";
BA_ "SigType" SG_ 2633943038 TransShiftFingerGearPos 1;
BA_ "SPN" SG_ 2633943038 TransShiftFingerGearPos 59;
BA_ "SAEDocument" SG_ 2633943038 TransShiftFingerGearPos "J1939-71";
BA_ "SPN" SG_ 2565867006 TransCurrentRange 163;
BA_ "SAEDocument" SG_ 2565867006 TransCurrentRange "J1939-71";
BA_ "SPN" SG_ 2565867006 TransRequestedRange 162;
BA_ "SAEDocument" SG_ 2565867006 TransRequestedRange "J1939-71";
BA_ "SigType" SG_ 2565867006 TransCurrentGear 1;
BA_ "SPN" SG_ 2565867006 TransCurrentGear 523;
BA_ "SAEDocument" SG_ 2565867006 TransCurrentGear "J1939-71";
BA_ "SigType" SG_ 2565867006 TransActualGearRatio 1;
BA_ "SPN" SG_ 2565867006 TransActualGearRatio 526;
BA_ "SAEDocument" SG_ 2565867006 TransActualGearRatio "J1939-71";
BA_ "SPN" SG_ 2565867006 TransSelectedGear 524;
BA_ "SAEDocument" SG_ 2565867006 TransSelectedGear "J1939-71";
BA_ "SPN" SG_ 2364539646 SrcAddrssOfCntrllngDvcFrTrnsCtrl 1482;
BA_ "SAEDocument" SG_ 2364539646 SrcAddrssOfCntrllngDvcFrTrnsCtrl "J1939-71";
BA_ "SigType" SG_ 2364539646 TransInputShaftSpeed 1;
BA_ "SPN" SG_ 2364539646 TransInputShaftSpeed 161;
BA_ "SAEDocument" SG_ 2364539646 TransInputShaftSpeed "J1939-71";
BA_ "SigType" SG_ 2364539646 MomentaryEngMaxPowerEnable 5;
BA_ "SPN" SG_ 2364539646 MomentaryEngMaxPowerEnable 5015;
BA_ "SAEDocument" SG_ 2364539646 MomentaryEngMaxPowerEnable "J1939-71";
BA_ "SigType" SG_ 2364539646 ProgressiveShiftDisable 5;
BA_ "SPN" SG_ 2364539646 ProgressiveShiftDisable 607;
BA_ "SAEDocument" SG_ 2364539646 ProgressiveShiftDisable "J1939-71";
BA_ "SigType" SG_ 2364539646 EngMomentaryOverspeedEnable 5;
BA_ "SPN" SG_ 2364539646 EngMomentaryOverspeedEnable 606;
BA_ "SAEDocument" SG_ 2364539646 EngMomentaryOverspeedEnable "J1939-71";
BA_ "SigType" SG_ 2364539646 PercentClutchSlip 1;
BA_ "SPN" SG_ 2364539646 PercentClutchSlip 522;
BA_ "SAEDocument" SG_ 2364539646 PercentClutchSlip "J1939-71";
BA_ "SigType" SG_ 2364539646 TransOutputShaftSpeed 1;
BA_ "SPN" SG_ 2364539646 TransOutputShaftSpeed 191;
BA_ "SAEDocument" SG_ 2364539646 TransOutputShaftSpeed "J1939-71";
BA_ "SigType" SG_ 2364539646 TrnsTrqCnvrtrLckpTrnstnInProcess 4;
BA_ "SPN" SG_ 2364539646 TrnsTrqCnvrtrLckpTrnstnInProcess 4816;
BA_ "SAEDocument" SG_ 2364539646 TrnsTrqCnvrtrLckpTrnstnInProcess "J1939-71";
BA_ "SigType" SG_ 2364539646 TransShiftInProcess 4;
BA_ "SPN" SG_ 2364539646 TransShiftInProcess 574;
BA_ "SAEDocument" SG_ 2364539646 TransShiftInProcess "J1939-71";
BA_ "SigType" SG_ 2364539646 TrnsTorqueConverterLockupEngaged 5;
BA_ "SPN" SG_ 2364539646 TrnsTorqueConverterLockupEngaged 573;
BA_ "SAEDocument" SG_ 2364539646 TrnsTorqueConverterLockupEngaged "J1939-71";
BA_ "SigType" SG_ 2364539646 TransDrivelineEngaged 4;
BA_ "SPN" SG_ 2364539646 TransDrivelineEngaged 560;
BA_ "SAEDocument" SG_ 2364539646 TransDrivelineEngaged "J1939-71";
BA_ "SigType" SG_ 2566810110 EngChargeAirCooler1OutletTemp 1;
BA_ "SPN" SG_ 2566810110 EngChargeAirCooler1OutletTemp 2630;
BA_ "SAEDocument" SG_ 2566810110 EngChargeAirCooler1OutletTemp "J1939-71";
BA_ "SigType" SG_ 2566810110 EngIntkVlvActuationSystemOilTemp 1;
BA_ "SPN" SG_ 2566810110 EngIntkVlvActuationSystemOilTemp 2986;
BA_ "SAEDocument" SG_ 2566810110 EngIntkVlvActuationSystemOilTemp "J1939-71";
BA_ "SigType" SG_ 2566810110 EngIntakeManifold1AirTemp 1;
BA_ "SPN" SG_ 2566810110 EngIntakeManifold1AirTemp 1636;
BA_ "SAEDocument" SG_ 2566810110 EngIntakeManifold1AirTemp "J1939-71";
BA_ "SigType" SG_ 2566810110 EngCoolantTemp 1;
BA_ "SPN" SG_ 2566810110 EngCoolantTemp 1637;
BA_ "SAEDocument" SG_ 2566810110 EngCoolantTemp "J1939-71";
BA_ "SigType" SG_ 2566825214 EngExhstGsRcirculation1DiffPress 1;
BA_ "SPN" SG_ 2566825214 EngExhstGsRcirculation1DiffPress 411;
BA_ "SAEDocument" SG_ 2566825214 EngExhstGsRcirculation1DiffPress "J1939-71";
BA_ "SigType" SG_ 2566825214 EngExhaustGasRecirculation1Temp 1;
BA_ "SPN" SG_ 2566825214 EngExhaustGasRecirculation1Temp 412;
BA_ "SAEDocument" SG_ 2566825214 EngExhaustGasRecirculation1Temp "J1939-71";
BA_ "SigType" SG_ 2566825214 EngECUTemp 1;
BA_ "SPN" SG_ 2566825214 EngECUTemp 1136;
BA_ "SAEDocument" SG_ 2566825214 EngECUTemp "J1939-71";
BA_ "SigType" SG_ 2566825214 EngOilTemp2 1;
BA_ "SPN" SG_ 2566825214 EngOilTemp2 1135;
BA_ "SAEDocument" SG_ 2566825214 EngOilTemp2 "J1939-71";
BA_ "SigType" SG_ 2566844158 EngFuelTemp1 1;
BA_ "SPN" SG_ 2566844158 EngFuelTemp1 174;
BA_ "SAEDocument" SG_ 2566844158 EngFuelTemp1 "J1939-71";
BA_ "SigType" SG_ 2566844158 EngIntercoolerThermostatOpening 1;
BA_ "SPN" SG_ 2566844158 EngIntercoolerThermostatOpening 1134;
BA_ "SAEDocument" SG_ 2566844158 EngIntercoolerThermostatOpening "J1939-71";
BA_ "SigType" SG_ 2566844158 EngIntercoolerTemp 1;
BA_ "SPN" SG_ 2566844158 EngIntercoolerTemp 52;
BA_ "SAEDocument" SG_ 2566844158 EngIntercoolerTemp "J1939-71";
BA_ "SigType" SG_ 2566844158 EngTurboOilTemp 1;
BA_ "SPN" SG_ 2566844158 EngTurboOilTemp 176;
BA_ "SAEDocument" SG_ 2566844158 EngTurboOilTemp "J1939-71";
BA_ "SigType" SG_ 2566844158 EngOilTemp1 1;
BA_ "SPN" SG_ 2566844158 EngOilTemp1 175;
BA_ "SAEDocument" SG_ 2566844158 EngOilTemp1 "J1939-71";
BA_ "SigType" SG_ 2566844158 EngCoolantTemp 1;
BA_ "SPN" SG_ 2566844158 EngCoolantTemp 110;
BA_ "SAEDocument" SG_ 2566844158 EngCoolantTemp "J1939-71";
BA_ "SigType" SG_ 2566785022 EngExhaustGasTempLeftManifold 1;
BA_ "SPN" SG_ 2566785022 EngExhaustGasTempLeftManifold 2434;
BA_ "SAEDocument" SG_ 2566785022 EngExhaustGasTempLeftManifold "J1939-71";
BA_ "SigType" SG_ 2566785022 EngExhaustGasTempRightManifold 1;
BA_ "SPN" SG_ 2566785022 EngExhaustGasTempRightManifold 2433;
BA_ "SAEDocument" SG_ 2566785022 EngExhaustGasTempRightManifold "J1939-71";
BA_ "SPN" SG_ 2565868542 TypeOfSteerTrans 2926;
BA_ "SAEDocument" SG_ 2565868542 TypeOfSteerTrans "J1939-71";
BA_ "SPN" SG_ 2565868542 TypeOfSteerForces 2925;
BA_ "SAEDocument" SG_ 2565868542 TypeOfSteerForces "J1939-71";
BA_ "SPN" SG_ 2565868542 SteerType 2924;
BA_ "SAEDocument" SG_ 2565868542 SteerType "J1939-71";
BA_ "SigType" SG_ 2565868542 SteerableLiftAxleLoweringInhibit 5;
BA_ "SPN" SG_ 2565868542 SteerableLiftAxleLoweringInhibit 2922;
BA_ "SAEDocument" SG_ 2565868542 SteerableLiftAxleLoweringInhibit "J1939-71";
BA_ "SPN" SG_ 2565868542 StatusOfSteerAxle 2923;
BA_ "SAEDocument" SG_ 2565868542 StatusOfSteerAxle "J1939-71";
BA_ "SigType" SG_ 2565868542 AxleLocation 1;
BA_ "SPN" SG_ 2565868542 AxleLocation 2928;
BA_ "SAEDocument" SG_ 2565868542 AxleLocation "J1939-71";
BA_ "SigType" SG_ 2565868542 ActualInnerWheelSteerAngle 1;
BA_ "SPN" SG_ 2565868542 ActualInnerWheelSteerAngle 2927;
BA_ "SAEDocument" SG_ 2565868542 ActualInnerWheelSteerAngle "J1939-71";
BA_ "SigType" SG_ 2633941758 TransOutputRetarder 5;
BA_ "SPN" SG_ 2633941758 TransOutputRetarder 748;
BA_ "SAEDocument" SG_ 2633941758 TransOutputRetarder "J1939-71";
BA_ "SigType" SG_ 2565865726 ActlMxAvlblRetarderPercentTorque 1;
BA_ "SPN" SG_ 2565865726 ActlMxAvlblRetarderPercentTorque 1717;
BA_ "SAEDocument" SG_ 2565865726 ActlMxAvlblRetarderPercentTorque "J1939-71";
BA_ "SigType" SG_ 2565865726 RetarderSelectionNonengine 1;
BA_ "SPN" SG_ 2565865726 RetarderSelectionNonengine 1716;
BA_ "SAEDocument" SG_ 2565865726 RetarderSelectionNonengine "J1939-71";
BA_ "SPN" SG_ 2565865726 DrvrsDemandRetarderPercentTorque 1715;
BA_ "SAEDocument" SG_ 2565865726 DrvrsDemandRetarderPercentTorque "J1939-71";
BA_ "SPN" SG_ 2565865726 SrcAddrssOfCntrllngDvcFrRtrdrCtr 1480;
BA_ "SAEDocument" SG_ 2565865726 SrcAddrssOfCntrllngDvcFrRtrdrCtr "J1939-71";
BA_ "SigType" SG_ 2565865726 RetarderRoadSpeedExceededStatus 5;
BA_ "SPN" SG_ 2565865726 RetarderRoadSpeedExceededStatus 4234;
BA_ "SAEDocument" SG_ 2565865726 RetarderRoadSpeedExceededStatus "J1939-71";
BA_ "SigType" SG_ 2565865726 RetarderRoadSpeedLimitSwitch 4;
BA_ "SPN" SG_ 2565865726 RetarderRoadSpeedLimitSwitch 4233;
BA_ "SAEDocument" SG_ 2565865726 RetarderRoadSpeedLimitSwitch "J1939-71";
BA_ "SigType" SG_ 2565865726 RetarderRequestingBrakeLight 5;
BA_ "SPN" SG_ 2565865726 RetarderRequestingBrakeLight 1667;
BA_ "SAEDocument" SG_ 2565865726 RetarderRequestingBrakeLight "J1939-71";
BA_ "SigType" SG_ 2565865726 EngCoolantLoadIncrease 5;
BA_ "SPN" SG_ 2565865726 EngCoolantLoadIncrease 1082;
BA_ "SAEDocument" SG_ 2565865726 EngCoolantLoadIncrease "J1939-71";
BA_ "SPN" SG_ 2565865726 IntendedRetarderPercentTorque 1085;
BA_ "SAEDocument" SG_ 2565865726 IntendedRetarderPercentTorque "J1939-71";
BA_ "SigType" SG_ 2565865726 ActualRetarderPercentTorque 1;
BA_ "SPN" SG_ 2565865726 ActualRetarderPercentTorque 520;
BA_ "SAEDocument" SG_ 2565865726 ActualRetarderPercentTorque "J1939-71";
BA_ "SigType" SG_ 2565865726 RetarderEnableShiftAssistSwitch 4;
BA_ "SPN" SG_ 2565865726 RetarderEnableShiftAssistSwitch 572;
BA_ "SAEDocument" SG_ 2565865726 RetarderEnableShiftAssistSwitch "J1939-71";
BA_ "SigType" SG_ 2565865726 RetarderEnableBrakeAssistSwitch 4;
BA_ "SPN" SG_ 2565865726 RetarderEnableBrakeAssistSwitch 571;
BA_ "SAEDocument" SG_ 2565865726 RetarderEnableBrakeAssistSwitch "J1939-71";
BA_ "SPN" SG_ 2565865726 RetarderTorqueMode 900;
BA_ "SAEDocument" SG_ 2565865726 RetarderTorqueMode "J1939-71";
BA_ "SigType" SG_ 2633932798 EngExhaustGasPort20Temp 1;
BA_ "SPN" SG_ 2633932798 EngExhaustGasPort20Temp 1156;
BA_ "SAEDocument" SG_ 2633932798 EngExhaustGasPort20Temp "J1939-71";
BA_ "SigType" SG_ 2633932798 EngExhaustGasPort19Temp 1;
BA_ "SPN" SG_ 2633932798 EngExhaustGasPort19Temp 1155;
BA_ "SAEDocument" SG_ 2633932798 EngExhaustGasPort19Temp "J1939-71";
BA_ "SigType" SG_ 2633932798 EngExhaustGasPort18Temp 1;
BA_ "SPN" SG_ 2633932798 EngExhaustGasPort18Temp 1154;
BA_ "SAEDocument" SG_ 2633932798 EngExhaustGasPort18Temp "J1939-71";
BA_ "SigType" SG_ 2633932798 EngExhaustGasPort17Temp 1;
BA_ "SPN" SG_ 2633932798 EngExhaustGasPort17Temp 1153;
BA_ "SAEDocument" SG_ 2633932798 EngExhaustGasPort17Temp "J1939-71";
BA_ "SigType" SG_ 2566824190 EngExhaustGasPort16Temp 1;
BA_ "SPN" SG_ 2566824190 EngExhaustGasPort16Temp 1152;
BA_ "SAEDocument" SG_ 2566824190 EngExhaustGasPort16Temp "J1939-71";
BA_ "SigType" SG_ 2566824190 EngExhaustGasPort15Temp 1;
BA_ "SPN" SG_ 2566824190 EngExhaustGasPort15Temp 1151;
BA_ "SAEDocument" SG_ 2566824190 EngExhaustGasPort15Temp "J1939-71";
BA_ "SigType" SG_ 2566824190 EngExhaustGasPort14Temp 1;
BA_ "SPN" SG_ 2566824190 EngExhaustGasPort14Temp 1150;
BA_ "SAEDocument" SG_ 2566824190 EngExhaustGasPort14Temp "J1939-71";
BA_ "SigType" SG_ 2566824190 EngExhaustGasPort13Temp 1;
BA_ "SPN" SG_ 2566824190 EngExhaustGasPort13Temp 1149;
BA_ "SAEDocument" SG_ 2566824190 EngExhaustGasPort13Temp "J1939-71";
BA_ "SigType" SG_ 2633933310 EngExhaustGasPort12Temp 1;
BA_ "SPN" SG_ 2633933310 EngExhaustGasPort12Temp 1148;
BA_ "SAEDocument" SG_ 2633933310 EngExhaustGasPort12Temp "J1939-71";
BA_ "SigType" SG_ 2633933310 EngExhaustGasPort11Temp 1;
BA_ "SPN" SG_ 2633933310 EngExhaustGasPort11Temp 1147;
BA_ "SAEDocument" SG_ 2633933310 EngExhaustGasPort11Temp "J1939-71";
BA_ "SigType" SG_ 2633933310 EngExhaustGasPort10Temp 1;
BA_ "SPN" SG_ 2633933310 EngExhaustGasPort10Temp 1146;
BA_ "SAEDocument" SG_ 2633933310 EngExhaustGasPort10Temp "J1939-71";
BA_ "SigType" SG_ 2633933310 EngExhaustGasPort9Temp 1;
BA_ "SPN" SG_ 2633933310 EngExhaustGasPort9Temp 1145;
BA_ "SAEDocument" SG_ 2633933310 EngExhaustGasPort9Temp "J1939-71";
BA_ "SigType" SG_ 2633933566 EngExhaustGasPort8Temp 1;
BA_ "SPN" SG_ 2633933566 EngExhaustGasPort8Temp 1144;
BA_ "SAEDocument" SG_ 2633933566 EngExhaustGasPort8Temp "J1939-71";
BA_ "SigType" SG_ 2633933566 EngExhaustGasPort7Temp 1;
BA_ "SPN" SG_ 2633933566 EngExhaustGasPort7Temp 1143;
BA_ "SAEDocument" SG_ 2633933566 EngExhaustGasPort7Temp "J1939-71";
BA_ "SigType" SG_ 2633933566 EngExhaustGasPort6Temp 1;
BA_ "SPN" SG_ 2633933566 EngExhaustGasPort6Temp 1142;
BA_ "SAEDocument" SG_ 2633933566 EngExhaustGasPort6Temp "J1939-71";
BA_ "SigType" SG_ 2633933566 EngExhaustGasPort5Temp 1;
BA_ "SPN" SG_ 2633933566 EngExhaustGasPort5Temp 1141;
BA_ "SAEDocument" SG_ 2633933566 EngExhaustGasPort5Temp "J1939-71";
BA_ "SigType" SG_ 2633933822 EngExhaustGasPort4Temp 1;
BA_ "SPN" SG_ 2633933822 EngExhaustGasPort4Temp 1140;
BA_ "SAEDocument" SG_ 2633933822 EngExhaustGasPort4Temp "J1939-71";
BA_ "SigType" SG_ 2633933822 EngExhaustGasPort3Temp 1;
BA_ "SPN" SG_ 2633933822 EngExhaustGasPort3Temp 1139;
BA_ "SAEDocument" SG_ 2633933822 EngExhaustGasPort3Temp "J1939-71";
BA_ "SigType" SG_ 2633933822 EngExhaustGasPort2Temp 1;
BA_ "SPN" SG_ 2633933822 EngExhaustGasPort2Temp 1138;
BA_ "SAEDocument" SG_ 2633933822 EngExhaustGasPort2Temp "J1939-71";
BA_ "SigType" SG_ 2633933822 EngExhaustGasPort1Temp 1;
BA_ "SPN" SG_ 2633933822 EngExhaustGasPort1Temp 1137;
BA_ "SAEDocument" SG_ 2633933822 EngExhaustGasPort1Temp "J1939-71";
BA_ "SigType" SG_ 2566776062 PayloadPercentage 1;
BA_ "SPN" SG_ 2566776062 PayloadPercentage 2600;
BA_ "SAEDocument" SG_ 2566776062 PayloadPercentage "J1939-71";
BA_ "SigType" SG_ 2566771454 DataMemoryUsage 1;
BA_ "SPN" SG_ 2566771454 DataMemoryUsage 2802;
BA_ "SAEDocument" SG_ 2566771454 DataMemoryUsage "J1939-71";
BA_ "SigType" SG_ 2566771454 KeepAliveBatteryConsumption 1;
BA_ "SPN" SG_ 2566771454 KeepAliveBatteryConsumption 2803;
BA_ "SAEDocument" SG_ 2566771454 KeepAliveBatteryConsumption "J1939-71";
BA_ "SigType" SG_ 2566775806 TravelVelocityCtrlPos 1;
BA_ "SPN" SG_ 2566775806 TravelVelocityCtrlPos 2601;
BA_ "SAEDocument" SG_ 2566775806 TravelVelocityCtrlPos "J1939-71";
BA_ "SigType" SG_ 2633935358 EngExhstGsOxygnSnsrClsdLpOprtion 5;
BA_ "SPN" SG_ 2633935358 EngExhstGsOxygnSnsrClsdLpOprtion 1696;
BA_ "SAEDocument" SG_ 2633935358 EngExhstGsOxygnSnsrClsdLpOprtion "J1939-71";
BA_ "SPN" SG_ 2633935358 EngExhstGsOxygnSnsrFlngCrrection 1695;
BA_ "SAEDocument" SG_ 2633935358 EngExhstGsOxygnSnsrFlngCrrection "J1939-71";
BA_ "SigType" SG_ 2633935358 EngActualExhaustOxygen 1;
BA_ "SPN" SG_ 2633935358 EngActualExhaustOxygen 1119;
BA_ "SAEDocument" SG_ 2633935358 EngActualExhaustOxygen "J1939-71";
BA_ "SigType" SG_ 2633935358 EngDesiredExhaustOxygen 1;
BA_ "SPN" SG_ 2633935358 EngDesiredExhaustOxygen 1118;
BA_ "SAEDocument" SG_ 2633935358 EngDesiredExhaustOxygen "J1939-71";
BA_ "SigType" SG_ 2633935358 EngDesiredRatedExhaustOxygen 1;
BA_ "SPN" SG_ 2633935358 EngDesiredRatedExhaustOxygen 1117;
BA_ "SAEDocument" SG_ 2633935358 EngDesiredRatedExhaustOxygen "J1939-71";
BA_ "SigType" SG_ 2365447166 Jystick3GripXAxisDetentPosStatus 4;
BA_ "SPN" SG_ 2365447166 Jystick3GripXAxisDetentPosStatus 2756;
BA_ "SAEDocument" SG_ 2365447166 Jystick3GripXAxisDetentPosStatus "J1939-71";
BA_ "SigType" SG_ 2365447166 Jystick3GripYAxisDetentPosStatus 4;
BA_ "SPN" SG_ 2365447166 Jystick3GripYAxisDetentPosStatus 2757;
BA_ "SAEDocument" SG_ 2365447166 Jystick3GripYAxisDetentPosStatus "J1939-71";
BA_ "SigType" SG_ 2365447166 Jystick3ThetaAxisDetentPosStatus 4;
BA_ "SPN" SG_ 2365447166 Jystick3ThetaAxisDetentPosStatus 2758;
BA_ "SAEDocument" SG_ 2365447166 Jystick3ThetaAxisDetentPosStatus "J1939-71";
BA_ "SPN" SG_ 2365447166 Joystick3ThetaAxisPos 2738;
BA_ "SAEDocument" SG_ 2365447166 Joystick3ThetaAxisPos "J1939-71";
BA_ "SigType" SG_ 2365447166 Jystck3ThtAxsClckwsPstvPosStatus 4;
BA_ "SPN" SG_ 2365447166 Jystck3ThtAxsClckwsPstvPosStatus 2743;
BA_ "SAEDocument" SG_ 2365447166 Jystck3ThtAxsClckwsPstvPosStatus "J1939-71";
BA_ "SigType" SG_ 2365447166 Jystck3ThetaAxisNeutralPosStatus 4;
BA_ "SPN" SG_ 2365447166 Jystck3ThetaAxisNeutralPosStatus 2753;
BA_ "SAEDocument" SG_ 2365447166 Jystck3ThetaAxisNeutralPosStatus "J1939-71";
BA_ "SPN" SG_ 2365447166 Joystick3GripYAxisPos 2737;
BA_ "SAEDocument" SG_ 2365447166 Joystick3GripYAxisPos "J1939-71";
BA_ "SigType" SG_ 2365447166 Jystck3GrpYAxsLvrFrwrdPstvPsStts 4;
BA_ "SPN" SG_ 2365447166 Jystck3GrpYAxsLvrFrwrdPstvPsStts 2742;
BA_ "SAEDocument" SG_ 2365447166 Jystck3GrpYAxsLvrFrwrdPstvPsStts "J1939-71";
BA_ "SigType" SG_ 2365447166 Jystck3GrpYAxsLvrBckNgtvPsStatus 4;
BA_ "SPN" SG_ 2365447166 Jystck3GrpYAxsLvrBckNgtvPsStatus 2747;
BA_ "SAEDocument" SG_ 2365447166 Jystck3GrpYAxsLvrBckNgtvPsStatus "J1939-71";
BA_ "SigType" SG_ 2365447166 Jystck3GripYAxisNeutralPosStatus 4;
BA_ "SPN" SG_ 2365447166 Jystck3GripYAxisNeutralPosStatus 2752;
BA_ "SAEDocument" SG_ 2365447166 Jystck3GripYAxisNeutralPosStatus "J1939-71";
BA_ "SPN" SG_ 2365447166 Joystick3GripXAxisPos 2736;
BA_ "SAEDocument" SG_ 2365447166 Joystick3GripXAxisPos "J1939-71";
BA_ "SigType" SG_ 2365447166 Jystck3GrpXAxsLvrRghtPstvPsSttus 4;
BA_ "SPN" SG_ 2365447166 Jystck3GrpXAxsLvrRghtPstvPsSttus 2741;
BA_ "SAEDocument" SG_ 2365447166 Jystck3GrpXAxsLvrRghtPstvPsSttus "J1939-71";
BA_ "SigType" SG_ 2365447166 Jystck3GrpXAxsLvrLftNgtvPsStatus 4;
BA_ "SPN" SG_ 2365447166 Jystck3GrpXAxsLvrLftNgtvPsStatus 2746;
BA_ "SAEDocument" SG_ 2365447166 Jystck3GrpXAxsLvrLftNgtvPsStatus "J1939-71";
BA_ "SigType" SG_ 2365447166 Jystck3GripXAxisNeutralPosStatus 4;
BA_ "SPN" SG_ 2365447166 Jystck3GripXAxisNeutralPosStatus 2751;
BA_ "SAEDocument" SG_ 2365447166 Jystck3GripXAxisNeutralPosStatus "J1939-71";
BA_ "SigType" SG_ 2365447166 Jystck3ThtAxsCntrClckwsNgtvPsStt 4;
BA_ "SPN" SG_ 2365447166 Jystck3ThtAxsCntrClckwsNgtvPsStt 2748;
BA_ "SAEDocument" SG_ 2365447166 Jystck3ThtAxsCntrClckwsNgtvPsStt "J1939-71";
BA_ "SigType" SG_ 2365446654 Jystick2GripXAxisDetentPosStatus 4;
BA_ "SPN" SG_ 2365446654 Jystick2GripXAxisDetentPosStatus 2719;
BA_ "SAEDocument" SG_ 2365446654 Jystick2GripXAxisDetentPosStatus "J1939-71";
BA_ "SigType" SG_ 2365446654 Jystick2GripYAxisDetentPosStatus 4;
BA_ "SPN" SG_ 2365446654 Jystick2GripYAxisDetentPosStatus 2720;
BA_ "SAEDocument" SG_ 2365446654 Jystick2GripYAxisDetentPosStatus "J1939-71";
BA_ "SigType" SG_ 2365446654 Jystick2ThetaAxisDetentPosStatus 4;
BA_ "SPN" SG_ 2365446654 Jystick2ThetaAxisDetentPosStatus 2721;
BA_ "SAEDocument" SG_ 2365446654 Jystick2ThetaAxisDetentPosStatus "J1939-71";
BA_ "SPN" SG_ 2365446654 Joystick2ThetaAxisPos 2701;
BA_ "SAEDocument" SG_ 2365446654 Joystick2ThetaAxisPos "J1939-71";
BA_ "SigType" SG_ 2365446654 Jystck2ThtAxsClckwsPstvPosStatus 4;
BA_ "SPN" SG_ 2365446654 Jystck2ThtAxsClckwsPstvPosStatus 2706;
BA_ "SAEDocument" SG_ 2365446654 Jystck2ThtAxsClckwsPstvPosStatus "J1939-71";
BA_ "SigType" SG_ 2365446654 Jystck2ThetaAxisNeutralPosStatus 4;
BA_ "SPN" SG_ 2365446654 Jystck2ThetaAxisNeutralPosStatus 2716;
BA_ "SAEDocument" SG_ 2365446654 Jystck2ThetaAxisNeutralPosStatus "J1939-71";
BA_ "SPN" SG_ 2365446654 Joystick2GripYAxisPos 2700;
BA_ "SAEDocument" SG_ 2365446654 Joystick2GripYAxisPos "J1939-71";
BA_ "SigType" SG_ 2365446654 Jystck2GrpYAxsLvrFrwrdPstvPsStts 4;
BA_ "SPN" SG_ 2365446654 Jystck2GrpYAxsLvrFrwrdPstvPsStts 2705;
BA_ "SAEDocument" SG_ 2365446654 Jystck2GrpYAxsLvrFrwrdPstvPsStts "J1939-71";
BA_ "SigType" SG_ 2365446654 Jystck2GrpYAxsLvrBckNgtvPsStatus 4;
BA_ "SPN" SG_ 2365446654 Jystck2GrpYAxsLvrBckNgtvPsStatus 2710;
BA_ "SAEDocument" SG_ 2365446654 Jystck2GrpYAxsLvrBckNgtvPsStatus "J1939-71";
BA_ "SigType" SG_ 2365446654 Jystck2GripYAxisNeutralPosStatus 4;
BA_ "SPN" SG_ 2365446654 Jystck2GripYAxisNeutralPosStatus 2715;
BA_ "SAEDocument" SG_ 2365446654 Jystck2GripYAxisNeutralPosStatus "J1939-71";
BA_ "SPN" SG_ 2365446654 Joystick2GripXAxisPos 2699;
BA_ "SAEDocument" SG_ 2365446654 Joystick2GripXAxisPos "J1939-71";
BA_ "SigType" SG_ 2365446654 Jystck2GrpXAxsLvrRghtPstvPsSttus 4;
BA_ "SPN" SG_ 2365446654 Jystck2GrpXAxsLvrRghtPstvPsSttus 2704;
BA_ "SAEDocument" SG_ 2365446654 Jystck2GrpXAxsLvrRghtPstvPsSttus "J1939-71";
BA_ "SigType" SG_ 2365446654 Jystck2GrpXAxsLvrLftNgtvPsStatus 4;
BA_ "SPN" SG_ 2365446654 Jystck2GrpXAxsLvrLftNgtvPsStatus 2709;
BA_ "SAEDocument" SG_ 2365446654 Jystck2GrpXAxsLvrLftNgtvPsStatus "J1939-71";
BA_ "SigType" SG_ 2365446654 Jystck2GripXAxisNeutralPosStatus 4;
BA_ "SPN" SG_ 2365446654 Jystck2GripXAxisNeutralPosStatus 2714;
BA_ "SAEDocument" SG_ 2365446654 Jystck2GripXAxisNeutralPosStatus "J1939-71";
BA_ "SigType" SG_ 2365446654 Jystck2ThtAxsCntrClckwsNgtvPsStt 4;
BA_ "SPN" SG_ 2365446654 Jystck2ThtAxsCntrClckwsNgtvPsStt 2711;
BA_ "SAEDocument" SG_ 2365446654 Jystck2ThtAxsCntrClckwsNgtvPsStt "J1939-71";
BA_ "SigType" SG_ 2365446142 Jystick1GripXAxisDetentPosStatus 4;
BA_ "SPN" SG_ 2365446142 Jystick1GripXAxisDetentPosStatus 2682;
BA_ "SAEDocument" SG_ 2365446142 Jystick1GripXAxisDetentPosStatus "J1939-71";
BA_ "SigType" SG_ 2365446142 Jystick1GripYAxisDetentPosStatus 4;
BA_ "SPN" SG_ 2365446142 Jystick1GripYAxisDetentPosStatus 2683;
BA_ "SAEDocument" SG_ 2365446142 Jystick1GripYAxisDetentPosStatus "J1939-71";
BA_ "SigType" SG_ 2365446142 Jystick1ThetaAxisDetentPosStatus 4;
BA_ "SPN" SG_ 2365446142 Jystick1ThetaAxisDetentPosStatus 2684;
BA_ "SAEDocument" SG_ 2365446142 Jystick1ThetaAxisDetentPosStatus "J1939-71";
BA_ "SPN" SG_ 2365446142 Joystick1ThetaAxisPos 2664;
BA_ "SAEDocument" SG_ 2365446142 Joystick1ThetaAxisPos "J1939-71";
BA_ "SigType" SG_ 2365446142 Jystck1ThtAxsClckwsPstvPosStatus 4;
BA_ "SPN" SG_ 2365446142 Jystck1ThtAxsClckwsPstvPosStatus 2669;
BA_ "SAEDocument" SG_ 2365446142 Jystck1ThtAxsClckwsPstvPosStatus "J1939-71";
BA_ "SigType" SG_ 2365446142 Jystck1ThetaAxisNeutralPosStatus 4;
BA_ "SPN" SG_ 2365446142 Jystck1ThetaAxisNeutralPosStatus 2679;
BA_ "SAEDocument" SG_ 2365446142 Jystck1ThetaAxisNeutralPosStatus "J1939-71";
BA_ "SPN" SG_ 2365446142 Joystick1GripYAxisPos 2663;
BA_ "SAEDocument" SG_ 2365446142 Joystick1GripYAxisPos "J1939-71";
BA_ "SigType" SG_ 2365446142 Jystck1GrpYAxsLvrFrwrdPstvPsStts 4;
BA_ "SPN" SG_ 2365446142 Jystck1GrpYAxsLvrFrwrdPstvPsStts 2668;
BA_ "SAEDocument" SG_ 2365446142 Jystck1GrpYAxsLvrFrwrdPstvPsStts "J1939-71";
BA_ "SigType" SG_ 2365446142 Jystck1GrpYAxsLvrBckNgtvPsStatus 4;
BA_ "SPN" SG_ 2365446142 Jystck1GrpYAxsLvrBckNgtvPsStatus 2673;
BA_ "SAEDocument" SG_ 2365446142 Jystck1GrpYAxsLvrBckNgtvPsStatus "J1939-71";
BA_ "SigType" SG_ 2365446142 Jystck1GripYAxisNeutralPosStatus 4;
BA_ "SPN" SG_ 2365446142 Jystck1GripYAxisNeutralPosStatus 2678;
BA_ "SAEDocument" SG_ 2365446142 Jystck1GripYAxisNeutralPosStatus "J1939-71";
BA_ "SPN" SG_ 2365446142 Joystick1GripXAxisPos 2662;
BA_ "SAEDocument" SG_ 2365446142 Joystick1GripXAxisPos "J1939-71";
BA_ "SigType" SG_ 2365446142 Jystck1GrpXAxsLvrRghtPstvPsSttus 4;
BA_ "SPN" SG_ 2365446142 Jystck1GrpXAxsLvrRghtPstvPsSttus 2667;
BA_ "SAEDocument" SG_ 2365446142 Jystck1GrpXAxsLvrRghtPstvPsSttus "J1939-71";
BA_ "SigType" SG_ 2365446142 Jystck1GrpXAxsLvrLftNgtvPsStatus 4;
BA_ "SPN" SG_ 2365446142 Jystck1GrpXAxsLvrLftNgtvPsStatus 2672;
BA_ "SAEDocument" SG_ 2365446142 Jystck1GrpXAxsLvrLftNgtvPsStatus "J1939-71";
BA_ "SigType" SG_ 2365446142 Jystck1GripXAxisNeutralPosStatus 4;
BA_ "SPN" SG_ 2365446142 Jystck1GripXAxisNeutralPosStatus 2677;
BA_ "SAEDocument" SG_ 2365446142 Jystck1GripXAxisNeutralPosStatus "J1939-71";
BA_ "SigType" SG_ 2365446142 Jystck1ThtAxsCntrClckwsNgtvPsStt 4;
BA_ "SPN" SG_ 2365446142 Jystck1ThtAxsCntrClckwsNgtvPsStt 2674;
BA_ "SAEDocument" SG_ 2365446142 Jystck1ThtAxsCntrClckwsNgtvPsStt "J1939-71";
BA_ "SigType" SG_ 2633929470 EngFuelRackPos 1;
BA_ "SPN" SG_ 2633929470 EngFuelRackPos 1210;
BA_ "SAEDocument" SG_ 2633929470 EngFuelRackPos "J1939-71";
BA_ "SigType" SG_ 2633929470 EngGasMassFlowRate1 1;
BA_ "SPN" SG_ 2633929470 EngGasMassFlowRate1 1241;
BA_ "SAEDocument" SG_ 2633929470 EngGasMassFlowRate1 "J1939-71";
BA_ "SigType" SG_ 2633929470 InstantaneousEstBrakePower 1;
BA_ "SPN" SG_ 2633929470 InstantaneousEstBrakePower 1242;
BA_ "SAEDocument" SG_ 2633929470 InstantaneousEstBrakePower "J1939-71";
BA_ "SigType" SG_ 2633929470 EngExhaustGasPress 1;
BA_ "SPN" SG_ 2633929470 EngExhaustGasPress 1209;
BA_ "SAEDocument" SG_ 2633929470 EngExhaustGasPress "J1939-71";
BA_ "SigType" SG_ 2633929470 EngPrefilterOilPress 1;
BA_ "SPN" SG_ 2633929470 EngPrefilterOilPress 1208;
BA_ "SAEDocument" SG_ 2633929470 EngPrefilterOilPress "J1939-71";
BA_ "SigType" SG_ 2633937406 TotalECURunTime 1;
BA_ "SPN" SG_ 2633937406 TotalECURunTime 1033;
BA_ "SAEDocument" SG_ 2633937406 TotalECURunTime "J1939-71";
BA_ "SigType" SG_ 2633937406 TotalECUDistance 1;
BA_ "SPN" SG_ 2633937406 TotalECUDistance 1032;
BA_ "SAEDocument" SG_ 2633937406 TotalECUDistance "J1939-71";
BA_ "SigType" SG_ 2364541694 EngExhstGsRcrcltion2MassFlowRate 1;
BA_ "SPN" SG_ 2364541694 EngExhstGsRcrcltion2MassFlowRate 5257;
BA_ "SAEDocument" SG_ 2364541694 EngExhstGsRcrcltion2MassFlowRate "J1939-71";
BA_ "SigType" SG_ 2364541694 EngIntakeAirMassFlowRate 1;
BA_ "SPN" SG_ 2364541694 EngIntakeAirMassFlowRate 132;
BA_ "SAEDocument" SG_ 2364541694 EngIntakeAirMassFlowRate "J1939-71";
BA_ "SigType" SG_ 2364541694 EngExhstGsRcrcltion1MassFlowRate 1;
BA_ "SPN" SG_ 2364541694 EngExhstGsRcrcltion1MassFlowRate 2659;
BA_ "SAEDocument" SG_ 2364541694 EngExhstGsRcrcltion1MassFlowRate "J1939-71";
BA_ "SigType" SG_ 2566810366 FuelPumpPrimerStatus 5;
BA_ "SPN" SG_ 2566810366 FuelPumpPrimerStatus 4083;
BA_ "SAEDocument" SG_ 2566810366 FuelPumpPrimerStatus "J1939-71";
BA_ "SPN" SG_ 2566810366 EngVentilationStatus 3554;
BA_ "SAEDocument" SG_ 2566810366 EngVentilationStatus "J1939-71";
BA_ "SigType" SG_ 2566810366 EngCoolantPreheatedState 5;
BA_ "SPN" SG_ 2566810366 EngCoolantPreheatedState 3553;
BA_ "SAEDocument" SG_ 2566810366 EngCoolantPreheatedState "J1939-71";
BA_ "SigType" SG_ 2566810366 EngOilPreHeatedState 5;
BA_ "SPN" SG_ 2566810366 EngOilPreHeatedState 3552;
BA_ "SAEDocument" SG_ 2566810366 EngOilPreHeatedState "J1939-71";
BA_ "SigType" SG_ 2566810366 EngOilPrimingState 5;
BA_ "SPN" SG_ 2566810366 EngOilPrimingState 3551;
BA_ "SAEDocument" SG_ 2566810366 EngOilPrimingState "J1939-71";
BA_ "SigType" SG_ 2566810366 EngOilPrimingPumpSwitch 4;
BA_ "SPN" SG_ 2566810366 EngOilPrimingPumpSwitch 3550;
BA_ "SAEDocument" SG_ 2566810366 EngOilPrimingPumpSwitch "J1939-71";
BA_ "SigType" SG_ 2566810366 EngOilFilterOutletPress 1;
BA_ "SPN" SG_ 2566810366 EngOilFilterOutletPress 3549;
BA_ "SAEDocument" SG_ 2566810366 EngOilFilterOutletPress "J1939-71";
BA_ "SigType" SG_ 2566810366 EngWasteOilReservoirLevel 1;
BA_ "SPN" SG_ 2566810366 EngWasteOilReservoirLevel 3548;
BA_ "SAEDocument" SG_ 2566810366 EngWasteOilReservoirLevel "J1939-71";
BA_ "SigType" SG_ 2566810366 EngFuelFilterDiffPress 1;
BA_ "SPN" SG_ 2566810366 EngFuelFilterDiffPress 1382;
BA_ "SAEDocument" SG_ 2566810366 EngFuelFilterDiffPress "J1939-71";
BA_ "SigType" SG_ 2566810366 EngFuelSupplyPumpIntakePress 1;
BA_ "SPN" SG_ 2566810366 EngFuelSupplyPumpIntakePress 1381;
BA_ "SAEDocument" SG_ 2566810366 EngFuelSupplyPumpIntakePress "J1939-71";
BA_ "SigType" SG_ 2566810366 EngOilLevelRemoteReservoir 1;
BA_ "SPN" SG_ 2566810366 EngOilLevelRemoteReservoir 1380;
BA_ "SAEDocument" SG_ 2566810366 EngOilLevelRemoteReservoir "J1939-71";
BA_ "SigType" SG_ 2566767102 EngExhstGsRcrclation1OutletPress 1;
BA_ "SPN" SG_ 2566767102 EngExhstGsRcrclation1OutletPress 5019;
BA_ "SAEDocument" SG_ 2566767102 EngExhstGsRcrclation1OutletPress "J1939-71";
BA_ "SigType" SG_ 2566767102 EngExhstVlvActtionSystemOilPress 1;
BA_ "SPN" SG_ 2566767102 EngExhstVlvActtionSystemOilPress 4287;
BA_ "SAEDocument" SG_ 2566767102 EngExhstVlvActtionSystemOilPress "J1939-71";
BA_ "SigType" SG_ 2566767102 EngExhstGsRcrclation1IntakePress 1;
BA_ "SPN" SG_ 2566767102 EngExhstGsRcrclation1IntakePress 3358;
BA_ "SAEDocument" SG_ 2566767102 EngExhstGsRcrclation1IntakePress "J1939-71";
BA_ "SigType" SG_ 2566767102 EngIntkVlvActationSystemOilPress 1;
BA_ "SPN" SG_ 2566767102 EngIntkVlvActationSystemOilPress 2948;
BA_ "SAEDocument" SG_ 2566767102 EngIntkVlvActationSystemOilPress "J1939-71";
BA_ "SigType" SG_ 2566839294 EngInjectorMeteringRail2Press 1;
BA_ "SPN" SG_ 2566839294 EngInjectorMeteringRail2Press 1349;
BA_ "SAEDocument" SG_ 2566839294 EngInjectorMeteringRail2Press "J1939-71";
BA_ "SigType" SG_ 2566839294 EngInjectorTimingRail1Press 1;
BA_ "SPN" SG_ 2566839294 EngInjectorTimingRail1Press 156;
BA_ "SAEDocument" SG_ 2566839294 EngInjectorTimingRail1Press "J1939-71";
BA_ "SigType" SG_ 2566839294 EngInjectorMeteringRail1Press 1;
BA_ "SPN" SG_ 2566839294 EngInjectorMeteringRail1Press 157;
BA_ "SAEDocument" SG_ 2566839294 EngInjectorMeteringRail1Press "J1939-71";
BA_ "SigType" SG_ 2566839294 EngInjectionCtrlPress 1;
BA_ "SPN" SG_ 2566839294 EngInjectionCtrlPress 164;
BA_ "SAEDocument" SG_ 2566839294 EngInjectionCtrlPress "J1939-71";
BA_ "SigType" SG_ 2566844414 EngCoolantLevel 1;
BA_ "SPN" SG_ 2566844414 EngCoolantLevel 111;
BA_ "SAEDocument" SG_ 2566844414 EngCoolantLevel "J1939-71";
BA_ "SigType" SG_ 2566844414 EngCoolantPress 1;
BA_ "SPN" SG_ 2566844414 EngCoolantPress 109;
BA_ "SAEDocument" SG_ 2566844414 EngCoolantPress "J1939-71";
BA_ "SigType" SG_ 2566844414 EngCrankcasePress 1;
BA_ "SPN" SG_ 2566844414 EngCrankcasePress 101;
BA_ "SAEDocument" SG_ 2566844414 EngCrankcasePress "J1939-71";
BA_ "SigType" SG_ 2566844414 EngOilPress 1;
BA_ "SPN" SG_ 2566844414 EngOilPress 100;
BA_ "SAEDocument" SG_ 2566844414 EngOilPress "J1939-71";
BA_ "SigType" SG_ 2566844414 EngOilLevel 1;
BA_ "SPN" SG_ 2566844414 EngOilLevel 98;
BA_ "SAEDocument" SG_ 2566844414 EngOilLevel "J1939-71";
BA_ "SigType" SG_ 2566844414 EngExCrankcaseBlowbyPress 1;
BA_ "SPN" SG_ 2566844414 EngExCrankcaseBlowbyPress 22;
BA_ "SAEDocument" SG_ 2566844414 EngExCrankcaseBlowbyPress "J1939-71";
BA_ "SigType" SG_ 2566844414 EngFuelDeliveryPress 1;
BA_ "SPN" SG_ 2566844414 EngFuelDeliveryPress 94;
BA_ "SAEDocument" SG_ 2566844414 EngFuelDeliveryPress "J1939-71";
BA_ "SigType" SG_ 2633929726 SafetyWireStatus 5;
BA_ "SPN" SG_ 2633929726 SafetyWireStatus 1205;
BA_ "SAEDocument" SG_ 2633929726 SafetyWireStatus "J1939-71";
BA_ "SigType" SG_ 2633929726 ElectricalLoad 1;
BA_ "SPN" SG_ 2633929726 ElectricalLoad 1204;
BA_ "SAEDocument" SG_ 2633929726 ElectricalLoad "J1939-71";
BA_ "SigType" SG_ 2566772222 EngVriableGeometryTurbo1CtrlMode 5;
BA_ "SPN" SG_ 2566772222 EngVriableGeometryTurbo1CtrlMode 5457;
BA_ "SAEDocument" SG_ 2566772222 EngVriableGeometryTurbo1CtrlMode "J1939-71";
BA_ "SPN" SG_ 2566772222 EngTrb1ClclatedTurbineIntakeTemp 2789;
BA_ "SAEDocument" SG_ 2566772222 EngTrb1ClclatedTurbineIntakeTemp "J1939-71";
BA_ "SPN" SG_ 2566772222 EngExhstGsRcirculation1ValveCtrl 2791;
BA_ "SAEDocument" SG_ 2566772222 EngExhstGsRcirculation1ValveCtrl "J1939-71";
BA_ "SigType" SG_ 2566772222 EngVrblGeometryTurbo1ActuatorPos 1;
BA_ "SPN" SG_ 2566772222 EngVrblGeometryTurbo1ActuatorPos 2795;
BA_ "SAEDocument" SG_ 2566772222 EngVrblGeometryTurbo1ActuatorPos "J1939-71";
BA_ "SigType" SG_ 2566772222 EngVrblGmtryTrbArCtrlShtoffValve 5;
BA_ "SPN" SG_ 2566772222 EngVrblGmtryTrbArCtrlShtoffValve 2792;
BA_ "SAEDocument" SG_ 2566772222 EngVrblGmtryTrbArCtrlShtoffValve "J1939-71";
BA_ "SPN" SG_ 2566772222 EngTrb1ClclatedTurbineOutletTemp 2790;
BA_ "SAEDocument" SG_ 2566772222 EngTrb1ClclatedTurbineOutletTemp "J1939-71";
BA_ "SPN" SG_ 2633940734 CrnkAttmptCntOnPrsntStartAttempt 3671;
BA_ "SAEDocument" SG_ 2633940734 CrnkAttmptCntOnPrsntStartAttempt "J1939-71";
BA_ "SigType" SG_ 2633940734 EngIntakeManifoldPressCtrlMode 5;
BA_ "SPN" SG_ 2633940734 EngIntakeManifoldPressCtrlMode 5465;
BA_ "SAEDocument" SG_ 2633940734 EngIntakeManifoldPressCtrlMode "J1939-71";
BA_ "SigType" SG_ 2633940734 EngRotationDirection 4;
BA_ "SPN" SG_ 2633940734 EngRotationDirection 3669;
BA_ "SAEDocument" SG_ 2633940734 EngRotationDirection "J1939-71";
BA_ "SigType" SG_ 2633940734 EngRatedSpeed 1;
BA_ "SPN" SG_ 2633940734 EngRatedSpeed 189;
BA_ "SAEDocument" SG_ 2633940734 EngRatedSpeed "J1939-71";
BA_ "SigType" SG_ 2633940734 EngRatedPower 1;
BA_ "SPN" SG_ 2633940734 EngRatedPower 166;
BA_ "SAEDocument" SG_ 2633940734 EngRatedPower "J1939-71";
BA_ "SigType" SG_ 2566840318 Aftertreatment2ExhaustDewPoint 5;
BA_ "SPN" SG_ 2566840318 Aftertreatment2ExhaustDewPoint 3240;
BA_ "SAEDocument" SG_ 2566840318 Aftertreatment2ExhaustDewPoint "J1939-71";
BA_ "SigType" SG_ 2566840318 Aftertreatment2IntakeDewPoint 5;
BA_ "SPN" SG_ 2566840318 Aftertreatment2IntakeDewPoint 3239;
BA_ "SAEDocument" SG_ 2566840318 Aftertreatment2IntakeDewPoint "J1939-71";
BA_ "SigType" SG_ 2566840318 Aftertreatment1ExhaustDewPoint 5;
BA_ "SPN" SG_ 2566840318 Aftertreatment1ExhaustDewPoint 3238;
BA_ "SAEDocument" SG_ 2566840318 Aftertreatment1ExhaustDewPoint "J1939-71";
BA_ "SigType" SG_ 2566840318 Aftertreatment1IntakeDewPoint 5;
BA_ "SPN" SG_ 2566840318 Aftertreatment1IntakeDewPoint 3237;
BA_ "SAEDocument" SG_ 2566840318 Aftertreatment1IntakeDewPoint "J1939-71";
BA_ "SigType" SG_ 2566840318 Aftrtreatment1ExhaustGasMassFlow 1;
BA_ "SPN" SG_ 2566840318 Aftrtreatment1ExhaustGasMassFlow 3236;
BA_ "SAEDocument" SG_ 2566840318 Aftrtreatment1ExhaustGasMassFlow "J1939-71";
BA_ "SPN" SG_ 2566840318 EstEngPrsiticLossesPercentTorque 2978;
BA_ "SAEDocument" SG_ 2566840318 EstEngPrsiticLossesPercentTorque "J1939-71";
BA_ "SPN" SG_ 2566840318 EngnsDsrdOprtngSpdAsymmtryAdjstm 519;
BA_ "SAEDocument" SG_ 2566840318 EngnsDsrdOprtngSpdAsymmtryAdjstm "J1939-71";
BA_ "SPN" SG_ 2566840318 EnginesDesiredOperatingSpeed 515;
BA_ "SAEDocument" SG_ 2566840318 EnginesDesiredOperatingSpeed "J1939-71";
BA_ "SPN" SG_ 2566840318 NominalFrictionPercentTorque 514;
BA_ "SAEDocument" SG_ 2566840318 NominalFrictionPercentTorque "J1939-71";
BA_ "SigType" SG_ 2364539902 EstPumpingPercentTorque 1;
BA_ "SPN" SG_ 2364539902 EstPumpingPercentTorque 5398;
BA_ "SAEDocument" SG_ 2364539902 EstPumpingPercentTorque "J1939-71";
BA_ "SigType" SG_ 2364539902 ActlMaxAvailableEngPercentTorque 1;
BA_ "SPN" SG_ 2364539902 ActlMaxAvailableEngPercentTorque 3357;
BA_ "SAEDocument" SG_ 2364539902 ActlMaxAvailableEngPercentTorque "J1939-71";
BA_ "SigType" SG_ 2364539902 SCRThermalManagementActive 5;
BA_ "SPN" SG_ 2364539902 SCRThermalManagementActive 5400;
BA_ "SAEDocument" SG_ 2364539902 SCRThermalManagementActive "J1939-71";
BA_ "SigType" SG_ 2364539902 DPFThermalManagementActive 5;
BA_ "SPN" SG_ 2364539902 DPFThermalManagementActive 5399;
BA_ "SAEDocument" SG_ 2364539902 DPFThermalManagementActive "J1939-71";
BA_ "SigType" SG_ 2364539902 MmntaryEngMaxPowerEnableFeedback 5;
BA_ "SPN" SG_ 2364539902 MmntaryEngMaxPowerEnableFeedback 5021;
BA_ "SAEDocument" SG_ 2364539902 MmntaryEngMaxPowerEnableFeedback "J1939-71";
BA_ "SigType" SG_ 2364539902 VhcleAccelerationRateLimitStatus 5;
BA_ "SPN" SG_ 2364539902 VhcleAccelerationRateLimitStatus 2979;
BA_ "SAEDocument" SG_ 2364539902 VhcleAccelerationRateLimitStatus "J1939-71";
BA_ "SigType" SG_ 2364539902 AccelPedalPos2 1;
BA_ "SPN" SG_ 2364539902 AccelPedalPos2 29;
BA_ "SAEDocument" SG_ 2364539902 AccelPedalPos2 "J1939-71";
BA_ "SigType" SG_ 2364539902 RemoteAccelPedalPos 1;
BA_ "SPN" SG_ 2364539902 RemoteAccelPedalPos 974;
BA_ "SAEDocument" SG_ 2364539902 RemoteAccelPedalPos "J1939-71";
BA_ "SPN" SG_ 2364539902 EngPercentLoadAtCurrentSpeed 92;
BA_ "SAEDocument" SG_ 2364539902 EngPercentLoadAtCurrentSpeed "J1939-71";
BA_ "SigType" SG_ 2364539902 AccelPedalPos1 1;
BA_ "SPN" SG_ 2364539902 AccelPedalPos1 91;
BA_ "SAEDocument" SG_ 2364539902 AccelPedalPos1 "J1939-71";
BA_ "SigType" SG_ 2364539902 AccelPedal2LowIdleSwitch 4;
BA_ "SPN" SG_ 2364539902 AccelPedal2LowIdleSwitch 2970;
BA_ "SAEDocument" SG_ 2364539902 AccelPedal2LowIdleSwitch "J1939-71";
BA_ "SigType" SG_ 2364539902 RoadSpeedLimitStatus 5;
BA_ "SPN" SG_ 2364539902 RoadSpeedLimitStatus 1437;
BA_ "SAEDocument" SG_ 2364539902 RoadSpeedLimitStatus "J1939-71";
BA_ "SigType" SG_ 2364539902 AccelPedalKickdownSwitch 4;
BA_ "SPN" SG_ 2364539902 AccelPedalKickdownSwitch 559;
BA_ "SAEDocument" SG_ 2364539902 AccelPedalKickdownSwitch "J1939-71";
BA_ "SigType" SG_ 2364539902 AccelPedal1LowIdleSwitch 4;
BA_ "SPN" SG_ 2364539902 AccelPedal1LowIdleSwitch 558;
BA_ "SAEDocument" SG_ 2364539902 AccelPedal1LowIdleSwitch "J1939-71";
VAL_ 2566768638 EngAltDroopAuxInputSelectState 15 "Not available" 14 "SAE reserved" 1 "thru 1101  Control state is One of Alternate Droop Setting 1 through 13 in sequential order" 0 "Control state is Normal Droop Setting" ;
VAL_ 2566768638 EngAltDropRemoteAccelSelectState 15 "Not available" 14 "SAE reserved" 1 "thru 1101  Control state is One of Alternate Droop Setting 1 through 13 in sequential order" 0 "Control state is Normal Droop Setting" ;
VAL_ 2566768638 EngAltDroopAccel2SelectState 15 "Not available" 14 "SAE reserved" 1 "thru 1101  Controls state is One of Alternate Droop Setting 1 through 13 in sequential order" 0 "Controls state is Normal Droop Setting" ;
VAL_ 2566768638 EngAltDroopAccel1SelectState 15 "Not available" 14 "SAE reserved" 1 "thru 1101  Control state is one of Alternate Droop Setting 1 through 13 in sequential order" 0 "Control state is Normal Droop Setting" ;
VAL_ 2566768638 EngAltRatingSelectState 1 "Control state is Alternate Power Fueling 1" 0 "Control state is Maximum Power Fueling" ;
VAL_ 2566768638 EngAltLowIdleSelectState 3 "not available" 2 "SAE reserved" 1 "Alternate idle state" 0 "Normal idle state" ;
VAL_ 2566768638 EngMultiUnitSyncState 3 "Not available" 2 "SAE reserved" 1 "Control State is Functionality enabled on" 0 "Control State is Functionality disabled off" ;
VAL_ 2566768638 EngAuxGovernorState 3 "Not available" 2 "SAE reserved" 1 "Control State is Auxiliary Governor enabled" 0 "Control State is Auxiliary Governor disabled" ;
VAL_ 2365443326 HighLowBeamSwitch 3 "Not available do not change" 2 "Error" 1 "High Beam Selected" 0 "Low Beam Selected" ;
VAL_ 2365443326 HazardLightSwitch 3 "Not available do not change" 2 "Error" 1 "Hazard Lamps to be Flashing" 0 "Hazard Lamps to be Off" ;
VAL_ 2365443326 TurnSignalSwitch 2 "Right turn to be Flashing" 15 "Not available do not change" 14 "Error to include both left and right selected simultaneously" 3 "1101 Reserved" 1 "Left Turn to be Flashing" 0 "No Turn being signaled" ;
VAL_ 2365443326 MainLightSwitch 9 "1101 Reserved" 8 "Delayed Off  The position by which the operator selects that a certain set of lamps are to come On and then are to" 4 "0111 Reserved" 2 "Headlight On  The position by which the operator selects that the headlamps are to be on" 15 "Not available do not change" 14 "Error" 3 "Headlight and Park On  The position by which the operator selects that Both the Headlamps and the Park lamps" 1 "Park On  The position by which the operator selects that the park lamps are to be on" 0 "Off  The position by which the operator selects that none of the lamps are to be on" ;
VAL_ 2365443326 WorkLightSwitch 4 "Work Light Combination 4 On  The position by which the operator selects that the lamps in the combination" 2 "Work Light Combination 2 On  The position by which the operator selects that the lamps in the combination" 15 "Not available do not change" 14 "Error" 3 "Work Light Combination 3 On  The position by which the operator selects that the lamps in the combination" 1 "Work Light Combination 1 On  The position by which the operator selects that the lamps in the combination" 0 "Off  The position by which the operator selects that none of the work lamps are to be on" ;
VAL_ 2566802686 BlackOutWorkLampSelect 3 "Not Supported" 2 "Reserved" 1 "On" 0 "Off" ;
VAL_ 2566802686 NightVisionIlluminatorSelect 3 "Not Supported" 2 "Reserved" 1 "On" 0 "Off" ;
VAL_ 2566802686 BlackOutBrake_StopLampSelect 3 "Not Supported" 2 "Reserved" 1 "On" 0 "Off" ;
VAL_ 2566802686 ConvoyDrivingLampSelect 3 "Not Supported" 2 "Reserved" 1 "On" 0 "Off" ;
VAL_ 2566802686 ConvoyLampSelect 3 "Not Supported" 2 "Reserved" 1 "On" 0 "Off" ;
VAL_ 2566802686 FrontBlackOutMarkerLampSelect 3 "Not Supported" 2 "Reserved" 1 "On" 0 "Off" ;
VAL_ 2566802686 RearBlackOutMarkerSelect 3 "Not Supported" 2 "Reserved" 1 "On" 0 "Off" ;
VAL_ 2566774014 SlowVesselModeStatus 3 "Take no action" 2 "Reserved" 1 "Slow vessel mode is ACTIVE" 0 "Slow vessel mode is OFF" ;
VAL_ 2566774014 TrollingModeStatus 3 "Take no action" 2 "Reserved" 1 "Trolling mode is ACTIVE" 0 "Trolling mode is OFF" ;
VAL_ 2566774014 EngThrttlSynchrnzationModeStatus 15 "Take no action" 4 "Synchronized Master" 3 "Synchronized Starboard" 2 "Synchronized Port" 1 "Synchronized Center" 0 "Not Synchronized" ;
VAL_ 2432595710 DisplayDeadbands 15 "Not Available" 3 "1110 Reserved" 2 "Wide  / 24mm" 1 "Standard  / 12mm" 0 "Narrow  / 45mm" ;
VAL_ 2432595710 LEDPatternCtrl 15 "Not Available" 3 "1110 Reserved" 2 "7 Channel" 1 "Offset" 0 "5 Channel" ;
VAL_ 2432595710 LEDDisplayDeadbandCtrl 15 "Not Available or Not applicable" 5 "1110 Reserved" 4 "/ 1 mm 0003 feet 004 inches" 3 "/ 5 mm 0017 feet 02 inches" 2 "/ 24 mm 0080 feet 096 inches" 1 "/ 12 mm 0040 feet 045 inches" 0 "/ 45 mm 0015 feet 018 inches" ;
VAL_ 2432595710 LEDDisplayModeCtrl 15 "Not Available or Not Applicable" 3 "1110 Reserved" 2 "Center OnGrade Display Mode 2  7 CHANNEL" 1 "Offset OnGrade Display Mode" 0 "Center OnGrade Display Mode 1  5 CHANNEL" ;
VAL_ 2432595710 LEDDisplayData1 254 "Error" 159 "No data ie no laser strikes" 149 "High Coarse" 148 "High Medium/Coarse" 147 "High Medium" 146 "High Medium/Fine" 145 "High Fine" 144 "On Grade" 132 "Low Fine" 131 "Low Medium/Fine" 130 "Low Medium" 129 "Low Medium/Coarse" 128 "Low Coarse" 32 "Low Coarse LED on" 16 "Low Fine LED on" 8 "Ongrade LED on" 4 "High Fine LED on" 2 "High Coarse LED on" ;
VAL_ 2365485566 LaserTracerInformation 32 "Curb 1  yes" 16 "Stringline 1  yes" 8 "Previous pass 1  yes" 4 "Valid target 1  yes" 2 "Laser is ready" 1 "Laser power is on" ;
VAL_ 2365485566 LEDDisplayData2 64 "Right LED on" 32 "Left LED on" 16 "Down LED on" 8 "Up LED on" 4 "Ongrade C LED on" 2 "Ongrade B LED on" 1 "Ongrade A LED on" ;
VAL_ 2364542462 StElvtnSensor2ReferenceElevation 3 "Dont Care / Take No Action" 2 "Reserved" 1 "Set Reference Elevation" 0 "Do not Set Reference Elevation" ;
VAL_ 2364542462 StElvtnSensor1ReferenceElevation 3 "Dont Care / Take No Action" 2 "Reserved" 1 "Set Reference Elevation" 0 "Do not Set Reference Elevation" ;
VAL_ 2364542462 SdshftDsrdBldeOffsetOperatorCtrl 15 "Not Installed" 14 "Error Indicator" 4 "1101 Reserved" 3 "Automatic Operator Control Request" 2 "Manual Operator Control Request" 0 "No Operator Control Request" 1 "Momentary Operator Control Request" ;
VAL_ 2364542462 SdshiftBladeCtrlModeOperatorCtrl 15 "Not installed" 14 "Error Indicator" 2 "Decrement Operator Control Request" 0 "No Operator Control Request" 1 "Increment Operator Control Request" ;
VAL_ 2364542462 RghtDsredBladeOffsetOperatorCtrl 15 "Not installed" 14 "Error Indicator" 3 "1101 Reserved" 2 "Decrement Operator Control Request" 0 "No Operator Control Request" 1 "Increment Operator Control Request" ;
VAL_ 2364542462 LftDsiredBladeOffsetOperatorCtrl 15 "Not installed" 14 "Error Indicator" 3 "1101 Reserved" 2 "Decrement Operator Control Request" 0 "No Operator Control Request" 1 "Increment Operator Control Request" ;
VAL_ 2364542462 RightBladeCtrlModeOperatorCtrl 15 "Not Installed" 14 "Error Indicator" 3 "Automatic Operator Control Request" 2 "Manual Operator Control Request" 0 "No Change" 1 "Momentary Operator Control Request" ;
VAL_ 2364542462 LeftBladeCtrlModeOperatorCtrl 15 "Not Installed" 14 "Error Indicator" 12 "1101 Reserved" 3 "Automatic Operator Control Request" 2 "Manual Operator Control Request" 0 "No Change" 1 "Momentary Operator Control Request" ;
VAL_ 2364542462 BladeAutoModeCmd 4 "Auto Not Allowed  Auto mode is not allowed under any condition" 3 "Service Mode  Auto mode is permitted only for special services such as calibrations" 2 "Suspend Auto  Auto mode is temporarily not allowed and the control issuing this command wants the primary" 1 "Activity Allows Auto  Auto mode permitted only if the primary control system detects operator activity The control" 0 "Auto Allowed  Auto mode permitted as appropriate auto button was pushed or directly returned from Suspend" ;
VAL_ 2364542462 DesiredGradeOffsetSwitch 15 "Not installed" 14 "Error Indicator" 2 "Decrement button pressed" 0 "No button pressed" 1 "Increment button pressed" ;
VAL_ 2364542462 BladeCtrlModeSwitch 15 "Not Installed" 14 "Error Indicator" 3 "Automatic button pressed" 2 "Manual button pressed" 0 "No button pressed" 1 "Mode button pressed" ;
VAL_ 2633883646 FrontWheelDriveActuatorStatus 3 "Not Available" 2 "Error" 1 "Front Wheel Drive Actuator engaged" 0 "Front Wheel Drive Actuator not engaged" ;
VAL_ 2633880062 FMSstandardRequestsSupported 3 "Dont care" 2 "Reserved" 1 "On request mode is supported" 0 "On request mode is not supported" ;
VAL_ 2633880062 FMSstandardDiagnosticsSupported 3 "Dont care" 2 "Reserved" 1 "Diagnostics Is Supported" 0 "Diagnostics Is Not Supported" ;
VAL_ 2566806526 LnDpartureIndicationEnableStatus 3 "Not Used" 2 "Reserved" 1 "Lane Departure Indication enabled" 0 "Lane Departure indication disabled" ;
VAL_ 2566806526 LaneTrackingStatusLeftSide 3 "Dont care/Take no action" 2 "Reserved" 1 "Tracking Left side" 0 "Not Tracking Left side" ;
VAL_ 2566806526 LaneTrackingStatusRightSide 3 "Dont Care/take no action" 2 "Reserved" 1 "Tracking Right side" 0 "Not Tracking Right side" ;
VAL_ 2431649790 LaneDepartureImminentLeftSide 3 "Not used" 2 "Reserved" 1 "Imminent" 0 "Not imminent" ;
VAL_ 2431649790 LaneDepartureImminentRightSide 3 "Not Used" 2 "Reserved" 1 "Imminent" 0 "Not imminent" ;
VAL_ 2431649790 LaneDepartureRight 3 "Take no action" 2 "Reserved" 1 "Middle of the vehicle departs the lane to the right side" 0 "Middle of the vehicle does not depart the lane to the right side" ;
VAL_ 2431649790 LaneDepartureLeft 3 "Take no action" 2 "Reserved" 1 "Middle of the vehicle departs the lane to the left side" 0 "Middle of the vehicle does not depart the lane to the left side" ;
VAL_ 2633929214 EngFuelLeakage2 3 "Not available" 2 "Error" 1 "leakage detected" 0 "no leakage detected" ;
VAL_ 2633929214 EngFuelLeakage1 3 "Not available" 2 "Error" 1 "leakage detected" 0 "no leakage detected" ;
VAL_ 2566831614 FanDriveState 15 "Not available" 14 "Other" 13 "Engine brake" 12 "Timer" 11 "A/C system" 10 "Transmission retarder" 9 "Manual control" 8 "Reverse Operation" 7 "Default Operation" 6 "Excessive hydraulic oil temperature" 5 "Excessive transmission oil temperature" 4 "Excessive engine coolant temperature" 3 "Excessive engine oil temperature" 2 "Excessive engine air temperature" 1 "Engine systemGeneral" 0 "Fan off" ;
VAL_ 2566820094 EngTorqueLimitFeature 7 "Not available" 4 "Current torque rating" 3 "Previous torque rating rating prior to the current rating" 2 "First torque rating" 1 "Highest torque rating" 0 "Reserved" ;
VAL_ 2566820094 TorqueLimitingFeatureStatus 3 "Not available" 2 "Error" 1 "Enabled" 0 "Disabled" ;
VAL_ 2566802174 TrnsRverseGearShiftInhibitStatus 3 "Not Available" 2 "Error" 1 "Reverse gear shifts are currently inhibited" 0 "Reverse gear shifts are currently allowed" ;
VAL_ 2566802174 TransWarningIndicator 3 "Not available" 2 "Transmission Warning Indicator is flashing" 1 "Transmission Warning Indicator is on continuously" 0 "Transmission Warning Indicator is off" ;
VAL_ 2566802174 TransMode8Indicator 3 "Take no action" 2 "Reserved" 1 "Enable" 0 "Disable" ;
VAL_ 2566802174 TransMode7Indicator 3 "Take no action" 2 "Reserved" 1 "Enable" 0 "Disable" ;
VAL_ 2566802174 TransMode6Indicator 3 "Take no action" 2 "Reserved" 1 "Enable" 0 "Disable" ;
VAL_ 2566802174 TransMode5Indicator 3 "Take no action" 2 "Reserved" 1 "Enable" 0 "Disable" ;
VAL_ 2566802174 TransMode1Indicator 3 "Not available" 2 "Error" 1 "Transmission Mode 1 Active" 0 "Transmission Mode 1 not active" ;
VAL_ 2566802174 TransMode2Indicator 3 "Not available" 2 "Error" 1 "Transmission Mode 2 Active" 0 "Transmission Mode 2 not active" ;
VAL_ 2566802174 TransMode3Indicator 3 "Not available" 2 "Error" 1 "Transmission Mode 3 Active" 0 "Transmission Mode 3 not active" ;
VAL_ 2566802174 TransMode4Indicator 3 "Not available" 2 "Error" 1 "Transmission Mode 4 Active" 0 "Transmission Mode 4 not active" ;
VAL_ 2566802174 TransShiftInhibitIndicator 3 "Take no action" 2 "Reserved" 1 "Active shift is inhibited" 0 "Inactive shift is not inhibited" ;
VAL_ 2566802174 TransEngCrankEnable 3 "Not available" 2 "Error" 1 "Cranking enabled engine cranking is allowed by the transmission" 0 "Cranking disabled engine cranking is prohibited by the transmission" ;
VAL_ 2566802174 ActiveShiftConsoleIndicator 3 "Not available" 2 "Reserved" 1 "Secondary shift console is active" 0 "Primary shift console is active" ;
VAL_ 2566802174 TransReadyForBrakeRelease 3 "Not available" 2 "Error" 1 "Transmission Ready for Brake Release" 0 "Transmission Not Ready for Brake Release" ;
VAL_ 2566802174 TrnsRqstedRangeDisplayFlashState 3 "Take no action" 2 "Reserved" 1 "Active Transmission Requested Range display should be flashing" 0 "Inactive Transmission Requested Range display should not be flashing" ;
VAL_ 2566802174 TrnsRqstedRangeDisplayBlankState 3 "Take no action" 2 "Reserved" 1 "Active Transmission Requested Range display should be blanked" 0 "Inactive Transmission Requested Range display should not be blanked" ;
VAL_ 2566802174 TransServiceIndicator 3 "Not available" 2 "Transmission Service Indicator is flashing" 1 "Transmission Service Indicator is on continuously" 0 "Transmission Service Indicator is off" ;
VAL_ 2633942014 TransForwardDirectionSwitch 3 "Not available" 2 "Error" 1 "On" 0 "Off" ;
VAL_ 2633942014 TransNeutralSwitch 3 "Not available" 2 "Error" 1 "On" 0 "Off" ;
VAL_ 2633942014 TransReverseDirectionSwitch 3 "Not available" 2 "Error" 1 "On" 0 "Off" ;
VAL_ 2633942014 TransLowRangeSenseSwitch 3 "Not available" 2 "Error" 1 "On" 0 "Off" ;
VAL_ 2633942014 TransHighRangeSenseSwitch 3 "Not available" 2 "Error" 1 "On" 0 "Off" ;
VAL_ 2633943038 TransInertiaBrakeActuator 3 "Not available" 2 "Error" 1 "On" 0 "Off" ;
VAL_ 2633943038 TransDefuelActuator 3 "Not available" 2 "Error" 1 "On" 0 "Off" ;
VAL_ 2633943038 TransLockupClutchActuator 3 "Not available" 2 "Error" 1 "On" 0 "Off" ;
VAL_ 2633943038 TransClutchActuator 3 "Not available" 2 "Error" 1 "On" 0 "Off" ;
VAL_ 2633943038 TransSplitterIndirectActuator 3 "Not available" 2 "Error" 1 "On" 0 "Off" ;
VAL_ 2633943038 TransSplitterDirectActuator 3 "Not available" 2 "Error" 1 "On" 0 "Off" ;
VAL_ 2633943038 TransRangeLowActuator 3 "Not available" 2 "Error" 1 "On" 0 "Off" ;
VAL_ 2633943038 TransRangeHighActuator 3 "Not available" 2 "Error" 1 "On" 0 "Off" ;
VAL_ 2633943038 TransShiftFingerGearActuator2 3 "Not available" 2 "Error" 1 "On" 0 "Off" ;
VAL_ 2633943038 TransShiftFingerRailActuator2 3 "Not available" 2 "Error" 1 "On" 0 "Off" ;
VAL_ 2633943038 TransShiftFingerGearActuator1 3 "Not available" 2 "Error" 1 "On" 0 "Off" ;
VAL_ 2633943038 TransShiftFingerRailActuator1 3 "Not available" 2 "Error" 1 "On" 0 "Off" ;
VAL_ 2633943038 TrnsShftFngerCenterRailIndicator 3 "Not available" 2 "Error" 1 "On" 0 "Off" ;
VAL_ 2633943038 TrnsShftFngerEngagementIndicator 3 "Not available" 2 "Error" 1 "On" 0 "Off" ;
VAL_ 2633943038 TransShiftFingerNeutralIndicator 3 "Not available" 2 "Error" 1 "On" 0 "Off" ;
VAL_ 2364539646 MomentaryEngMaxPowerEnable 3 "not available" 2 "fault" 1 "momentarily requesting maximum power available" 0 "not requesting maximum power available" ;
VAL_ 2364539646 ProgressiveShiftDisable 2 "Reserved" 3 "Take no action" 1 "Progressive shift is disabled" 0 "Progressive shift is not disabled" ;
VAL_ 2364539646 EngMomentaryOverspeedEnable 3 "Take no action" 2 "Reserved" 1 "Momentary engine overspeed is enabled" 0 "Momentary engine overspeed is disabled" ;
VAL_ 2364539646 TrnsTrqCnvrtrLckpTrnstnInProcess 3 "Not available" 2 "Error" 1 "Transition is in process" 0 "Transition is not in process" ;
VAL_ 2364539646 TransShiftInProcess 3 "Not available" 2 "Error" 1 "Shift in process" 0 "Shift is not in process" ;
VAL_ 2364539646 TrnsTorqueConverterLockupEngaged 3 "Not available" 2 "Error" 1 "Torque converter lockup engaged" 0 "Torque converter lockup disengaged" ;
VAL_ 2364539646 TransDrivelineEngaged 3 "Not available" 2 "Error" 1 "Driveline engaged" 0 "Driveline disengaged" ;
VAL_ 2565868542 TypeOfSteerTrans 15 "Not available" 3 "Hybrid steering transmission" 2 "Purely electric steering transmission" 1 "Purely hydraulic steering transmission" 0 "Purely mechanical steering transmission" ;
VAL_ 2565868542 TypeOfSteerForces 15 "Not Available" 3 "Self tracking steering equipment" 2 "Full power steering equipment" 1 "Power assisted steering equipment" 0 "Manual steering equipment" ;
VAL_ 2565868542 SteerType 15 "Not Available" 1 "Auxiliary steering equipment" 0 "Main steering system" ;
VAL_ 2565868542 SteerableLiftAxleLoweringInhibit 3 "Not available" 2 "Reserved" 1 "Lowering inhibited" 0 "Lowering allowed" ;
VAL_ 2565868542 StatusOfSteerAxle 15 "Not available" 5 "Axle steering in special mode diagnosis calibration mode" 4 "Axle not active because of an error adhesion steering" 3 "Axle centered because of an error" 2 "Axle centered" 1 "Axle steering active" 0 "Axle steering not active adhesion steering" ;
VAL_ 2633941758 TransOutputRetarder 3 "Not available" 2 "Error" 1 "On" 0 "Off" ;
VAL_ 2565865726 RetarderRoadSpeedExceededStatus 3 "Dont care/Take no action" 2 "Reserved" 1 "Road speed is above threshold and retarder is allowed to be activated" 0 "Road speed is below threshold" ;
VAL_ 2565865726 RetarderRoadSpeedLimitSwitch 3 "Not Available" 2 "Error Indicator" 1 "Road speed limiting by retarder is enabled The road speed that the retarder will limit will be determined when the" 0 "Road speed limiting by retarder is disabled" ;
VAL_ 2565865726 RetarderRequestingBrakeLight 3 "Not available/Take no action" 2 "Reserved" 1 "Retarder is requesting that the brake lights are illuminated" 0 "Retarder is not requesting that the brake lights are illuminated" ;
VAL_ 2565865726 EngCoolantLoadIncrease 3 "Not available" 2 "Error" 1 "Coolant load increase possible" 0 "No coolant load increase" ;
VAL_ 2565865726 RetarderEnableShiftAssistSwitch 3 "Not available" 2 "Error" 1 "Retarder  shift assist enabled" 0 "Retarder  shift assist disabled" ;
VAL_ 2565865726 RetarderEnableBrakeAssistSwitch 3 "Not available" 2 "Error" 1 "Retarder  brake assist enabled" 0 "Retarder  brake assist disabled" ;
VAL_ 2633935358 EngExhstGsOxygnSnsrClsdLpOprtion 3 "Dont Care/take no action" 2 "Reserved" 1 "Engine using the Exhaust Gas Oxygen sensor for a closed loop operation" 0 "Engine not using the Exhaust Gas Oxygen sensor open loop" ;
VAL_ 2365447166 Jystick3GripXAxisDetentPosStatus 3 "Not Available" 2 "Error Indicator" 1 "In the Detent Position" 0 "Not in the Detent Position" ;
VAL_ 2365447166 Jystick3GripYAxisDetentPosStatus 3 "Not Available" 2 "Error Indicator" 1 "In the Detent Position" 0 "Not in the Detent Position" ;
VAL_ 2365447166 Jystick3ThetaAxisDetentPosStatus 3 "Not Available" 2 "Error Indicator" 1 "In the Detent Position" 0 "Not in the Detent Position" ;
VAL_ 2365447166 Jystck3ThtAxsClckwsPstvPosStatus 3 "Not Available" 2 "Error Indicator" 1 "On positive side of Neutral" 0 "Not on Positive side of Neutral" ;
VAL_ 2365447166 Jystck3ThetaAxisNeutralPosStatus 3 "Not Available" 2 "Error Indicator" 1 "In Neutral Position" 0 "Not in Neutral Position" ;
VAL_ 2365447166 Jystck3GrpYAxsLvrFrwrdPstvPsStts 3 "Not Available" 2 "Error Indicator" 1 "On positive side of Neutral" 0 "Not on Positive side of Neutral" ;
VAL_ 2365447166 Jystck3GrpYAxsLvrBckNgtvPsStatus 3 "Not Available" 2 "Error Indicator" 1 "On negative side of Neutral" 0 "Not on negative side of Neutral" ;
VAL_ 2365447166 Jystck3GripYAxisNeutralPosStatus 3 "Not Available" 2 "Error Indicator" 1 "In Neutral Position" 0 "Not in Neutral Position" ;
VAL_ 2365447166 Jystck3GrpXAxsLvrRghtPstvPsSttus 3 "Not Available" 2 "Error Indicator" 1 "On positive side of Neutral" 0 "Not on Positive side of Neutral" ;
VAL_ 2365447166 Jystck3GrpXAxsLvrLftNgtvPsStatus 3 "Not Available" 2 "Error Indicator" 1 "On negative side of Neutral" 0 "Not on negative side of Neutral" ;
VAL_ 2365447166 Jystck3GripXAxisNeutralPosStatus 3 "Not Available" 2 "Error Indicator" 1 "On negative side of Neutral" 0 "Not on negative side of Neutral" ;
VAL_ 2365447166 Jystck3ThtAxsCntrClckwsNgtvPsStt 3 "Not Available" 2 "Error Indicator" 1 "On negative side of Neutral" 0 "Not on negative side of Neutral" ;
VAL_ 2365446654 Jystick2GripXAxisDetentPosStatus 3 "Not Available" 2 "Error Indicator" 1 "In the Detent Position" 0 "Not in the Detent Position" ;
VAL_ 2365446654 Jystick2GripYAxisDetentPosStatus 3 "Not Available" 2 "Error Indicator" 1 "In the Detent Position" 0 "Not in the Detent Position" ;
VAL_ 2365446654 Jystick2ThetaAxisDetentPosStatus 3 "Not Available" 2 "Error Indicator" 1 "In the Detent Position" 0 "Not in the Detent Position" ;
VAL_ 2365446654 Jystck2ThtAxsClckwsPstvPosStatus 3 "Not Available" 2 "Error Indicator" 1 "On positive side of Neutral" 0 "Not on Positive side of Neutral" ;
VAL_ 2365446654 Jystck2ThetaAxisNeutralPosStatus 3 "Not Available" 2 "Error Indicator" 1 "In Neutral Position" 0 "Not in Neutral Position" ;
VAL_ 2365446654 Jystck2GrpYAxsLvrFrwrdPstvPsStts 3 "Not Available" 2 "Error Indicator" 1 "On positive side of Neutral" 0 "Not on Positive side of Neutral" ;
VAL_ 2365446654 Jystck2GrpYAxsLvrBckNgtvPsStatus 3 "Not Available" 2 "Error Indicator" 1 "On negative side of Neutral" 0 "Not on negative side of Neutral" ;
VAL_ 2365446654 Jystck2GripYAxisNeutralPosStatus 3 "Not Available" 2 "Error Indicator" 1 "In Neutral Position" 0 "Not in Neutral Position" ;
VAL_ 2365446654 Jystck2GrpXAxsLvrRghtPstvPsSttus 3 "Not Available" 2 "Error Indicator" 1 "On positive side of Neutral" 0 "Not on Positive side of Neutral" ;
VAL_ 2365446654 Jystck2GrpXAxsLvrLftNgtvPsStatus 3 "Not Available" 2 "Error Indicator" 1 "On negative side of Neutral" 0 "Not on negative side of Neutral" ;
VAL_ 2365446654 Jystck2GripXAxisNeutralPosStatus 3 "Not Available" 2 "Error Indicator" 1 "On negative side of Neutral" 0 "Not on negative side of Neutral" ;
VAL_ 2365446654 Jystck2ThtAxsCntrClckwsNgtvPsStt 3 "Not Available" 2 "Error Indicator" 1 "On negative side of Neutral" 0 "Not on negative side of Neutral" ;
VAL_ 2365446142 Jystick1GripXAxisDetentPosStatus 3 "Not Available" 2 "Error Indicator" 1 "In the Detent Position" 0 "Not in the Detent Position" ;
VAL_ 2365446142 Jystick1GripYAxisDetentPosStatus 3 "Not Available" 2 "Error Indicator" 1 "In the Detent Position" 0 "Not in the Detent Position" ;
VAL_ 2365446142 Jystick1ThetaAxisDetentPosStatus 3 "Not Available" 2 "Error Indicator" 1 "In the Detent Position" 0 "Not in the Detent Position" ;
VAL_ 2365446142 Jystck1ThtAxsClckwsPstvPosStatus 3 "Not Available" 2 "Error Indicator" 1 "On positive side of Neutral" 0 "Not on Positive side of Neutral" ;
VAL_ 2365446142 Jystck1ThetaAxisNeutralPosStatus 3 "Not Available" 2 "Error Indicator" 1 "In Neutral Position" 0 "Not in Neutral Position" ;
VAL_ 2365446142 Jystck1GrpYAxsLvrFrwrdPstvPsStts 3 "Not Available" 2 "Error Indicator" 1 "On positive side of Neutral" 0 "Not on Positive side of Neutral" ;
VAL_ 2365446142 Jystck1GrpYAxsLvrBckNgtvPsStatus 3 "Not Available" 2 "Error Indicator" 1 "On negative side of Neutral" 0 "Not on negative side of Neutral" ;
VAL_ 2365446142 Jystck1GripYAxisNeutralPosStatus 3 "Not Available" 2 "Error Indicator" 1 "In Neutral Position" 0 "Not in Neutral Position" ;
VAL_ 2365446142 Jystck1GrpXAxsLvrRghtPstvPsSttus 3 "Not Available" 2 "Error Indicator" 1 "On positive side of Neutral" 0 "Not on Positive side of Neutral" ;
VAL_ 2365446142 Jystck1GrpXAxsLvrLftNgtvPsStatus 3 "Not Available" 2 "Error Indicator" 1 "On negative side of Neutral" 0 "Not on negative side of Neutral" ;
VAL_ 2365446142 Jystck1GripXAxisNeutralPosStatus 3 "Not Available" 2 "Error Indicator" 1 "In Neutral Position" 0 "Not in Neutral Position" ;
VAL_ 2365446142 Jystck1ThtAxsCntrClckwsNgtvPsStt 3 "Not Available" 2 "Error Indicator" 1 "On negative side of Neutral" 0 "Not on negative side of Neutral" ;
VAL_ 2566810366 FuelPumpPrimerStatus 3 "Unavailable" 2 "Error" 1 "On" 0 "Off" ;
VAL_ 2566810366 EngVentilationStatus 4 "Reserved for SAE assignment" 7 "Not available or not installe" 6 "Not able to determine if sufficiently vented" 5 "Reserved for SAE assignment" 3 "Currently venting engine cranks w/o gas or ignition to clear intake and exhaust systems with air" 2 "Ventilation delay delay without cranking between ventilation and start engine states" 1 "Ventilation needed combustible gases may be present in intake and exhaust systems" 0 "Sufficiently vented all combustible gases have been evacuated from intake and exhaust systems" ;
VAL_ 2566810366 EngCoolantPreheatedState 3 "Not available or not installed" 2 "Unable to determine engine coolant preheated sufficiently" 1 "Sufficiently preheated" 0 "Not sufficiently preheated" ;
VAL_ 2566810366 EngOilPreHeatedState 3 "Not available or not installed" 2 "Unable to determine if engine oil is preheated sufficiently" 1 "Sufficiently preheated" 0 "Not sufficiently preheated" ;
VAL_ 2566810366 EngOilPrimingState 3 "Not available or not installed" 2 "Unable to determine if sufficiently lubricated" 1 "Sufficiently lubricated" 0 "Not sufficiently lubricated" ;
VAL_ 2566810366 EngOilPrimingPumpSwitch 3 "Not available or not installed" 2 "Error" 1 "On" 0 "Off" ;
VAL_ 2633929726 SafetyWireStatus 3 "Not available" 2 "Error" 1 "Safety wire has been activated" 0 "Safety wire has not been activated" ;
VAL_ 2566772222 EngVriableGeometryTurbo1CtrlMode 3 "not available" 2 "SAE reserved" 1 "closed loop" 0 "open loop" ;
VAL_ 2566772222 EngVrblGmtryTrbArCtrlShtoffValve 3 "Not available" 2 "Reserved" 1 "VGT Air Control Shutoff Valve is On" 0 "VGT Air Control Shutoff Valve is Off" ;
VAL_ 2633940734 EngIntakeManifoldPressCtrlMode 3 "Not available" 2 "SAE reserved" 1 "Closed loop" 0 "Open loop" ;
VAL_ 2633940734 EngRotationDirection 3 "Not Available" 2 "Reserved" 1 "ClockWise CW" 0 "CounterClockWise CCW" ;
VAL_ 2566840318 Aftertreatment2ExhaustDewPoint 3 "Not available" 2 "Error" 1 "Exceeded the dew point" 0 "Not exceeded the dew point" ;
VAL_ 2566840318 Aftertreatment2IntakeDewPoint 3 "Not available" 2 "Error" 1 "Exceeded the dew point" 0 "Not exceeded the dew point" ;
VAL_ 2566840318 Aftertreatment1ExhaustDewPoint 3 "Not available" 2 "Error" 1 "Exceeded the dew point" 0 "Not exceeded the dew point" ;
VAL_ 2566840318 Aftertreatment1IntakeDewPoint 3 "Not available" 2 "Error" 1 "Exceeded the dew point" 0 "Not exceeded the dew point" ;
VAL_ 2364539902 SCRThermalManagementActive 3 "Dont care" 2 "Reserved" 1 "SCR Thermal Management is active" 0 "SCR Thermal Management is not active" ;
VAL_ 2364539902 DPFThermalManagementActive 3 "Dont care" 2 "Reserved" 1 "DPF Thermal Management is active" 0 "DPF Thermal Management is not active" ;
VAL_ 2364539902 MmntaryEngMaxPowerEnableFeedback 3 "dont care" 2 "reserved" 1 "supported" 0 "disabled" ;
VAL_ 2364539902 VhcleAccelerationRateLimitStatus 3 "Not available" 2 "Reserved" 1 "Limit active" 0 "Limit not active" ;
VAL_ 2364539902 AccelPedal2LowIdleSwitch 3 "Not available" 2 "Error" 1 "Accelerator pedal 2 in low idle condition" 0 "Accelerator pedal 2 not in low idle condition" ;
VAL_ 2364539902 RoadSpeedLimitStatus 3 "Not available" 2 "Error" 1 "Not Active" 0 "Active" ;
VAL_ 2364539902 AccelPedalKickdownSwitch 3 "Not available" 2 "Error" 1 "Kickdown active" 0 "Kickdown passive" ;
VAL_ 2364539902 AccelPedal1LowIdleSwitch 3 "Not available" 2 "Error" 1 "Accelerator pedal 1 in low idle condition" 0 "Accelerator pedal 1 not in low idle condition" ;
